VERSION ""

NS_ :

BS_:
BU_: ME SC01 BMS01 BMS PT
VAL_TABLE_ CMBPressureState 1 "ENABLE" 0 "DISABLE" ;
VAL_TABLE_ cmbSM29TempIndex 255 "SNA" ;
VAL_TABLE_ contactorStateRabbit 5 "FAILURE" 4 "CLOSE" 3 "EXT_ISO_TEST" 2 "AUX_CLOSE" 1 "INT_ISO_TEST" 0 "OPEN" ;
VAL_TABLE_ microsarOsStackUsage 255 "SNA" ;
VAL_TABLE_ CoolantFluidLevelEnum 3 "FLUIDLEVEL_ERROR" 2 "FLUIDLEVEL_OIL" 1 "FLUIDLEVEL_AIR" 0 "FLUIDLEVEL_SNA" ;
VAL_TABLE_ EEPROM_BlockStatus 8 "NVM_REQ_RESTORED_FROM_ROM" 7 "NVM_REQ_REDUNDANCY_FAILED" 6 "NVM_REQ_CANCELED" 5 "NVM_REQ_NV_INVALIDATED" 4 "NVM_REQ_BLOCK_SKIPPED" 3 "NVM_REQ_INTEGRITY_FAILED" 2 "NVM_REQ_PENDING" 1 "NVM_REQ_NOT_OK" 0 "NVM_REQ_OK" ;
VAL_TABLE_ PerformanceMode 1 "High Performance" 0 "Normal" ;
VAL_TABLE_ adcDriverFail 12 "ADCDRIVER_SBCSUPPLY_FF" 11 "ADCDRIVER_MUX960_FF" 10 "ADCDRIVER_MUX910_FF" 9 "ADCDRIVER_UNDEF" 8 "ADCDRIVER_ADCVAR" 7 "ADCDRIVER_SLEEP_FF" 6 "ADCDRIVER_PYRO_FF" 5 "ADCDRIVER_MUX710_FF" 4 "ADCDRIVER_MUX440_FF" 3 "ADCDRIVER_MUX302A_FF" 2 "ADCDRIVER_MUX301B_FF" 1 "ADCDRIVER_MUX301A_FF" 0 "ADCDRIVER_NO_ISSUE" ;
VAL_TABLE_ activeIsoTestState 4 "ISOACTV_COMPLETE" 3 "ISOACTV_TIMEOUT" 2 "ISOACTV_PENDING" 1 "ISOACTV_INIT" 0 "ISOACTV_OFF" ;
VAL_TABLE_ pyroStateTable 7 "PYRO_FIRE" 6 "PYRO_DIAG_PASS" 5 "PYRO_DIAG_FAIL" 4 "PYRO_DIAG_LS_ON" 3 "PYRO_DIAG_OPEN" 2 "PYRO_DIAG_HS_ON" 1 "PYRO_DIAG_INIT" 0 "PYRO_INACTIVE" ;
VAL_TABLE_ storeCalibrationOptions 1 "CALIBRATIONS_STORE_PRESENT" 0 "CALIBRATIONS_REVERT_TO_INITIAL" ;
VAL_TABLE_ uint1_t 1 "TRUE" 0 "FALSE" ;
VAL_TABLE_ uint2_t 3 "SNA" ;
VAL_TABLE_ MIL 3 "MIL_SNA" 1 "MIL_ON" 0 "MIL_OFF" ;
VAL_TABLE_ DebugSpeed 3 "DEBUGSPEED_SLOW" 2 "DEBUGSPEED_MEDIUM" 1 "DEBUGSPEED_FAST" 0 "DEBUGSPEED_AUTO" ;
VAL_TABLE_ NMStartupReason 7 "NM_STARTUP_INVALID" 6 "NM_STARTUP_RQ" 5 "NM_STARTUP_CAN" 4 "NM_STARTUP_THERMALEVENT" 3 "NM_STARTUP_AUXCONTACTORS" 2 "NM_STARTUP_CONTACTORS" 1 "NM_STARTUP_KEY" 0 "NM_STARTUP_NOSTARTUP" ;
VAL_TABLE_ OCVRecalibration 255 "OCVRECALIBRATION_INVALID" 1 "OCVRECALIBRATION_ACTIVE" 0 "OCVRECALIBRATION_INACTIVE" ;
VAL_TABLE_ ASCII 90 "'Z'" 89 "'Y'" 88 "'X'" 87 "'W'" 86 "'V'" 85 "'U'" 84 "'T'" 83 "'S'" 82 "'R'" 81 "'Q'" 80 "'P'" 79 "'O'" 78 "'N'" 77 "'M'" 76 "'L'" 75 "'K'" 74 "'J'" 73 "'I'" 72 "'H'" 71 "'G'" 70 "'F'" 69 "'E'" 68 "'D'" 67 "'C'" 66 "'B'" 65 "'A'" 57 "'9'" 56 "'8'" 55 "'7'" 54 "'6'" 53 "'5'" 52 "'4'" 51 "'3'" 50 "'2'" 49 "'1'" 48 "'0'" ;
VAL_TABLE_ contactorType 15 "SNA" 1 "GV240_12V" 0 "GV240_24V" ;
VAL_TABLE_ SOHBrickIndex 4095 "SNA" 4094 "ALL_BRICKS" ;
VAL_TABLE_ SOHType 15 "SNA" 3 "SOH_ALL" 2 "SOHR_REGEN" 1 "SOHR_DCHG" 0 "SOHC" ;
VAL_TABLE_ balancingState 6 "BALANCING_OFF_TEMP_SHUTDOWN" 5 "BALANCING_OFF_VOLTAGE_SHUTDOWN" 4 "BALANCING_ON_DCM_EEPROM" 3 "BALANCING_ON_DCM_BRICK" 2 "BALANCING_ON_DCM_PATTERN" 1 "BALANCING_ON_ME_APP" 0 "BALANCING_OFF" ;
VAL_TABLE_ balancingVoltageTarget 255 "VOLTAGEBASED_BALANCING_INACTIVE" ;
VAL_TABLE_ uint3_t 7 "SNA" ;
VAL_TABLE_ wakeReasonEnum 14 "ECU_WAKEREASON_INIT" 15 "ECU_WAKEREASON_UNKNOWN" 5 "ECU_WAKEREASON_AUTO" 4 "ECU_WAKEREASON_POR" 3 "ECU_WAKEREASON_CLOCK" 2 "ECU_WAKEREASON_PRESSURE" 1 "ECU_WAKEREASON_CAN" 0 "ECU_WAKEREASON_KEY" ;
VAL_TABLE_ contactorControl 4 "CTRCTRL_CTRFAIL" 3 "CTRCTRL_CTRON" 2 "CTRCTRL_CTRCHECK" 1 "CTRCTRL_ADDITIONAL_CTRCHECK" 0 "CTRCTRL_CTROFF" ;
VAL_TABLE_ itemState2Bits 3 "ITEM_INVALID" 2 "ITEM_EMERGENCY" 1 "ITEM_OFF" 0 "ITEM_ON" ;
VAL_TABLE_ batSwitchOpenRequest 3 "INVALID" 2 "IMMEDIATE_OPEN" 1 "FAST_OPEN" 0 "DO_NOT_OPEN" ;
VAL_TABLE_ ContactorControlTestSequenceEnum 8 "CTRCTRL_CHKLOSIDE_OPEN_CIRC" 7 "CTRCTRL_FAILED" 6 "CTRCTRL_PASSED" 5 "CTRCTRL_CHKHISIDE_STUCK_OPEN" 4 "CTRCTRL_CHK_CLOSE_OK_CIRCUIT" 3 "CTRCTRL_CHKLOSIDE_STUCK_CLOSED" 2 "CTRCTRL_CHKHISIDE_STUCK_CLOSED" 1 "CTRCTRL_PENDING" 0 "CTRCTRL_INIT" ;
VAL_TABLE_ uin12_t 4095 "SNA" ;
VAL_TABLE_ CMBStepsEnum 17 "CMB_HDC_2" 16 "CMB_HDC_1" 15 "CMB_SM12_2" 14 "CMB_SM12_1" 13 "CMB_SM11" 12 "CMB_SM9" 11 "CMB_SM7" 10 "CMB_SM6_2" 9 "CMB_SM6_1" 8 "CMB_SM5" 7 "CMB_SM4_2" 6 "CMB_SM4_1" 5 "CMB_SM3" 4 "CMB_SM3_2" 3 "CMB_SM2_2" 2 "CMB_SM2_1" 1 "CMB_SM1" 0 "CMB_WAKE" ;
VAL_TABLE_ CurrentShortCircuitEnum 1 "CURRENT_SHORTCIRCUIT_ACTIVE" 0 "CURRENT_SHORTCIRCUIT_INACTIVE" ;
VAL_TABLE_ NMNetworkModesEnum 2 "NM_MODE_READY_SLEEP" 1 "NM_MODE_NORMAL_OPERATION" 0 "NM_MODE_REPEAT_MESSAGE" ;
VAL_TABLE_ NMOperationalModeEnum 2 "NM_BUSSLEEP_MODE" 1 "NM_PREPAREBUSSLEEP_MODE" 0 "NM_NETWORK_MODE" ;
VAL_TABLE_ NMNetworkStatesEnum 1 "NM_STATE_REQUESTED" 0 "NM_STATE_RELEASED" ;
VAL_TABLE_ ecuState 4 "ECU_SLEEPING" 3 "ECU_GOING_TO_SLEEP" 2 "ECU_AWAKE_CAN_ACTIVE" 1 "ECU_AWAKE_CAN_INACTIVE" 0 "ECU_INIT" ;
VAL_TABLE_ SPIRxTxDiagnosticStatusEnum 3 "SPIRXTX_SLAVEREQUESTPACKAGE" 2 "SPIRXTX_CRC" 1 "SPIRXTX_WRONG_PACKETINDEX" 0 "SPIRXTX_ALL_OK" ;
VAL_TABLE_ canBusOffState_BMS01 3 "SNA" 2 "CAN_BUSOFF_PHASE2" 1 "CAN_BUSOFF_PHASE1" 0 "CAN_BUSOFF_NORMAL" ;
VAL_TABLE_ strMstrStrPrechgState 7 "NOT_A_STRING_MASTER" 6 "STRING_PRCHG_NDEF2" 5 "STRING_PRCHG_NDEF1" 4 "STRING_PRCHG_FAULT" 3 "STRING_ON" 2 "STRING_PRCHG_ACTV" 1 "STRING_PRCHG_INIT" 0 "STRING_PRCHG_OFF" ;
VAL_TABLE_ cmbFilterMode_ME 3 "CMB_FILTERMD_440HZ" 2 "CMB_FILTERMD_1KHZ" 1 "CMB_FILTERMD_3KHZ" 0 "CMB_FILTERMD_7KHZ" ;
VAL_TABLE_ weldCheckState_SC01 4 "WELDCHECK_IDLE" 3 "WELDCHECK" 2 "WELDCHECK_ISO_2" 1 "WELDCHECK_ISO_1" 0 "WELDCHECK_INIT" ;
VAL_TABLE_ SPIRxTxTransmitResetReasonEnum 3 "SPIRXTX_TIMER" 2 "SPIRXTX_ITEMSTATE" 1 "SPIRXTX_CMBDATA" 0 "SPIRXTX_NORESET" ;
VAL_TABLE_ MonacoQual 1 "QUAL_ERROR" 0 "QUAL_VALID" ;
VAL_TABLE_ SBCWakeUpEnum 6 "SBC_CAN" 5 "SBC_PHY" 4 "SBC_LDT" 3 "SBC_PRESSURE" 2 "SBC_KEY" 1 "SBC_POR" 0 "SBC_UNKNOWN" ;
VAL_TABLE_ weldedState 3 "CTR_NEG1_WELDED" 2 "CTR_POS1_WELDED" 0 "CTR_NOTWELDED" 1 "CTR_BOTH_WELDED" ;
VAL_TABLE_ debugFastMpexSC 1 "DBGSC_ANALOG" 0 "DBGSC_DIGITALIO" ;
VAL_TABLE_ eepromResetStruct 171 "EEPROM_INVALIDATE_ALLBLOCKS" 170 "EEPROM_RESET_ALLBLOCKS" 8 "EEPROM_RESET_CHRONOSTACK" 7 "EEPROM_RESET_UDSDATA" 6 "EEPROM_RESET_CUSTDATA" 4 "EEPROM_RESET_SOH" 3 "EEPROM_RESET_SOC" 2 "EEPROM_RESET_DIAGDATA" 1 "EEPROM_RESET_BASICDATA" ;
VAL_TABLE_ uint4_t 15 "SNA" ;
VAL_TABLE_ isoSwRequestCommand 255 "SW_NOCONTROL" 1 "SW_ON" 0 "SW_OFF" ;
VAL_TABLE_ eepromFailTypes 13 "EEPROMFAIL_DIAGDATA_WCYCLES" 12 "EEPROMFAIL_BAD_WRITE_ADDRESS" 11 "EEPROMFAIL_SLEEP_TIMEOUT" 10 "EEPROMFAIL_RAM_ADDRESS_BUG" 9 "EEPROM_DRIVER_READQUEUE_FULL" 8 "EEPROM_DRIVER_WRITEQUEUE_FULL" 7 "EEPROM_MIBSPI_TIMEOUT" 6 "EEPROM_NOTREADY_TIMEOUT" 5 "EEPROM_FAIL_CRC_COPY2" 4 "EEPROM_FAIL_VERSION_COPY2" 3 "EEPROM_FAIL_CRC_COPY1" 2 "EEPROM_FAIL_VERSION_COPY1" 1 "EEPROM_FAIL_UNDEFINED" 0 "EEPROM_FAIL_UNDEFINED" ;
VAL_TABLE_ eepromAddressTable 12 "EEPROM_SERIALNUMBER_5" 8 "EEPROM_SERIALNUMBER_0" 4272 "EEPROMADR_SOCMIRROR" 1760 "EEPROMADR_DEMEVENTS" 4976 "EEPROMADR_DEMEVENTSMIRROR" 4096 "EEPROMADR_BASICDATAMIRROR" 1056 "EEPROMADR_SOC" 0 "EEPROMADR_BASICDATA" ;
VAL_TABLE_ eepromStructs 4 "eepromResetSoH" 65535 "eepromNone" 3 "eepromResetSoC" 2 "eepromResetHistograms" 1 "eepromResetBasicData" 0 "eepromReserved" ;
VAL_TABLE_ commandMultiplexerTable 8 "DbgEEPROMWriteBMSSerial2" 7 "DbgEEPROMWriteBMSSerial1" 6 "DbgEEPROMReadWords" 5 "DbgEEPROMWriteWords" 4 "DbgEEPROMWriteByte" 3 "DbgUndefined" 2 "DbgBalancingPatternHeater" 1 "DbgCtrBalancing" 0 "DbgUndefined" ;
VAL_TABLE_ rangeRequest 7 "RANGE_MAXIMUM" 6 "RANGE_LIMITED6" 5 "RANGE_LIMITED5" 4 "RANGE_LIMITED4" 3 "RANGE_LIMITED3" 2 "RANGE_LIMITED2" 1 "RANGE_LIMITED1" 0 "RANGE_SHIPPING" ;
VAL_TABLE_ uint32_t -1 "SNA" ;
VAL_TABLE_ eltekChargerStatus 4 "ELTEK_NONRECOVERABLE_ERROR" 3 "ELTEK_RECOVERABLE_ERROR" 2 "ELTEK_CHARGE" 1 "ELTEK_IDLE" 0 "ELTEK_OFF" ;
VAL_TABLE_ ChargeManagerChargeStateEnum 15 "CHARGESTATE_INVALID" 1 "CHARGESTATE_COMPLETE" 0 "CHARGESTATE_NOTCOMPLETE" ;
VAL_TABLE_ ChargeManagerConnectionStateEnum 3 "CHARGEMANAGER_FULL_CONNECTION_DC" 2 "CHARGEMANAGER_FULL_CONNECTION_AC" 1 "CHARGEMANAGER_PARTIAL_CONNECTION" 0 "CHARGEMANAGER_NO_CONNECTION" ;
VAL_TABLE_ StringStateManagerPrechargeState 15 "STRING_NOT_EXISTING" 5 "STRING_WILL_OPEN_SOON" 4 "STRING_ON" 3 "STRING_PAUSED" 2 "STRING_CLOSING" 1 "STRING_INDEFINED" 0 "STRING_OFF" ;
VAL_TABLE_ Contactors_weldState 0 "NOTWELDED" 1 "WELDED" ;
VAL_TABLE_ enumeration 32 "32" 31 "31" 30 "30" 29 "29" 28 "28" 27 "27" 26 "26" 25 "25" 24 "24" 23 "23" 22 "22" 21 "21" 20 "20" 19 "19" 18 "18" 17 "17" 16 "16" 15 "15" 14 "14" 13 "13" 12 "12" 11 "11" 10 "10" 9 "09" 8 "08" 7 "07" 6 "06" 5 "05" 4 "04" 3 "03" 2 "02" 1 "01" 0 "00" ;
VAL_TABLE_ itemState 15 "ITEM_INVALID" 2 "ITEM_EMERGENCY" 1 "ITEM_OFF" 0 "ITEM_ON" ;
VAL_TABLE_ safeState 1 "SAFESTATE_UNSAFE" 0 "SAFESTATE_SAFE" ;
VAL_TABLE_ isolationTestState 3 "ISOLATION_DISABLED" 2 "ISOLATION_TEST_NEG" 1 "ISOLATION_TEST_POS" 0 "ISOLATION_OFF" ;
VAL_TABLE_ prechargeState 10 "CTR_PRCHG_CLOSEMID" 9 "CTR_PRCHG_CLOSEAUX" 8 "CTR_PRCHG_FAILED" 7 "CTR_PRCHG_COMPLETE" 6 "CTR_PRCHG_CLOSE_POS" 5 "CTR_PRCHG_MONITOR_VOLTAGE" 4 "CTR_PRCHG_CLOSE_NEG" 3 "CTR_PRCHG_NEG_WELD_CHECK" 2 "CTR_PRCHG_CLOSE_RELAY" 1 "CTR_PRCHG_WELD_CHECK" 0 "CTR_PRCHG_OFF" ;
VAL_TABLE_ contactorState 4 "CTR_INVALID" 3 "CTR_STRING_OPENING" 2 "CTR_STRING_ON" 1 "CTR_STRING_PRECHARGE" 0 "CTR_STRING_OFF" ;
VAL_TABLE_ multiplexer301_VT 3 "CH3_GND" 2 "CH2_HALL_SENSE" 1 "CH1_HALL_5VSUPPLY" 0 "CH0_2V877_REF" ;
VAL_TABLE_ clockRequestCommand 255 "CLOCK_NOCOMMAND" 1 "CLOCK_LOW" 0 "CLOCK_HIGH" ;
VAL_TABLE_ sleepRequestCommand 255 "SLEEP_NOCOMMAND" 1 "SLEEP_ON" 0 "SLEEP_OFF" ;
VAL_TABLE_ uint8_tCommand 255 "NOCOMMAND" ;
VAL_TABLE_ uint24_tCommand 16777215 "NOCOMMAND" ;
VAL_TABLE_ contactorRequestCommand 255 "CONTACTOR_NOCONTROL" 1 "CONTACTOR_ON" 0 "CONTACTOR_OFF" ;
VAL_TABLE_ chargeState 2 "CHARGESTATE_INVALID" 1 "CHARGESTATE_COMPLETE" 0 "CHARGESTATE_NOTCOMPLETE" ;
VAL_TABLE_ VEH_stateRequest 2 "STATE_DRIVE" 15 "STATE_INVALID" 1 "STATE_DRIVE" 0 "STATE_STANDBY" ;
VAL_TABLE_ DEMStatus 3 "DEM_INVALID" 2 "DEM_FAILED" 1 "DEM_PASSED" 0 "DEM_NOTTESTED" ;
VAL_TABLE_ sleepRequest 15 "SLEEP_INVALID" 1 "SLEEP_ACTIVE" 0 "SLEEP_INACTIVE" ;
VAL_TABLE_ isolationRequest 15 "ISOLATION_INVALID" 1 "ISOLATION_ACTIVE" 0 "ISOLATION_INACTIVE" ;
VAL_TABLE_ state 15 "STATE_INVALID" 6 "STATE_SYSTEM_FAULT" 5 "STATE_STRING_FAULT" 4 "STATE_LIMPHOME" 3 "STATE_ACCESSORY" 2 "STATE_CHARGE" 1 "STATE_DRIVE" 0 "STATE_STANDBY" ;
VAL_TABLE_ state3Bits 7 "STATE_INVALID" 6 "STATE_SYSTEM_FAULT" 5 "STATE_STRING_FAULT" 4 "STATE_LIMPHOME" 3 "STATE_ACCESSORY" 2 "STATE_CHARGE" 1 "STATE_DRIVE" 0 "STATE_STANDBY" ;
VAL_TABLE_ packShutdownTargetState 3 "BMS_INVALID" 1 "BMS_STRING_FAULT" 0 "BMS_STANDBY" ;
VAL_TABLE_ uint8_t 255 "SNA" ;
VAL_TABLE_ uint16_t 65535 "SNA" ;
VAL_TABLE_ emergencyState 1 "EMERGENCY_STATE_ACTIVE" 15 "EMERGENCY_STATE_INVALID" 0 "EMERGENCY_STATE_INACTIVE" ;
VAL_TABLE_ packShutdwnTmrQual 0 "SHUTDOWN_ACTIVE" 1 "SHUTDOWN_INACTIVE" ;

VAL_TABLE_ individualCntrStateValueTable 3 "CTR_INVALID" 1 "CTR_ON" 0 "CTR_OFF" ;
VAL_TABLE_ wakeUpMultTable 5 "WAKEUP_EEPROM_READ_COMPLETE" 3 "WAKEUP_ECU_STATE_CHANGE" 2 "WAKEUP_EEPROM_WRITE_COMPLETE" 1 "WAKEUP_EEPROM_WRITE_START" 0 "WAKEUP_NONE" ;
VAL_TABLE_ uint4_t 15 "SNA" ;
VAL_TABLE_ uint8_t 255 "SNA" ;
VAL_TABLE_ uint16_t 65535 "SNA" ;
VAL_TABLE_ uint24_t 16777215 "SNA" ;
VAL_TABLE_ eepromAddressTable 176 "EEPROMADR_DIAG" 4272 "EEPROMADR_DIAGMIRROR" 5152 "EEPROMADR_SOCMIRROR" 1760 "EEPROMADR_DEMEVENTS" 5856 "EEPROMADR_DEMEVENTSMIRROR" 4096 "EEPROMADR_BASICDATAMIRROR" 1056 "EEPROMADR_SOC" 0 "EEPROMADR_BASICDATA" ;
VAL_TABLE_ ecuStateValueTable 0 "ECU_INIT" 1 "ECU_AWAKE_CAN_INACTIVE" 2 "ECU_AWAKE_CAN_ACTIVE" 3 "ECU_GOING_TO_SLEEP" 4 "ECU_SLEEPING" ;
BO_ 896 BMS01_DebugEventMap10: 8 BMS01
 SG_ DEM319_HV_DISABLE_DURING_S_BMS01 : 55|2@0+ (1,0) [0|3] ""  PT
 SG_ DEM318_HV_ENABLE_IMPLAUSIB_BMS01 : 53|2@0+ (1,0) [0|3] ""  PT
 SG_ DEM317_STRING_SUSPECT_OPEN_BMS01 : 51|2@0+ (1,0) [0|3] ""  PT
 SG_ DEM316_UNEXPCTD_BMS_ON_CAN_BMS01 : 49|2@0+ (1,0) [0|3] ""  PT
 SG_ DEM315_HV_WITHSTAND_TESTS__BMS01 : 63|2@0+ (1,0) [0|3] ""  PT
 SG_ DEM314_OBC_PILOT_ERROR_BMS01 : 61|2@0+ (1,0) [0|3] ""  PT
 SG_ DEM313_OBC_PILOT_HIGH_BMS01 : 59|2@0+ (1,0) [0|3] ""  PT
 SG_ DEM312_OBC_PROXIMITY_ERROR_BMS01 : 57|2@0+ (1,0) [0|3] ""  PT
 SG_ DEM311_CTRS_END_OF_LIFE_WA_BMS01 : 39|2@0+ (1,0) [0|3] ""  PT
 SG_ DEM310_BMSMIA_STRNGMSTR_AL_BMS01 : 37|2@0+ (1,0) [0|3] ""  PT
 SG_ DEM309_VOLTAGE_BRICKOV_WAR_BMS01 : 35|2@0+ (1,0) [0|3] ""  PT
 SG_ DEM308_PRESSURE_FLT_BMS01 : 33|2@0+ (1,0) [0|3] ""  PT
 SG_ DEM307_PRESSURE_MIA_BMS01 : 47|2@0+ (1,0) [0|3] ""  PT
 SG_ DEM306_SW_VERSION_MISMATCH_BMS01 : 45|2@0+ (1,0) [0|3] ""  PT
 SG_ DEM305_MODULET_OVERTEMP_WA_BMS01 : 43|2@0+ (1,0) [0|3] ""  PT
 SG_ DEM304_PCHG_OPENCIRCUIT_IN_BMS01 : 41|2@0+ (1,0) [0|3] ""  PT
 SG_ DEM303_MODULET_UNDERTEMP_W_BMS01 : 23|2@0+ (1,0) [0|3] ""  PT
 SG_ DEM302_MODULET_UT_BMS01 : 21|2@0+ (1,0) [0|3] ""  PT
 SG_ DEM301_FUSI_LOCK_BMS01 : 19|2@0+ (1,0) [0|3] ""  PT
 SG_ DEM300_DEBUG_SM_DISABLED_BMS01 : 17|2@0+ (1,0) [0|3] ""  PT
 SG_ DEM299_5V_SENSOR_SUPPLY_OU_BMS01 : 31|2@0+ (1,0) [0|3] ""  PT
 SG_ DEM298_IMPL_DRIVE_REQUEST_BMS01 : 29|2@0+ (1,0) [0|0] ""  PT
 SG_ DEM297_PCHG2_OPENCIRCUIT_BMS01 : 27|2@0+ (1,0) [0|0] ""  PT
 SG_ DEM296_CTRSAUX_IMPLAUSIBLE_BMS01 : 25|2@0+ (1,0) [0|0] ""  PT
 SG_ DEM295_CTRSAUX_LINKV_UNSAF_BMS01 : 7|2@0+ (1,0) [0|0] ""  PT
 SG_ DEM294_CANRX_PT_EMERGENCY_BMS01 : 5|2@0+ (1,0) [0|0] ""  PT
 SG_ DEM293_SBC_LDT_IMPLAUSIBLE_BMS01 : 3|2@0+ (1,0) [0|0] ""  PT
 SG_ DEM292_NUM_EXPECTED_STRING_BMS01 : 1|2@0+ (1,0) [0|0] ""  PT
 SG_ DEM291_NUM_EXPECTED_STRING_BMS01 : 15|2@0+ (1,0) [0|0] ""  PT
 SG_ DEM290_CMB_ONBOARD_DEFECT_BMS01 : 13|2@0+ (1,0) [0|0] ""  PT
 SG_ DEM289_TEMP_STATE_LATCHED_BMS01 : 11|2@0+ (1,0) [0|0] ""  PT
 SG_ DEM288_CURR_STATE_LATCHED_BMS01 : 9|2@0+ (1,0) [0|0] ""  PT

BO_ 960 BMS01_DebugSlowMpex2: 8 BMS01
 SG_ balancingInDriveTimer_BMS01 m18 : 15|16@0+ (1,0) [0|65535] "s"  PT
 SG_ SOCRestPolarization_BMS01 m11 : 63|8@0+ (0.002,0) [0|0.51] "V"  PT
 SG_ CoolantSensorState_BMS01 m1 : 51|2@0+ (1,0) [0|1] ""  PT
 SG_ temperatureModelOffset_BMS01 m7 : 15|8@0+ (0.1,0) [0|25.5] "C"  PT
 SG_ SOHCMinBrickHighEst_BMS01 m4 : 15|8@0+ (0.3,50) [50|126.5] "PCT"  PT
 SG_ SOHCMaxBrickHighEst_BMS01 m6 : 15|8@0+ (0.3,50) [50|126.5] "PCT"  PT
 SG_ regenCurrOpLkyBktThrs1_BMS01 m17 : 63|8@0+ (0.5,0) [0|127.5] "PCT"  PT
 SG_ dischargeCurrOpLkyBktThrs1_BMS01 m10 : 15|8@0+ (0.5,0) [0|127.5] "PCT"  PT
 SG_ regenCurrentOpLoadValue_BMS01 m16 : 15|8@0+ (0.5,0) [0|127.5] "PCT"  PT
 SG_ dischargeCurrOpLoadValue_BMS01 m15 : 15|8@0+ (0.5,0) [0|127.5] "PCT"  PT
 SG_ minBrickVoltageLimit_BMS01 m16 : 55|16@0+ (0.0001,0) [0|6.5535] "V"  PT
 SG_ SOHSuitableOCVRecal_BMS01 m1 : 49|1@0+ (1,0) [0|1] ""  PT
 SG_ currentModule3Integral_BMS01 m17 : 47|16@0+ (100,-3200000) [-3200000|3353500] "As"  PT
 SG_ currentModule2Integral_BMS01 m17 : 31|16@0+ (100,-3200000) [-3200000|3353500] "As"  PT
 SG_ currentModule1Integral_BMS01 m17 : 15|16@0+ (100,-3200000) [-3200000|3353500] "As"  PT
 SG_ currentModuleMin_BMS01 m16 : 23|16@0+ (0.1,-3200) [-3200|3200] "A"  PT
 SG_ currentModuleMax_BMS01 m16 : 39|16@0+ (0.1,-3200) [-3200|3200] "A"  PT
 SG_ maxBrickVoltageSync_BMS01 m9 : 39|16@0+ (0.0001,0) [0|6.5] "V"  PT
 SG_ minBrickVoltageSync_BMS01 m9 : 55|16@0+ (0.0001,0) [0|6.5] "V"  PT
 SG_ SOHCMinBrickLowEst_BMS01 m8 : 15|8@0+ (0.3,50) [50|126.5] "PCT"  PT
 SG_ SOHCMaxBrickLowEst_BMS01 m9 : 15|8@0+ (0.3,50) [50|126.5] "PCT"  PT
 SG_ gradLimSOC_BMS01 m10 : 39|16@0+ (0.002,0) [0|131.07] "PCT"  PT
 SG_ SOCRecalSlowOp_BMS01 m14 : 55|16@0+ (0.0001,-2) [-2|4.5535] "V"  PT
 SG_ SOHCMinIndex_BMS01 m12 : 39|16@0+ (1,0) [0|65535] ""  PT
 SG_ SOHCMaxIndex_BMS01 m12 : 55|16@0+ (1,0) [0|65535] ""  PT
 SG_ SOHRMinRegen_BMS01 m11 : 39|8@0+ (1,50) [50|305] "PCT"  PT
 SG_ SOHRMinDchg_BMS01 m11 : 15|8@0+ (1,50) [50|305] "PCT"  PT
 SG_ SOHRMeanRegen_BMS01 m11 : 47|8@0+ (1,50) [50|305] "PCT"  PT
 SG_ SOHRMeanDchg_BMS01 m11 : 23|8@0+ (1,50) [50|305] "PCT"  PT
 SG_ SOHRMaxRegen_BMS01 m11 : 55|8@0+ (1,50) [50|305] "PCT"  PT
 SG_ SOHRMaxDchg_BMS01 m11 : 31|8@0+ (1,50) [50|305] "PCT"  PT
 SG_ SOHCMin_BMS01 m12 : 15|8@0+ (0.3,50) [50|126.5] "PCT"  PT
 SG_ SOHCMean_BMS01 m12 : 23|8@0+ (0.3,50) [50|126.5] "PCT"  PT
 SG_ SOHCMax_BMS01 m12 : 31|8@0+ (0.3,50) [50|126.5] "PCT"  PT
 SG_ ppRegenCurrLimitPredShort_BMS01 m6 : 23|8@0+ (2,0) [0|510] "A"  PT
 SG_ ppRegenCurrLimitPredLong_BMS01 m6 : 31|8@0+ (2,0) [0|510] "A"  PT
 SG_ ppDchgCurrLimitPredShort_BMS01 m13 : 55|8@0+ (2,-510) [-510|0] "A"  PT
 SG_ ppDchgCurrLimitPredLong_BMS01 m13 : 63|8@0+ (2,-510) [-510|0] "A"  PT
 SG_ ppInconsistentPol_BMS01 m1 : 48|1@0+ (1,0) [0|0] ""  PT
 SG_ ppPolarizationV_BMS01 m3 : 55|16@0+ (0.0001,-3) [-3|3.5535] "V"  PT
 SG_ SOCRecalMinOCVEst_BMS01 m13 : 39|16@0+ (0.0001,0) [0|6.5535] "V"  PT
 SG_ SOCRecalMaxOCVEst_BMS01 m14 : 39|16@0+ (0.0001,0) [0|6.5535] "V"  PT
 SG_ SOCRecalMinSOCUpp_BMS01 m13 : 31|8@0+ (0.5,0) [0|127.5] "PCT"  PT
 SG_ SOCRecalMinSOCLow_BMS01 m13 : 15|8@0+ (0.5,0) [0|127.5] "PCT"  PT
 SG_ SOCRecalMinSOC_BMS01 m13 : 23|8@0+ (0.5,0) [0|127.5] "PCT"  PT
 SG_ SOCRecalMaxSOCUpp_BMS01 m14 : 31|8@0+ (0.5,0) [0|127.5] "PCT"  PT
 SG_ SOCRecalMaxSOCLow_BMS01 m14 : 15|8@0+ (0.5,0) [0|127.5] "PCT"  PT
 SG_ SOCRecalMaxSOC_BMS01 m14 : 23|8@0+ (0.5,0) [0|127.5] "PCT"  PT
 SG_ ppNewtonRootInRangeRegen_BMS01 m5 : 12|1@0+ (1,0) [0|0] ""  PT
 SG_ ppNewtonRootInRangeDchg_BMS01 m5 : 8|1@0+ (1,0) [0|0] ""  PT
 SG_ ppNewtonStepsRegen_BMS01 m5 : 15|3@0+ (1,0) [0|1] ""  PT
 SG_ ppNewtonStepsDchg_BMS01 m5 : 11|3@0+ (1,0) [0|1] ""  PT
 SG_ ppNewtonRegenVRes_BMS01 m5 : 31|8@0+ (0.001,-0.1) [-0.1|0.155] "V"  PT
 SG_ ppNewtonDchgVRes_BMS01 m5 : 23|8@0+ (0.001,-0.1) [-0.1|0.155] "V"  PT
 SG_ ppMinModelAlphaTarget_BMS01 m3 : 15|8@0+ (0.02,0) [0|5.1] ""  PT
 SG_ ppMaxModelAlphaTarget_BMS01 m1 : 63|8@0+ (0.02,0) [0|5.1] ""  PT
 SG_ ppLearningTauRegen_BMS01 m2 : 55|16@0+ (0.2,0) [0|0] "s"  PT
 SG_ ppLearningCriterionDyn_BMS01 m2 : 15|8@0+ (0.005,0) [0|0] ""  PT
 SG_ ppLearningCriterionAbs_BMS01 m1 : 15|8@0+ (0.005,0) [0|0] ""  PT
 SG_ ppLearningCriterionJoin_BMS01 m0 : 15|8@0+ (0.005,0) [0|0] ""  PT
 SG_ ppMaxModelMeasV_BMS01 m7 : 23|16@0+ (0.0001,0) [0|6.5535] "V"  PT
 SG_ currentRedundant_BMS01 m15 : 23|16@0+ (0.1,-3200) [-3200|3200] "A"  PT
 SG_ currentModule3_BMS01 m10 : 55|16@0+ (0.1,-3200) [-3200|3200] "A"  PT
 SG_ currentModule2_BMS01 m10 : 23|16@0+ (0.1,-3200) [-3200|3200] "A"  PT
 SG_ currentModule1_BMS01 m9 : 23|16@0+ (0.1,-3200) [-3200|3200] "A"  PT
 SG_ ppMeanRegenIntRes_BMS01 m6 : 55|16@0+ (0.01,0) [0|655.35] "mOhm"  PT
 SG_ ppMeanDchgIntRes_BMS01 m6 : 39|16@0+ (0.01,0) [0|655.35] "mOhm"  PT
 SG_ ppMinModelVoltageIndex_BMS01 m5 : 39|16@0+ (1,0) [0|65535] ""  PT
 SG_ ppMinModelLowpassV_BMS01 m4 : 55|16@0+ (0.0001,0) [0|0] "V"  PT
 SG_ ppMaxModelVoltageIndex_BMS01 m5 : 55|16@0+ (1,0) [0|65535] ""  PT
 SG_ ppMaxModelLowpassV_BMS01 m7 : 55|16@0+ (0.0001,0) [0|0] "V"  PT
 SG_ ppLearningTauDischarge_BMS01 m0 : 55|16@0+ (0.2,0) [0|0] "s"  PT
 SG_ ppMaxRegenAlpha_BMS01 m15 : 39|16@0+ (0.0001,0) [0|6.5535] ""  PT
 SG_ ppMaxModelledV_BMS01 m7 : 39|16@0+ (0.0001,0) [0|6.5535] "V"  PT
 SG_ ppMinDchgAlpha_BMS01 m15 : 55|16@0+ (0.0001,0) [0|6.5535] ""  PT
 SG_ ppMinModelledV_BMS01 m4 : 39|16@0+ (0.0001,0) [0|6.5535] "V"  PT
 SG_ ppMinModelMeasV_BMS01 m4 : 23|16@0+ (0.0001,0) [0|6.5535] "V"  PT
 SG_ debugSlowMpex2_BMS01 M : 7|8@0+ (1,0) [0|0] ""  PT
 SG_ ppRegenCurrPredShort_BMS01 m2 : 23|16@0+ (0.02,0) [0|1310.7] "A"  PT
 SG_ ppDischgCurrPredLong_BMS01 m0 : 39|16@0+ (0.05,-3200) [-3200|0] "A"  PT
 SG_ ppDischgCurrPredShort_BMS01 m0 : 23|16@0+ (0.05,-3200) [-3200|0] "A"  PT
 SG_ ppRegenCurrPredLong_BMS01 m2 : 39|16@0+ (0.02,0) [0|1310.7] "A"  PT
 SG_ ppRegenVPredShort_BMS01 m3 : 23|16@0+ (0.02,0) [0|1310.7] "V"  PT
 SG_ ppDischgVPredShort_BMS01 m1 : 23|16@0+ (0.02,0) [0|1310.7] "V"  PT
 SG_ ppRegenVPredLong_BMS01 m3 : 39|16@0+ (0.02,0) [0|1310.7] "V"  PT
 SG_ ppDischgVPredLong_BMS01 m1 : 39|16@0+ (0.02,0) [0|1310.7] "V"  PT
 SG_ SOHDeltaSOCCoulomb_BMS01 m8 : 23|16@0+ (0.005,-150) [-150|177.675] "PCT"  PT
 SG_ SOHAbsDeltaSOCCoulomb_BMS01 m8 : 39|16@0+ (0.05,0) [0|3276.75] "PCT"  PT
 SG_ SOHLastOCVRecalMinSOC_BMS01 m8 : 55|8@0+ (0.393,0) [0|100.215] "PCT"  PT
 SG_ SOHbalancingTimeMinSOH_BMS01 m8 : 63|8@0+ (1,0) [0|255] "Min"  PT

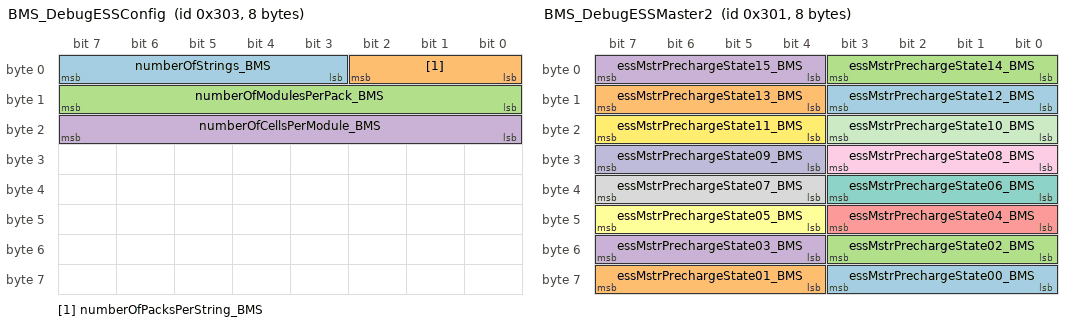
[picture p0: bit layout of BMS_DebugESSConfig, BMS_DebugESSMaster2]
BO_ 771 BMS_DebugESSConfig: 8 BMS
 SG_ numberOfStrings_BMS : 7|5@0+ (1,0) [0|0] ""  PT
 SG_ numberOfPacksPerString_BMS : 2|3@0+ (1,0) [0|0] ""  PT
 SG_ numberOfModulesPerPack_BMS : 15|8@0+ (1,0) [0|0] ""  PT
 SG_ numberOfCellsPerModule_BMS : 23|8@0+ (1,0) [0|0] ""  PT

BO_ 1792 BMS01_DebugFastMpex2: 8 BMS01
 SG_ chargerDCOutV_BMS01 m1 : 55|16@0+ (0.04,-1250) [-1250|1250] "V"  PT
 SG_ DIGIO_CHARGERCC_BMS01 m1 : 10|1@0+ (1,0) [0|0] ""  PT
 SG_ chargerProximity_BMS01 m1 : 23|8@0+ (0.02,0) [0|12] "V"  PT
 SG_ chargerPilot_BMS01 m1 : 31|8@0+ (0.05,0) [0|12.75] "V"  PT
 SG_ chargerCurrAvail_BMS01 m1 : 39|8@0+ (0.5,0) [0|127.5] "A"  PT
 SG_ chargerCtrOn_BMS01 m1 : 8|1@0+ (1,0) [0|0] ""  PT
 SG_ chargerOn_BMS01 m1 : 9|1@0+ (1,0) [0|0] ""  PT
 SG_ debugFastMpex2_BMS01 M : 7|8@0+ (1,0) [0|0] ""  PT
 SG_ posPackDbg_BMS01 m0 : 39|16@0+ (0.04,-1250) [-1250|1250] "V"  PT
 SG_ negPackDbg_BMS01 m0 : 55|16@0+ (0.04,-1250) [-1250|1250] "V"  PT
 SG_ packVoltageHVMeas_BMS01 m0 : 23|16@0+ (0.04,-1250) [-1250|1250] "V"  PT

BO_ 769 BMS_DebugESSMaster2: 8 BMS
 SG_ essMstrPrechargeState00_BMS : 59|4@0+ (1,0) [0|15] ""  PT
 SG_ essMstrPrechargeState01_BMS : 63|4@0+ (1,0) [0|15] ""  PT
 SG_ essMstrPrechargeState02_BMS : 51|4@0+ (1,0) [0|15] ""  PT
 SG_ essMstrPrechargeState03_BMS : 55|4@0+ (1,0) [0|15] ""  PT
 SG_ essMstrPrechargeState04_BMS : 43|4@0+ (1,0) [0|15] ""  PT
 SG_ essMstrPrechargeState05_BMS : 47|4@0+ (1,0) [0|15] ""  PT
 SG_ essMstrPrechargeState06_BMS : 35|4@0+ (1,0) [0|15] ""  PT
 SG_ essMstrPrechargeState07_BMS : 39|4@0+ (1,0) [0|15] ""  PT
 SG_ essMstrPrechargeState08_BMS : 27|4@0+ (1,0) [0|15] ""  PT
 SG_ essMstrPrechargeState09_BMS : 31|4@0+ (1,0) [0|15] ""  PT
 SG_ essMstrPrechargeState10_BMS : 19|4@0+ (1,0) [0|15] ""  PT
 SG_ essMstrPrechargeState11_BMS : 23|4@0+ (1,0) [0|15] ""  PT
 SG_ essMstrPrechargeState12_BMS : 11|4@0+ (1,0) [0|15] ""  PT
 SG_ essMstrPrechargeState13_BMS : 15|4@0+ (1,0) [0|15] ""  PT
 SG_ essMstrPrechargeState14_BMS : 3|4@0+ (1,0) [0|15] ""  PT
 SG_ essMstrPrechargeState15_BMS : 7|4@0+ (1,0) [0|15] ""  PT

BO_ 1856 BMS01_DebugSlowMpex1: 8 BMS01
 SG_ SOHRecentChange_BMS01 m43 : 15|8@0+ (0.1,-15) [-15|10.5] ""  PT
 SG_ SOHConvergenceIndicator_BMS01 m43 : 31|8@0+ (1,0) [0|255] ""  PT
 SG_ SOHConvergenceCounter_BMS01 m43 : 39|8@0+ (0.024,3) [0|6] ""  PT
 SG_ SOHMinFiltered_BMS01 m43 : 23|8@0+ (0.3,50) [50|126.5] "PCT"  PT
 SG_ prechargeCyMatchWaitTime_BMS01 m43 : 47|16@0+ (1,0) [0|65535] "ms"  PT
 SG_ medianModuleTempGrp2_BMS01 m13 : 63|8@0+ (1,-40) [-40|200] "C"  PT
 SG_ medianModuleTempGrp1_BMS01 m13 : 55|8@0+ (1,-40) [-40|200] "C"  PT
 SG_ coolantWarningtAlert_BMS01 m12 : 49|2@0+ (1,0) [0|3] ""  PT
 SG_ coolantFaultAlert_BMS01 m12 : 51|2@0+ (1,0) [0|3] ""  PT
 SG_ hvilShutdownStrategy_BMS01 m42 : 63|8@0+ (1,0) [0|255] ""  PT
 SG_ J1939_nmState m12 : 55|4@0+ (1,0) [0|0] ""  PT
 SG_ PrechargeXCapMin_BMS01 m42 : 47|16@0+ (0.01,0) [0|1] "mF"  PT
 SG_ LimpHomeTimeOut_BMS01 m42 : 15|32@0+ (1,0) [0|4294967295] "ms"  PT
 SG_ hvWithstandTests_BMS01 m40 : 15|8@0+ (1,0) [0|255] ""  PT
 SG_ aux3prechargeState_BMS01 m41 : 19|4@0+ (1,0) [0|0] ""  PT
 SG_ aux2prechargeState_BMS01 m41 : 31|4@0+ (1,0) [0|0] ""  PT
 SG_ aux1prechargeState_BMS01 m41 : 27|4@0+ (1,0) [0|0] ""  PT
 SG_ auxLinkVoltage_BMS01 m40 : 23|16@0+ (0.02,0) [0|1310.7] "V"  PT
 SG_ invalidModuleVoltageFlags_BMS01 m41 : 39|32@0+ (1,0) [0|0] ""  PT
 SG_ invalidModuleTempFlags_BMS01 m40 : 39|32@0+ (1,0) [0|0] ""  PT
 SG_ pumpSpeedExpected_BMS01 m30 : 15|8@0+ (0.4,0) [0|102] "%"  PT
 SG_ rangeRequestIgnoreVehicle m28 : 55|4@0+ (1,0) [0|65535] ""  PT
 SG_ rangeRequestEepromValue m28 : 63|4@0+ (1,0) [0|65535] ""  PT
 SG_ pressure2_BMS01 m35 : 31|8@0+ (0.4,0) [0|19] "psi"  PT
 SG_ calibration_version_BMS01 m37 : 63|8@0+ (1,0) [0|0] ""  PT
 SG_ currentLowTimer_BMS01 m39 : 55|16@0+ (1,0) [0|65535] "s"  PT
 SG_ auxCntrrOpenUnderLoadCntr_BMS01 m39 : 39|16@0+ (1,0) [0|0] ""  PT
 SG_ rabbitContactorState_BMS01 m34 : 31|8@0+ (1,0) [0|255] ""  PT
 SG_ analogIsenseSupplyCurr_BMS01 m37 : 55|8@0+ (0.04,0) [0|10] "A"  PT
 SG_ pumpSpeedReqCoolPrfmc_BMS01 m29 : 15|8@0+ (1,0) [0|0] "PCT"  PT
 SG_ microsarOs_IdleTask_OsCr0_BMS01 m39 : 23|8@0+ (1,0) [0|100] "PCT"  PT
 SG_ microsarOs_BswTask_BMS01 m39 : 15|8@0+ (1,0) [0|100] "PCT"  PT
 SG_ microsarOs_InitTask_BMS01 m39 : 31|8@0+ (1,0) [0|100] "PCT"  PT
 SG_ microsarOs_ApplTask_1Hz_BMS01 m38 : 63|8@0+ (1,0) [0|100] "PCT"  PT
 SG_ microsarOs_ApplTask_10Hz_BMS01 m38 : 55|8@0+ (1,0) [0|100] "PCT"  PT
 SG_ microsarOs_ApplTask_100Hz_BMS01 m38 : 47|8@0+ (1,0) [0|100] "PCT"  PT
 SG_ microsarOs_ApplLowTask_BMS01 m38 : 39|8@0+ (1,0) [0|100] "PCT"  PT
 SG_ microsarOs_ApplLateInit_BMS01 m38 : 31|8@0+ (1,0) [0|100] "PCT"  PT
 SG_ microsarOs_ApplHighTask_BMS01 m38 : 23|8@0+ (1,0) [0|100] "PCT"  PT
 SG_ microsarOs_ApplEarlyInit_BMS01 m38 : 15|8@0+ (1,0) [0|100] "PCT"  PT
 SG_ pumpRecoveryAttempts_BMS01 m31 : 15|8@0+ (1,0) [0|0] ""  PT
 SG_ appTaskBSWMaxDuration_BMS01 m37 : 47|8@0+ (0.5,0) [0|100] "PCT"  PT
 SG_ appTaskApplHighMaxDuration_BMS01 m37 : 15|16@0+ (0.5,0) [0|100] "PCT"  PT
 SG_ appTask1HzMaxDuration_BMS01 m36 : 63|8@0+ (0.5,0) [0|100] "PCT"  PT
 SG_ appTask100HzMaxDuration_BMS01 m36 : 47|8@0+ (0.5,0) [0|100] "PCT"  PT
 SG_ appTask10HzMaxDuration_BMS01 m36 : 55|8@0+ (0.5,0) [0|100] "PCT"  PT
 SG_ appTask100HzDuration_BMS01 m36 : 15|8@0+ (0.5,0) [0|100] "PCT"  PT
 SG_ appTask10HzDuration_BMS01 m36 : 23|8@0+ (0.5,0) [0|100] "PCT"  PT
 SG_ appTask1HzDuration_BMS01 m36 : 31|8@0+ (0.5,0) [0|100] "PCT"  PT
 SG_ appTaskBSWDuration_BMS01 m36 : 39|8@0+ (0.5,0) [0|100] "PCT"  PT
 SG_ appTaskApplHighDuration_BMS01 m37 : 31|16@0+ (0.5,0) [0|100] "PCT"  PT
 SG_ iumprMaxRatioDTCId_BMS01 m35 : 15|8@0+ (1,0) [0|0] ""  PT
 SG_ iumprMaxRatio_BMS01 m35 : 23|8@0+ (1,0) [0|0] ""  PT
 SG_ iumprMinRatioDTCId_BMS01 m33 : 63|8@0+ (1,0) [0|0] ""  PT
 SG_ iumprMinRatio_BMS01 m33 : 55|8@0+ (1,0) [0|0] ""  PT
 SG_ eepromWriteCyclesMax_BMS01 m11 : 55|16@0+ (64,0) [0|0] ""  PT
 SG_ eepromWriteCyclesUds_BMS01 m10 : 55|8@0+ (1,0) [0|0] ""  PT
 SG_ eepromWriteCyclesStat_BMS01 m10 : 63|8@0+ (1,0) [0|0] ""  PT
 SG_ eepromWriteCyclesSoh_BMS01 m11 : 47|8@0+ (1,0) [0|0] ""  PT
 SG_ fluidLvlCount_BMS01 m34 : 15|8@0+ (1,0) [0|255] ""  PT
 SG_ fluidLvlSensr2_BMS01 m34 : 19|2@0+ (1,0) [0|0] ""  PT
 SG_ fluidLvlSensr1_BMS01 m34 : 17|2@0+ (1,0) [0|0] ""  PT
 SG_ pumpSpeedReqVhcleSpeed_BMS01 m2 : 15|8@0+ (1,0) [0|0] "PCT"  PT
 SG_ appTaskBSWCpuUsage_BMS01 m18 : 15|8@0+ (0.5,0) [0|100] "PCT"  PT
 SG_ appTask200HzCpuUsage_BMS01 m17 : 15|8@0+ (0.5,0) [0|100] "PCT"  PT
 SG_ SWVersionBL_BMS01 m34 : 39|32@0+ (1,0) [0|4294967295] ""  PT
 SG_ SWVersionApp_BMS01 m35 : 39|32@0+ (1,0) [0|4294967295] ""  PT
 SG_ hvSNACounter_BMS01 m31 : 23|16@0+ (1,0) [0|0] ""  PT
 SG_ pyroState_BMS01 m28 : 59|4@0+ (1,0) [0|0] ""  PT
 SG_ ecuSerialNrChar15_BMS01 m33 : 47|8@0+ (1,0) [0|0] ""  PT
 SG_ ecuSerialNrChar14_BMS01 m33 : 39|8@0+ (1,0) [0|0] ""  PT
 SG_ ecuSerialNrChar13_BMS01 m33 : 31|8@0+ (1,0) [0|0] ""  PT
 SG_ ecuSerialNrChar12_BMS01 m33 : 23|8@0+ (1,0) [0|0] ""  PT
 SG_ ecuSerialNrChar11_BMS01 m32 : 63|8@0+ (1,0) [0|0] ""  PT
 SG_ ecuSerialNrChar10_BMS01 m32 : 55|8@0+ (1,0) [0|0] ""  PT
 SG_ ecuSerialNrChar09_BMS01 m32 : 47|8@0+ (1,0) [0|0] ""  PT
 SG_ ecuSerialNrChar08_BMS01 m32 : 39|8@0+ (1,0) [0|0] ""  PT
 SG_ ecuSerialNrChar07_BMS01 m32 : 31|8@0+ (1,0) [0|0] ""  PT
 SG_ ecuSerialNrChar06_BMS01 m32 : 23|8@0+ (1,0) [0|0] ""  PT
 SG_ ecuSerialNrChar05_BMS01 m32 : 15|8@0+ (1,0) [0|0] ""  PT
 SG_ analogGPIO1Current_BMS01 m22 : 39|8@0+ (0.015,0) [0|3.825] "A"  PT
 SG_ analogGPIO1Volt_BMS01 m22 : 55|8@0+ (0.1,0) [0|25] "V"  PT
 SG_ analogGPIO2Current_BMS01 m22 : 47|8@0+ (0.015,0) [0|3.825] "A"  PT
 SG_ analogGPIO2Volt_BMS01 m22 : 63|8@0+ (0.1,0) [0|25] "V"  PT
 SG_ pumpSpeedReqLoadValue_BMS01 m22 : 15|8@0+ (1,0) [0|0] "PCT"  PT
 SG_ ssaRTYear_BMS01 m31 : 55|16@0+ (1,0) [0|0] "yyyy"  PT
 SG_ ssaRTMonth_BMS01 m31 : 47|8@0+ (1,0) [0|0] "mm"  PT
 SG_ ssaRTDay_BMS01 m31 : 39|8@0+ (1,0) [0|0] "dd"  PT
 SG_ ssaTimeMRealTimeOffset_BMS01 m30 : 23|48@0+ (1,0) [0|0] ""  PT
 SG_ ssaTimeMTickCount_BMS01 m29 : 23|48@0+ (1,0) [0|0] ""  PT
 SG_ appTask50HzStackUsage_BMS01 m24 : 15|8@0+ (0.5,0) [0|100] "PCT"  PT
 SG_ OBDMILRequested_BMS01 m28 : 49|2@0+ (1,0) [0|3] ""  PT
 SG_ OBDConfirmedDTCsCount_BMS01 m28 : 15|8@0+ (1,0) [0|255] ""  PT
 SG_ OBDFirstConfirmedDTC_BMS01 m28 : 31|8@0+ (1,0) [0|255] ""  PT
 SG_ OBDFirstConfDTCWarmCyc_BMS01 m28 : 47|6@0+ (1,0) [0|63] ""  PT
 SG_ OBDPermanentDTCCount_BMS01 m28 : 23|8@0+ (1,0) [0|255] ""  PT
 SG_ OBDFirstPermanentDTC_BMS01 m28 : 39|8@0+ (1,0) [0|255] ""  PT
 SG_ OBDFirstPermDTCDriveCyc_BMS01 m28 : 41|2@0+ (1,0) [0|3] ""  PT
 SG_ nmStartupReason_BMS01 m16 : 15|4@0+ (1,0) [0|0] ""  PT
 SG_ SOCdynamicRecal_BMS01 m10 : 19|1@0+ (1,0) [0|1] ""  PT
 SG_ SOCuserSOCInit_BMS01 m10 : 18|1@0+ (1,0) [0|1] ""  PT
 SG_ contactorType_BMS01 m25 : 11|4@0+ (1,0) [0|0] ""  PT
 SG_ activeIsoTestDuration_BMS01 m13 : 15|8@0+ (200,0) [0|51000] "ms"  PT
 SG_ balancingState_BMS01 m16 : 11|4@0+ (1,0) [0|0] ""  PT
 SG_ storCondSysNwOk_BMS01 m27 : 25|1@0+ (1,0) [0|0] ""  PT
 SG_ storCondSysPwrOk_BMS01 m27 : 26|1@0+ (1,0) [0|0] ""  PT
 SG_ storCondECUOk_BMS01 m27 : 24|1@0+ (1,0) [0|0] ""  PT
 SG_ chronoStackWrCnt_BMS01 m27 : 39|32@0+ (1,0) [0|0] ""  PT
 SG_ wakeReason_BMS01 m10 : 15|4@0+ (1,0) [0|0] ""  PT
 SG_ cntrUnderLoadOpenCntr7_BMS01 m26 : 63|8@0+ (1,0) [0|0] ""  PT
 SG_ cntrUnderLoadOpenCntr6_BMS01 m26 : 55|8@0+ (1,0) [0|0] ""  PT
 SG_ cntrUnderLoadOpenCntr5_BMS01 m26 : 47|8@0+ (1,0) [0|0] ""  PT
 SG_ cntrUnderLoadOpenCntr4_BMS01 m26 : 39|8@0+ (1,0) [0|0] ""  PT
 SG_ cntrUnderLoadOpenCntr3_BMS01 m26 : 31|8@0+ (1,0) [0|0] ""  PT
 SG_ cntrUnderLoadOpenCntr2_BMS01 m26 : 23|8@0+ (1,0) [0|0] ""  PT
 SG_ cntrUnderLoadOpenCntr1_BMS01 m26 : 15|8@0+ (1,0) [0|0] ""  PT
 SG_ coolantOutletTemperature_BMS01 m27 : 23|8@0+ (1,-40) [-40|215] "C"  PT
 SG_ coolantInletTemperature_BMS01 m27 : 15|8@0+ (1,-40) [-40|215] "C"  PT
 SG_ prchgResHeatModel_BMS01 m3 : 55|16@0+ (0.1,0) [0|0] "Ws"  PT
 SG_ variantCodingCount_BMS01 m7 : 15|8@0+ (1,0) [0|0] ""  PT
 SG_ SWVersionCusApp_BMS01 m7 : 39|32@0+ (1,0) [0|0] ""  PT
 SG_ contactorOpenRequest_BMS01 m25 : 15|4@0+ (1,0) [0|0] ""  PT
 SG_ maxBrickVoltageChargeLimit_BMS01 m25 : 23|16@0+ (0.0001,0) [0|6.5] "V"  PT
 SG_ desiccantTimer_BMS01 m25 : 39|32@0+ (1,0) [0|0] "s"  PT
 SG_ batSwitchOpenReason_BMS01 m4 : 55|16@0+ (1,0) [0|0] ""  PT
 SG_ balancingTime_BMS01 m24 : 55|16@0+ (1,0) [0|65535] ""  PT
 SG_ bmsIsESSMaster_BMS01 m6 : 14|1@0+ (1,0) [0|0] ""  PT
 SG_ ecuSerialNrChar01_BMS01 m12 : 23|8@0+ (1,0) [0|0] ""  PT
 SG_ ecuSerialNrChar02_BMS01 m12 : 31|8@0+ (1,0) [0|0] ""  PT
 SG_ ecuSerialNrChar03_BMS01 m12 : 39|8@0+ (1,0) [0|0] ""  PT
 SG_ ecuSerialNrChar04_BMS01 m12 : 47|8@0+ (1,0) [0|0] ""  PT
 SG_ ecuSerialNrChar16_BMS01 m13 : 23|8@0+ (1,0) [0|0] ""  PT
 SG_ ecuSerialNrChar17_BMS01 m13 : 31|8@0+ (1,0) [0|0] ""  PT
 SG_ ecuSerialNrChar18_BMS01 m13 : 39|8@0+ (1,0) [0|0] ""  PT
 SG_ ecuSerialNrChar19_BMS01 m13 : 47|8@0+ (1,0) [0|0] ""  PT
 SG_ maxModuleTemperature_BMS01 m5 : 63|8@0+ (1,-40) [-40|200] "C"  PT
 SG_ meanModuleTemperature_BMS01 m8 : 15|8@0+ (1,-40) [-40|200] "C"  PT
 SG_ minModuleTemperature_BMS01 m5 : 55|8@0+ (1,-40) [-40|200] "C"  PT
 SG_ currentEventsShrt_BMS01 m6 : 15|1@0+ (1,0) [0|0] ""  PT
 SG_ nmOperationalMode_BMS01 m1 : 13|2@0+ (1,0) [0|0] ""  PT
 SG_ nmNetworkMode_BMS01 m1 : 15|2@0+ (1,0) [0|0] ""  PT
 SG_ nmNetworkState_BMS01 m1 : 11|1@0+ (1,0) [0|0] ""  PT
 SG_ ecuState_BMS01 m1 : 10|3@0+ (1,0) [0|7] ""  PT
 SG_ SPIRxTxDiag_BMS01 m10 : 11|4@0+ (2,0) [0|30] ""  PT
 SG_ minSOC_BMS01 m24 : 23|16@0+ (0.01,0) [0|100] "PCT"  PT
 SG_ maxSOC_BMS01 m24 : 39|16@0+ (0.01,0) [0|100] "PCT"  PT
 SG_ appTaskMaxCpuUsage_BMS01 m23 : 63|8@0+ (0.5,0) [0|100] "PCT"  PT
 SG_ appTaskCpuUsage_BMS01 m23 : 55|8@0+ (0.5,0) [0|100] "PCT"  PT
 SG_ appTask50HzCpuUsage_BMS01 m23 : 47|8@0+ (0.5,0) [0|100] "PCT"  PT
 SG_ appTask10HzStackUsage_BMS01 m23 : 39|8@0+ (0.5,0) [0|100] "PCT"  PT
 SG_ appTask100HzCpuUsage_BMS01 m23 : 31|8@0+ (0.5,0) [0|100] "PCT"  PT
 SG_ appTask10HzCpuUsage_BMS01 m23 : 23|8@0+ (0.5,0) [0|100] "PCT"  PT
 SG_ appTask1HzCpuUsage_BMS01 m23 : 15|8@0+ (0.5,0) [0|100] "PCT"  PT
 SG_ pumpSpeedReq_BMS01 m12 : 15|8@0+ (1,0) [0|0] "PCT"  PT
 SG_ numberOfStrings_BMS01 m4 : 15|5@0+ (1,0) [0|0] ""  PT
 SG_ hvComponentOpLimit_BMS01 m22 : 23|16@0+ (0.05,0) [0|3276.75] "A"  PT
 SG_ regenCurrPredBrickVOffset_BMS01 m5 : 15|8@0+ (0.5,0) [0|127.5] "A"  PT
 SG_ dischgCurrPredBrickVOffset_BMS01 m3 : 15|8@0+ (0.5,0) [0|127.5] "A"  PT
 SG_ PCANBusOffState_BMS01 m6 : 11|2@0+ (1,0) [0|0] ""  PT
 SG_ SCANBusOffState_BMS01 m6 : 13|2@0+ (1,0) [0|0] ""  PT
 SG_ PTCANBusOffState_BMS01 m6 : 9|2@0+ (1,0) [0|0] ""  PT
 SG_ eepromWriteCyclesSoc_BMS01 m11 : 39|8@0+ (1,0) [0|0] ""  PT
 SG_ eepromWriteCyclesDiag_BMS01 m11 : 31|8@0+ (1,0) [0|0] ""  PT
 SG_ eepromWriteCyclesChrono_BMS01 m10 : 39|8@0+ (1,0) [0|0] ""  PT
 SG_ eepromWriteCyclesCust_BMS01 m10 : 47|8@0+ (1,0) [0|0] ""  PT
 SG_ customerModelVsYear_BMS01 m14 : 23|8@0+ (1,0) [0|0] ""  PT
 SG_ customerModelVsWeek_BMS01 m14 : 31|8@0+ (1,0) [0|0] ""  PT
 SG_ customerModelVsCellType_BMS01 m14 : 15|1@0+ (1,0) [0|0] ""  PT
 SG_ customerModelVsCellGen_BMS01 m14 : 14|7@0+ (1,0) [0|0] ""  PT
 SG_ SWVersion_BMS01 m14 : 39|32@0+ (1,0) [0|4294967295] ""  PT
 SG_ balancingRequest288_to_295_BMS01 m21 : 63|8@0+ (1,0) [0|0] ""  PT
 SG_ balancingRequest296_to_303_BMS01 m21 : 55|8@0+ (1,0) [0|0] ""  PT
 SG_ balancingRequest304_to_311_BMS01 m21 : 47|8@0+ (1,0) [0|0] ""  PT
 SG_ balancingRequest312_to_319_BMS01 m21 : 39|8@0+ (1,0) [0|0] ""  PT
 SG_ balancingRequest320_to_327_BMS01 m21 : 31|8@0+ (1,0) [0|0] ""  PT
 SG_ balancingRequest328_to_335_BMS01 m21 : 23|8@0+ (1,0) [0|0] ""  PT
 SG_ balancingRequest240_to_247_BMS01 m20 : 63|8@0+ (1,0) [0|0] ""  PT
 SG_ balancingRequest248_to_255_BMS01 m20 : 55|8@0+ (1,0) [0|0] ""  PT
 SG_ balancingRequest256_to_263_BMS01 m20 : 47|8@0+ (1,0) [0|0] ""  PT
 SG_ balancingRequest264_to_271_BMS01 m20 : 39|8@0+ (1,0) [0|0] ""  PT
 SG_ balancingRequest272_to_279_BMS01 m20 : 31|8@0+ (1,0) [0|0] ""  PT
 SG_ balancingRequest280_to_287_BMS01 m20 : 23|8@0+ (1,0) [0|0] ""  PT
 SG_ balancingRequest192_to_199_BMS01 m19 : 63|8@0+ (1,0) [0|0] ""  PT
 SG_ balancingRequest200_to_207_BMS01 m19 : 55|8@0+ (1,0) [0|0] ""  PT
 SG_ balancingRequest208_to_215_BMS01 m19 : 47|8@0+ (1,0) [0|0] ""  PT
 SG_ balancingRequest216_to_223_BMS01 m19 : 39|8@0+ (1,0) [0|0] ""  PT
 SG_ balancingRequest224_to_231_BMS01 m19 : 31|8@0+ (1,0) [0|0] ""  PT
 SG_ balancingRequest232_to_239_BMS01 m19 : 23|8@0+ (1,0) [0|0] ""  PT
 SG_ balancingRequest144_to_151_BMS01 m18 : 63|8@0+ (1,0) [0|0] ""  PT
 SG_ balancingRequest152_to_159_BMS01 m18 : 55|8@0+ (1,0) [0|0] ""  PT
 SG_ balancingRequest160_to_167_BMS01 m18 : 47|8@0+ (1,0) [0|0] ""  PT
 SG_ balancingRequest168_to_175_BMS01 m18 : 39|8@0+ (1,0) [0|0] ""  PT
 SG_ balancingRequest176_to_183_BMS01 m18 : 31|8@0+ (1,0) [0|0] ""  PT
 SG_ balancingRequest184_to_191_BMS01 m18 : 23|8@0+ (1,0) [0|0] ""  PT
 SG_ balancingRequest096_to_103_BMS01 m17 : 63|8@0+ (1,0) [0|0] ""  PT
 SG_ balancingRequest104_to_111_BMS01 m17 : 55|8@0+ (1,0) [0|0] ""  PT
 SG_ balancingRequest112_to_119_BMS01 m17 : 47|8@0+ (1,0) [0|0] ""  PT
 SG_ balancingRequest120_to_127_BMS01 m17 : 39|8@0+ (1,0) [0|0] ""  PT
 SG_ balancingRequest128_to_135_BMS01 m17 : 31|8@0+ (1,0) [0|0] ""  PT
 SG_ balancingRequest136_to_143_BMS01 m17 : 23|8@0+ (1,0) [0|0] ""  PT
 SG_ balancingRequest048_to_055_BMS01 m16 : 63|8@0+ (1,0) [0|0] ""  PT
 SG_ balancingRequest056_to_063_BMS01 m16 : 55|8@0+ (1,0) [0|0] ""  PT
 SG_ balancingRequest064_to_071_BMS01 m16 : 47|8@0+ (1,0) [0|0] ""  PT
 SG_ balancingRequest072_to_079_BMS01 m16 : 39|8@0+ (1,0) [0|0] ""  PT
 SG_ balancingRequest080_to_087_BMS01 m16 : 31|8@0+ (1,0) [0|0] ""  PT
 SG_ balancingRequest088_to_095_BMS01 m16 : 23|8@0+ (1,0) [0|0] ""  PT
 SG_ balancingRequest000_to_007_BMS01 m15 : 63|8@0+ (1,0) [0|0] ""  PT
 SG_ balancingRequest008_to_015_BMS01 m15 : 55|8@0+ (1,0) [0|0] ""  PT
 SG_ balancingRequest016_to_023_BMS01 m15 : 47|8@0+ (1,0) [0|0] ""  PT
 SG_ balancingRequest024_to_031_BMS01 m15 : 39|8@0+ (1,0) [0|0] ""  PT
 SG_ balancingRequest032_to_039_BMS01 m15 : 31|8@0+ (1,0) [0|0] ""  PT
 SG_ balancingRequest040_to_047_BMS01 m15 : 23|8@0+ (1,0) [0|0] ""  PT
 SG_ balancingVoltageTarget_BMS01 m15 : 15|8@0+ (0.02,0) [0|5.1] ""  PT
 SG_ numberOfPacksPerString_BMS01 m4 : 10|3@0+ (1,0) [0|0] ""  PT
 SG_ analogAddr5_BMS01 m1 : 23|8@0+ (0.05,0) [0|12] "V"  PT
 SG_ analogAddr0_BMS01 m1 : 63|8@0+ (0.05,0) [0|12] "V"  PT
 SG_ analogAddr4_BMS01 m1 : 31|8@0+ (0.05,0) [0|12] "V"  PT
 SG_ analogAddr3_BMS01 m1 : 39|8@0+ (0.05,0) [0|12] "V"  PT
 SG_ analogAddr2_BMS01 m1 : 47|8@0+ (0.05,0) [0|12] "V"  PT
 SG_ analogAddr1_BMS01 m1 : 55|8@0+ (0.05,0) [0|12] "V"  PT
 SG_ debugSlowMpex1_BMS01 M : 7|8@0+ (1,0) [0|0] ""  PT
 SG_ analog3V3DSupply_BMS01 m9 : 15|8@0+ (0.015,0) [0|0] "V"  PT
 SG_ pressure_BMS01 m9 : 63|8@0+ (0.4,0) [0|19] "psi"  PT
 SG_ analog3P3VA_BMS01 m9 : 55|8@0+ (0.015,0) [0|3.825] "V"  PT
 SG_ analog5VA_BMS01 m9 : 31|8@0+ (0.025,0) [0|6] "V"  PT
 SG_ analog5VD_BMS01 m9 : 23|8@0+ (0.025,0) [0|6] "V"  PT
 SG_ analog5VSensorSupply_BMS01 m9 : 47|8@0+ (0.025,0) [0|6.375] "V"  PT
 SG_ analog6V5_BMS01 m9 : 39|8@0+ (0.0075,5) [5|6.9125] "V"  PT
 SG_ isolationResistanceIntern_BMS01 m8 : 55|16@0+ (2,0) [0|130000] "kOhm"  PT
 SG_ isolationResistanceExtern_BMS01 m8 : 39|16@0+ (2,0) [0|130000] "kOhm"  PT
 SG_ linkVoltage_BMS01 m8 : 23|16@0+ (0.02,0) [0|1310.7] "V"  PT
 SG_ eepromWriteCyclesBasics_BMS01 m11 : 23|8@0+ (1,0) [0|0] ""  PT
 SG_ eepromBlockIndex_BMS01 m11 : 15|8@0+ (1,0) [0|0] ""  PT
 SG_ CAN1MIATimerISR_BMS01 m7 : 23|8@0+ (1,0) [0|255] ""  PT
 SG_ CAN2MIATimerISR_BMS01 m7 : 31|8@0+ (1,0) [0|255] ""  PT
 SG_ regenCurrentOpLimit_BMS01 m5 : 39|16@0+ (0.05,0) [0|3200] "A"  PT
 SG_ regenCurrentErrorLimit_BMS01 m5 : 23|16@0+ (0.05,0) [0|3200] "A"  PT
 SG_ lifetime_BMS01 m6 : 39|32@0+ (1,0) [0|0] "s"  PT
 SG_ eepromReadTime_BMS01 m0 : 15|8@0+ (10,0) [0|2550] "ms"  PT
 SG_ chargerCurrentOpLimit_BMS01 m4 : 39|16@0+ (0.05,0) [0|3200] "A"  PT
 SG_ dischargeCurrentOpLimit_BMS01 m3 : 39|16@0+ (0.05,-3200) [-3200|0] "A"  PT
 SG_ chargerCurrentErrorLimit_BMS01 m4 : 23|16@0+ (0.05,0) [0|3200] "A"  PT
 SG_ dischargeCurrentErrorLimit_BMS01 m3 : 23|16@0+ (0.05,-3200) [-3200|0] "A"  PT
 SG_ pumpSpeedReqMaxT_BMS01 m2 : 23|8@0+ (1,0) [0|0] "PCT"  PT
 SG_ pumpSpeedReqDeltaT_BMS01 m2 : 31|8@0+ (1,0) [0|0] "PCT"  PT
 SG_ energyThroughput_BMS01 m2 : 39|32@0+ (0.001,0) [0|4294967.295] "kWh"  PT
 SG_ packVoltageCMB_BMS01 m6 : 23|16@0+ (0.02,0) [0|1200] "V"  PT
 SG_ ctrOffTimeLast_BMS01 m0 : 23|16@0+ (1,0) [0|0] "s"  PT
 SG_ ctrOffTime_BMS01 m0 : 39|16@0+ (1,0) [0|0] "s"  PT
 SG_ sleepTime_BMS01 m0 : 55|16@0+ (1,0) [0|0] "s"  PT
 SG_ SPIRxTxTimeAllPckts_BMS01 m10 : 31|8@0+ (2,0) [0|500] "ms"  PT
 SG_ isolationTestState_BMS01 m10 : 17|2@0+ (1,0) [0|0] ""  PT
 SG_ SOCvoltageInit_BMS01 m10 : 21|1@0+ (1,0) [0|1] ""  PT
 SG_ SOCocvInit_BMS01 m10 : 23|1@0+ (1,0) [0|1] ""  PT
 SG_ SOCeepromInit_BMS01 m10 : 22|1@0+ (1,0) [0|1] ""  PT
 SG_ SOCdefaultInit_BMS01 m10 : 20|1@0+ (1,0) [0|1] ""  PT

BO_ 1728 BMS01_DebugFastMpex1: 8 BMS01
 SG_ SPIRxTxHeaderMux3Status_BMS01 m1 : 23|1@0+ (1,0) [0|1] ""  PT
 SG_ SPIRxTxHeaderMux2Status_BMS01 m1 : 22|1@0+ (1,0) [0|1] ""  PT
 SG_ SPIRxTxHeaderMux1Status_BMS01 m1 : 21|1@0+ (1,0) [0|1] ""  PT
 SG_ SPIRxTxHeaderMux0Status_BMS01 m1 : 20|1@0+ (1,0) [0|1] ""  PT
 SG_ activeIsoTestPsbl_BMS01 m0 : 27|1@0+ (1,0) [0|0] ""  PT
 SG_ activeIsoState_BMS01 m3 : 15|8@0+ (1,0) [0|0] ""  PT
 SG_ activeIsoNegLink_BMS01 m3 : 39|16@0+ (0.04,-1250) [-1250|1371.4] "V"  PT
 SG_ activeIsoPosLink_BMS01 m3 : 23|16@0+ (0.04,-1250) [-1250|1371.4] "V"  PT
 SG_ activeIsoTestStateTimer_BMS01 m2 : 15|8@0+ (200,0) [0|51000] "ms"  PT
 SG_ activeIsoPosBuffer_BMS01 m2 : 23|16@0+ (0.04,-1250) [-1250|1371.4] "V"  PT
 SG_ activeIsoNegBuffer_BMS01 m2 : 39|16@0+ (0.04,-1250) [-1250|1371.4] "V"  PT
 SG_ activeIsoResRaw_BMS01 m2 : 55|16@0+ (2,0) [0|130000] "kOhm"  PT
 SG_ activeIsoResFilter_BMS01 m3 : 55|16@0+ (2,0) [0|130000] "kOhm"  PT
 SG_ contactorStateAux_BMS01 m1 : 34|3@0+ (1,0) [0|0] ""  PT
 SG_ batSwitchOpenReqEssMstr_BMS01 m0 : 35|2@0+ (1,0) [0|0] ""  PT
 SG_ packShutdownTarget_BMS01 m1 : 12|2@0+ (1,0) [0|0] ""  PT
 SG_ weldedState_BMS01 m1 : 39|2@0+ (1,0) [0|0] ""  PT
 SG_ DIGIO_GPIO2_ON_BMS01 m1 : 19|1@0+ (1,0) [0|0] ""  PT
 SG_ DIGIO_GPIO1_ON_BMS01 m1 : 18|1@0+ (1,0) [0|0] ""  PT
 SG_ DIGIO_12VCURR_SENSE_ON_BMS01 m1 : 37|1@0+ (1,0) [0|0] ""  PT
 SG_ DIGIO_PSUP_SAFETY_OK_BMS01 m1 : 17|1@0+ (1,0) [0|0] ""  PT
 SG_ contactorStateRq_BMS01 m1 : 36|2@0+ (1,0) [0|0] ""  PT
 SG_ contactorPwrOkToPrechg_BMS01 m1 : 16|1@0+ (1,0) [0|0] ""  PT
 SG_ strMstrStrPrechgState_BMS01 m1 : 58|3@0+ (1,0) [0|0] ""  PT
 SG_ packShutdwnTmrQual_BMS01 m1 : 27|1@0+ (1,0) [0|0] ""  PT
 SG_ packStateRequest_BMS01 m1 : 15|3@0+ (1,0) [0|0] ""  PT
 SG_ packState_BMS01 m1 : 31|4@0+ (1,0) [0|0] ""  PT
 SG_ SPIRxTxTimer_BMS01 m1 : 47|8@0+ (2,0) [0|500] "ms"  PT
 SG_ moduleTMinMaxMeanQual_BMS01 m1 : 26|1@0+ (1,0) [0|0] ""  PT
 SG_ currentQual_BMS01 m1 : 25|1@0+ (1,0) [0|0] ""  PT
 SG_ brickVMinMaxMeanQual_BMS01 m1 : 24|1@0+ (1,0) [0|0] ""  PT
 SG_ negCtr1OnReqASW_BMS01 m1 : 8|1@0+ (1,0) [0|0] ""  PT
 SG_ prechgCtr1OnReqASW_BMS01 m1 : 9|1@0+ (1,0) [0|0] ""  PT
 SG_ posCtr1OnReqASW_BMS01 m1 : 10|1@0+ (1,0) [0|0] ""  PT
 SG_ DIGIO_CNTR_HISIDE_ON_MC_BMS01 m0 : 38|1@0+ (1,0) [0|0] ""  PT
 SG_ DIGIO_CNTR_HISIDE_ON_CHCKD_BMS01 m0 : 37|1@0+ (1,0) [0|0] ""  PT
 SG_ DIGIO_CNTR_CLOSE_OK_CHCKD_BMS01 m0 : 36|1@0+ (1,0) [0|0] ""  PT
 SG_ debugFastMpex1_BMS01 M : 7|8@0+ (1,0) [0|0] ""  PT
 SG_ stateContactorControl_BMS01 m0 : 41|1@0+ (1,0) [0|0] ""  PT
 SG_ stateVoltage_BMS01 m0 : 43|1@0+ (1,0) [0|0] ""  PT
 SG_ stateTemperature_BMS01 m0 : 44|1@0+ (1,0) [0|0] ""  PT
 SG_ stateSelfTest_BMS01 m0 : 45|1@0+ (1,0) [0|0] ""  PT
 SG_ stateHVIL_BMS01 m0 : 46|1@0+ (1,0) [0|0] ""  PT
 SG_ stateCurrent_BMS01 m0 : 47|1@0+ (1,0) [0|0] ""  PT
 SG_ stateCrash_BMS01 m0 : 42|1@0+ (1,0) [0|0] ""  PT
 SG_ stateContactors_BMS01 m0 : 40|1@0+ (1,0) [0|0] ""  PT
 SG_ stateCANRx_BMS01 m0 : 39|1@0+ (1,0) [0|0] ""  PT
 SG_ itemState_BMS01 m0 : 33|2@0+ (1,0) [0|0] ""  PT
 SG_ negLink_BMS01 m0 : 23|8@0+ (10,-1200) [-1200|1350] "V"  PT
 SG_ posLink_BMS01 m0 : 15|8@0+ (10,-1200) [-1200|1350] "V"  PT
 SG_ negPack_BMS01 m0 : 63|8@0+ (10,-1200) [-1200|1350] "V"  PT
 SG_ posPack_BMS01 m0 : 55|8@0+ (10,-1200) [-1200|1350] "V"  PT
 SG_ prechargeState_BMS01 m0 : 31|4@0+ (1,0) [0|0] ""  PT
 SG_ contactorState_BMS01 m0 : 26|3@0+ (1,0) [0|0] ""  PT
 SG_ diagStandbyImmShutdown_BMS01 m1 : 61|1@0+ (1,0) [0|1] ""  PT
 SG_ diagAllOffRequired_BMS01 m1 : 60|1@0+ (1,0) [0|1] ""  PT
 SG_ diagDriveTransitionNotOK_BMS01 m1 : 55|1@0+ (1,0) [0|1] ""  PT
 SG_ diagDriveImmShutdown_BMS01 m1 : 54|1@0+ (1,0) [0|1] ""  PT
 SG_ diagDriveDelShutdown2_BMS01 m1 : 52|1@0+ (1,0) [0|1] ""  PT
 SG_ diagDriveDelShutdown1_BMS01 m1 : 53|1@0+ (1,0) [0|1] ""  PT
 SG_ diagUnused_BMS01 m1 : 59|1@0+ (1,0) [0|1] ""  PT
 SG_ diagChargeTransitionNotOK_BMS01 m1 : 51|1@0+ (1,0) [0|1] ""  PT
 SG_ diagChargeImmShutdown_BMS01 m1 : 50|1@0+ (1,0) [0|1] ""  PT
 SG_ diagAccDelShutdown1_BMS01 m1 : 62|1@0+ (1,0) [0|1] ""  PT
 SG_ diagChargeDelShutdown1_BMS01 m1 : 49|1@0+ (1,0) [0|1] ""  PT
 SG_ diagAccTransitionNotOK_BMS01 m1 : 48|1@0+ (1,0) [0|1] ""  PT
 SG_ diagAccImmShutdown_BMS01 m1 : 63|1@0+ (1,0) [0|1] ""  PT

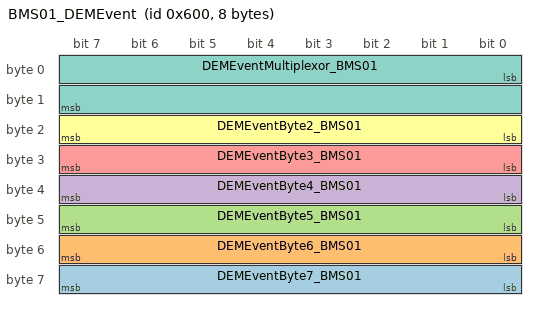
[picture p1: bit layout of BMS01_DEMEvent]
BO_ 1536 BMS01_DEMEvent: 8 BMS01
 SG_ DEMEventByte7_BMS01 : 63|8@0+ (1,0) [0|0] ""  PT
 SG_ DEMEventByte6_BMS01 : 55|8@0+ (1,0) [0|0] ""  PT
 SG_ DEMEventByte5_BMS01 : 47|8@0+ (1,0) [0|0] ""  PT
 SG_ DEMEventByte4_BMS01 : 39|8@0+ (1,0) [0|0] ""  PT
 SG_ DEMEventByte3_BMS01 : 31|8@0+ (1,0) [0|0] ""  PT
 SG_ DEMEventByte2_BMS01 : 23|8@0+ (1,0) [0|0] ""  PT
 SG_ DEMEventMultiplexor_BMS01 M : 0|16@1+ (1,0) [0|0] ""  PT

BO_ 1024 BMS01_DebugEventMap1: 8 BMS01
 SG_ DEM001_POWERUP_BMS01 : 11|2@0+ (1,0) [0|0] ""  PT
 SG_ DEM002_VOLTAGE_BRICK_OV_BMS01 : 13|2@0+ (1,0) [0|0] ""  PT
 SG_ DEM003_VOLTAGE_BRICK_UV_BMS01 : 15|2@0+ (1,0) [0|0] ""  PT
 SG_ DEM004_VOLTAGE_BRICK_SNA_BMS01 : 1|2@0+ (1,0) [0|0] ""  PT
 SG_ DEM005_VOLTAGE_BRICK_IMBAL_BMS01 : 3|2@0+ (1,0) [0|0] ""  PT
 SG_ DEM006_VOLTAGE_CAPCY_IMBAL_BMS01 : 5|2@0+ (1,0) [0|0] ""  PT
 SG_ DEM007_MODULET_HIGH_DELTA_BMS01 : 7|2@0+ (1,0) [0|0] ""  PT
 SG_ DEM008_VOLTAGE_PACK_UV_BMS01 : 25|2@0+ (1,0) [0|0] ""  PT
 SG_ DEM009_VOLTAGE_PACK_OV_BMS01 : 27|2@0+ (1,0) [0|0] ""  PT
 SG_ DEM010_VOLTAGE_PACK_PLAUSI_BMS01 : 29|2@0+ (1,0) [0|0] ""  PT
 SG_ DEM011_VOLTAGE_PCKLINK_MIS_BMS01 : 31|2@0+ (1,0) [0|0] ""  PT
 SG_ DEM012_VOLTAGE_BMS_SUPPLY_BMS01 : 17|2@0+ (1,0) [0|0] ""  PT
 SG_ DEM013_ADC_ERROR_BMS01 : 19|2@0+ (1,0) [0|0] ""  PT
 SG_ DEM014_MODULET_OT_BMS01 : 21|2@0+ (1,0) [0|0] ""  PT
 SG_ DEM015_MODULET_SNA_BMS01 : 23|2@0+ (1,0) [0|0] ""  PT
 SG_ DEM016_MODULET_LIMPHOME_BMS01 : 41|2@0+ (1,0) [0|0] ""  PT
 SG_ DEM017_COOLING_SYS_LHOME_BMS01 : 43|2@0+ (1,0) [0|0] ""  PT
 SG_ DEM018_HVIL_LIMPHOME_BMS01 : 45|2@0+ (1,0) [0|0] ""  PT
 SG_ DEM019_HVIL_ESS_INHIBIT_BMS01 : 47|2@0+ (1,0) [0|0] ""  PT
 SG_ DEM020_MODULET_CHANGE_BMS01 : 33|2@0+ (1,0) [0|0] ""  PT
 SG_ DEM021_LG_MAVD_FAULT_BMS01 : 35|2@0+ (1,0) [0|0] ""  PT
 SG_ DEM022_LG_RDV_FAULT_BMS01 : 37|2@0+ (1,0) [0|0] ""  PT
 SG_ DEM023_BMS_ONBOARDT_SNA_BMS01 : 39|2@0+ (1,0) [0|0] ""  PT
 SG_ DEM024_BMS_ONBOARDRH_OH_BMS01 : 57|2@0+ (1,0) [0|0] ""  PT
 SG_ DEM025_BMS_ONBOARDRH_SNA_BMS01 : 59|2@0+ (1,0) [0|0] ""  PT
 SG_ DEM026_CURRENT_OVERCHARGE_BMS01 : 61|2@0+ (1,0) [0|0] ""  PT
 SG_ DEM027_CURRENT_OVERDISCHGE_BMS01 : 63|2@0+ (1,0) [0|0] ""  PT
 SG_ DEM028_CURRENT_INVALID_BMS01 : 49|2@0+ (1,0) [0|0] ""  PT
 SG_ DEM029_CURRENT_SHORTCIRCT_BMS01 : 51|2@0+ (1,0) [0|0] ""  PT
 SG_ DEM030_CRASH_CAN_LATCH_BMS01 : 53|2@0+ (1,0) [0|0] ""  PT
 SG_ DEM031_EEPROM_FAIL_BMS01 : 55|2@0+ (1,0) [0|0] ""  PT

BO_ 1088 BMS01_DebugEventMap2: 8 BMS01
 SG_ DEM032_PCHG_PACKS_CONNECT_BMS01 : 9|2@0+ (1,0) [0|0] ""  PT
 SG_ DEM033_PCHG_ILLEGAL_PRCHG_BMS01 : 11|2@0+ (1,0) [0|0] ""  PT
 SG_ DEM034_PCHG_RELAY_FAIL_BMS01 : 13|2@0+ (1,0) [0|0] ""  PT
 SG_ DEM035_PCHG_NEG_WELD_BMS01 : 15|2@0+ (1,0) [0|0] ""  PT
 SG_ DEM036_PCHG_NEG_PULLIN_BMS01 : 1|2@0+ (1,0) [0|0] ""  PT
 SG_ DEM037_PCHG_SHORTCIRCUIT_BMS01 : 3|2@0+ (1,0) [0|0] ""  PT
 SG_ DEM038_PCHG_OPENCIRCUIT_BMS01 : 5|2@0+ (1,0) [0|0] ""  PT
 SG_ DEM039_PCHG_TIMEOUT_BMS01 : 7|2@0+ (1,0) [0|0] ""  PT
 SG_ DEM040_PCHG_FAILED_BMS01 : 25|2@0+ (1,0) [0|0] ""  PT
 SG_ DEM041_HVIL_SHUTDOWN_BMS01 : 27|2@0+ (1,0) [0|0] ""  PT
 SG_ DEM042_PCHG_POS_WELD_BMS01 : 29|2@0+ (1,0) [0|0] ""  PT
 SG_ DEM043_HV_LOCK_TRANSPORT_BMS01 : 31|2@0+ (1,0) [0|0] ""  PT
 SG_ DEM044_CTRS_END_OF_LIFE_BMS01 : 17|2@0+ (1,0) [0|0] ""  PT
 SG_ DEM045_CTRS_CTRPWRV_HI_BMS01 : 19|2@0+ (1,0) [0|0] ""  PT
 SG_ DEM046_CTRS_COILCURR_LOW_BMS01 : 21|2@0+ (1,0) [0|0] ""  PT
 SG_ DEM047_CTRS_COILCURR_HIGH_BMS01 : 23|2@0+ (1,0) [0|0] ""  PT
 SG_ DEM048_CTRS_CTRPWRV_LOW_BMS01 : 41|2@0+ (1,0) [0|0] ""  PT
 SG_ DEM049_CHGE_ILLEGAL_DISCHG_BMS01 : 43|2@0+ (1,0) [0|0] ""  PT
 SG_ DEM050_STARTUP_CONDITIONS_BMS01 : 45|2@0+ (1,0) [0|0] ""  PT
 SG_ DEM051_VOLTAGE_BMS_SUPPLYH_BMS01 : 47|2@0+ (1,0) [0|0] ""  PT
 SG_ DEM052_SAFETYSPI_FAIL_BMS01 : 33|2@0+ (1,0) [0|0] ""  PT
 SG_ DEM053_WATCHDOG_ERRORPIN_BMS01 : 35|2@0+ (1,0) [0|0] ""  PT
 SG_ DEM054_SAFESTATE_TRIGGERED_BMS01 : 37|2@0+ (1,0) [0|0] ""  PT
 SG_ DEM055_DEBUG_CMND_ACTIVE_BMS01 : 39|2@0+ (1,0) [0|0] ""  PT
 SG_ DEM056_CRASH_CAN_BMS01 : 57|2@0+ (1,0) [0|0] ""  PT
 SG_ DEM057_ISO_EXT_STRAT_4_BMS01 : 59|2@0+ (1,0) [0|0] ""  PT
 SG_ DEM058_ISO_EXT_RES_ERR_BMS01 : 61|2@0+ (1,0) [0|0] ""  PT
 SG_ DEM059_ISO_EXT_RES_WARN_BMS01 : 63|2@0+ (1,0) [0|0] ""  PT
 SG_ DEM060_ISO_INT_RES_ERR_BMS01 : 49|2@0+ (1,0) [0|0] ""  PT
 SG_ DEM061_ISO_INT_RES_WARN_BMS01 : 51|2@0+ (1,0) [0|0] ""  PT
 SG_ DEM062_EMERGENCY_OPERATION_BMS01 : 53|2@0+ (1,0) [0|0] ""  PT
 SG_ DEM063_ENDOFDRIVE_BMS01 : 55|2@0+ (1,0) [0|0] ""  PT

BO_ 1152 BMS01_DebugEventMap3: 8 BMS01
 SG_ DEM064_STRINGV_IMBALANCE_BMS01 : 9|2@0+ (1,0) [0|0] ""  PT
 SG_ DEM065_STRING_FAULT_BMS01 : 11|2@0+ (1,0) [0|0] ""  PT
 SG_ DEM066_ESS_FAULT_BMS01 : 13|2@0+ (1,0) [0|0] ""  PT
 SG_ DEM067_ISO_EXT_STRAT_3_BMS01 : 15|2@0+ (1,0) [0|0] ""  PT
 SG_ DEM068_MODULE_COUNT_INVALI_BMS01 : 1|2@0+ (1,0) [0|0] ""  PT
 SG_ DEM069_PT_MIA_BMS01 : 3|2@0+ (1,0) [0|0] ""  PT
 SG_ DEM070_BMSMIA_STRNGMSTR_01_BMS01 : 5|2@0+ (1,0) [0|0] ""  PT
 SG_ DEM071_BMSMIA_STRNGMSTR_05_BMS01 : 7|2@0+ (1,0) [0|0] ""  PT
 SG_ DEM072_BMSMIA_STRNGMSTR_09_BMS01 : 25|2@0+ (1,0) [0|0] ""  PT
 SG_ DEM073_BMSMIA_STRNGMSTR_13_BMS01 : 27|2@0+ (1,0) [0|0] ""  PT
 SG_ DEM074_BMSMIA_STRNGMSTR_17_BMS01 : 29|2@0+ (1,0) [0|0] ""  PT
 SG_ DEM075_BMSMIA_STRNGMSTR_21_BMS01 : 31|2@0+ (1,0) [0|0] ""  PT
 SG_ DEM076_BMSMIA_STRNGMSTR_25_BMS01 : 17|2@0+ (1,0) [0|0] ""  PT
 SG_ DEM077_BMSMIA_STRNGMSTR_29_BMS01 : 19|2@0+ (1,0) [0|0] ""  PT
 SG_ DEM078_BMSMIA_STRNGMSTR_33_BMS01 : 21|2@0+ (1,0) [0|0] ""  PT
 SG_ DEM079_BMSMIA_STRNGMSTR_37_BMS01 : 23|2@0+ (1,0) [0|0] ""  PT
 SG_ DEM080_BMSMIA_STRNGMSTR_41_BMS01 : 41|2@0+ (1,0) [0|0] ""  PT
 SG_ DEM081_BMSMIA_STRNGMSTR_45_BMS01 : 43|2@0+ (1,0) [0|0] ""  PT
 SG_ DEM082_BMSMIA_STRNGMSTR_49_BMS01 : 45|2@0+ (1,0) [0|0] ""  PT
 SG_ DEM083_BMSMIA_STRNGMSTR_53_BMS01 : 47|2@0+ (1,0) [0|0] ""  PT
 SG_ DEM084_BMSMIA_STRNGMSTR_57_BMS01 : 33|2@0+ (1,0) [0|0] ""  PT
 SG_ DEM085_BMSMIA_STRNGMSTR_61_BMS01 : 35|2@0+ (1,0) [0|0] ""  PT
 SG_ DEM086_ESSCURRENT_SHORT_BMS01 : 37|2@0+ (1,0) [0|0] ""  PT
 SG_ DEM087_PT_MIA_SHUTDOWN_BMS01 : 39|2@0+ (1,0) [0|0] ""  PT
 SG_ DEM088_OUTLET_NTC_HI_BMS01 : 57|2@0+ (1,0) [0|0] ""  PT
 SG_ DEM089_OUTLET_NTC_LO_BMS01 : 59|2@0+ (1,0) [0|0] ""  PT
 SG_ DEM090_BMSMIA_ESSMASTER_BMS01 : 61|2@0+ (1,0) [0|0] ""  PT
 SG_ DEM091_PCHG_RES_OVERHEAT_BMS01 : 63|2@0+ (1,0) [0|0] ""  PT
 SG_ DEM092_BMSMIA_STRNGSLAVE_0_BMS01 : 49|2@0+ (1,0) [0|0] ""  PT
 SG_ DEM093_BMSMIA_STRNGSLAVE_1_BMS01 : 51|2@0+ (1,0) [0|0] ""  PT
 SG_ DEM094_BMSMIA_STRNGSLAVE_2_BMS01 : 53|2@0+ (1,0) [0|0] ""  PT
 SG_ DEM095_BMSMIA_STRNGSLAVE_3_BMS01 : 55|2@0+ (1,0) [0|0] ""  PT

BO_ 1216 BMS01_DebugEventMap4: 8 BMS01
 SG_ DEM096_SC_STATE_SELFTEST_BMS01 : 9|2@0+ (1,0) [0|0] ""  PT
 SG_ DEM097_SC_STATE_TEMP_BMS01 : 11|2@0+ (1,0) [0|0] ""  PT
 SG_ DEM098_SC_STATE_VOLTAGE_BMS01 : 13|2@0+ (1,0) [0|0] ""  PT
 SG_ DEM099_SC_STATE_HVIL_BMS01 : 15|2@0+ (1,0) [0|0] ""  PT
 SG_ DEM100_SC_STATE_CONTACTORS_BMS01 : 1|2@0+ (1,0) [0|0] ""  PT
 SG_ DEM101_SC_STATE_CURRENT_BMS01 : 3|2@0+ (1,0) [0|0] ""  PT
 SG_ DEM102_SC_STATE_CANRX_BMS01 : 5|2@0+ (1,0) [0|0] ""  PT
 SG_ DEM103_SC_STATE_CRASH_BMS01 : 7|2@0+ (1,0) [0|0] ""  PT
 SG_ DEM104_SC_STATE_CCTRL_BMS01 : 25|2@0+ (1,0) [0|0] ""  PT
 SG_ DEM105_SC_STATE_CANTX_BMS01 : 27|2@0+ (1,0) [0|0] ""  PT
 SG_ DEM106_SC_STATE_THERMALEVT_BMS01 : 29|2@0+ (1,0) [0|0] ""  PT
 SG_ DEM107_SC_STATE_COOLANT_BMS01 : 31|2@0+ (1,0) [0|0] ""  PT
 SG_ DEM108_SC_SELFTEST_SFTY_UC_BMS01 : 17|2@0+ (1,0) [0|0] ""  PT
 SG_ DEM109_SC_TEMP_HIGH_BMS01 : 19|2@0+ (1,0) [0|0] ""  PT
 SG_ DEM110_SC_TEMP_NTC_OPEN_BMS01 : 21|2@0+ (1,0) [0|0] ""  PT
 SG_ DEM111_SC_TEMP_NTC_SHORT_BMS01 : 23|2@0+ (1,0) [0|0] ""  PT
 SG_ DEM112_CMB_DISCONNECTED_BMS01 : 41|2@0+ (1,0) [0|0] ""  PT
 SG_ DEM113_CMB_DEFECT_BMS01 : 43|2@0+ (1,0) [0|0] ""  PT
 SG_ DEM114_CMB_COMMERROR_BMS01 : 45|2@0+ (1,0) [0|0] ""  PT
 SG_ DEM115_SC_CURR_HALL_PWR_LO_BMS01 : 47|2@0+ (1,0) [0|0] ""  PT
 SG_ DEM116_SC_CURR_HALL_VHIGH_BMS01 : 33|2@0+ (1,0) [0|0] ""  PT
 SG_ DEM117_SC_CURR_HALL_ADC_BMS01 : 35|2@0+ (1,0) [0|0] ""  PT
 SG_ DEM118_SC_CURR_HALL_VLOW_BMS01 : 37|2@0+ (1,0) [0|0] ""  PT
 SG_ DEM119_SC_CURR_ISENSE_PWR_BMS01 : 39|2@0+ (1,0) [0|0] ""  PT
 SG_ DEM120_SC_CURR_ISENSE1_MIA_BMS01 : 57|2@0+ (1,0) [0|0] ""  PT
 SG_ DEM121_SC_CURR_ISENSE2_MIA_BMS01 : 59|2@0+ (1,0) [0|0] ""  PT
 SG_ DEM122_SC_CURR_ISENSE3_MIA_BMS01 : 61|2@0+ (1,0) [0|0] ""  PT
 SG_ DEM123_SC_CURR_ISENSE4_MIA_BMS01 : 63|2@0+ (1,0) [0|0] ""  PT
 SG_ DEM124_SC_CURR_ISENSE5_MIA_BMS01 : 49|2@0+ (1,0) [0|0] ""  PT
 SG_ DEM125_SC_CURR_ISENSE1_FLT_BMS01 : 51|2@0+ (1,0) [0|0] ""  PT
 SG_ DEM126_SC_CURR_ISENSE2_FLT_BMS01 : 53|2@0+ (1,0) [0|0] ""  PT
 SG_ DEM127_SC_CURR_ISENSE3_FLT_BMS01 : 55|2@0+ (1,0) [0|0] ""  PT

BO_ 1280 BMS01_DebugEventMap5: 8 BMS01
 SG_ DEM128_SC_CURR_ISENSE4_FLT_BMS01 : 9|2@0+ (1,0) [0|0] ""  PT
 SG_ DEM129_SC_CURR_ISENSE5_FLT_BMS01 : 11|2@0+ (1,0) [0|0] ""  PT
 SG_ DEM130_SC_CURR_OFFSET_BMS01 : 13|2@0+ (1,0) [0|0] ""  PT
 SG_ DEM131_SC_CURR_PLAUSI_BMS01 : 15|2@0+ (1,0) [0|0] ""  PT
 SG_ DEM132_SC_CURR_CHARGE_HIGH_BMS01 : 1|2@0+ (1,0) [0|0] ""  PT
 SG_ DEM133_SC_CURR_DSCHAR_HIGH_BMS01 : 3|2@0+ (1,0) [0|0] ""  PT
 SG_ DEM134_SC_V_CMB_SUMOFCELL_BMS01 : 5|2@0+ (1,0) [0|0] ""  PT
 SG_ DEM135_SC_V_SENSE_OPENWIRE_BMS01 : 7|2@0+ (1,0) [0|0] ""  PT
 SG_ DEM136_SC_V_CMB_DRV_FROZEN_BMS01 : 25|2@0+ (1,0) [0|0] ""  PT
 SG_ DEM137_SC_V_PACK_PLAUSI_BMS01 : 27|2@0+ (1,0) [0|0] ""  PT
 SG_ DEM138_SC_HVIL_HW_FLT_BMS01 : 29|2@0+ (1,0) [0|0] ""  PT
 SG_ DEM139_SC_HVIL_OPEN_BMS01 : 31|2@0+ (1,0) [0|0] ""  PT
 SG_ DEM140_SC_HVIL_TO_SUP_BMS01 : 17|2@0+ (1,0) [0|0] ""  PT
 SG_ DEM141_SC_HVIL_TO_CHAS_BMS01 : 19|2@0+ (1,0) [0|0] ""  PT
 SG_ DEM142_SC_HVIL_R_HIGH_BMS01 : 21|2@0+ (1,0) [0|0] ""  PT
 SG_ DEM143_SC_HVIL_SHORT_BMS01 : 23|2@0+ (1,0) [0|0] ""  PT
 SG_ DEM144_SC_CN_ISO_FAIL_BMS01 : 41|2@0+ (1,0) [0|0] ""  PT
 SG_ DEM145_HVIL_SYS_BMS01 : 43|2@0+ (1,0) [0|0] ""  PT
 SG_ DEM146_SC_CN_POS1_WELDED_BMS01 : 45|2@0+ (1,0) [0|0] ""  PT
 SG_ DEM147_SC_CN_NEG1_WELDED_BMS01 : 47|2@0+ (1,0) [0|0] ""  PT
 SG_ DEM148_SC_CN_POS2_WELDED_BMS01 : 33|2@0+ (1,0) [0|0] ""  PT
 SG_ DEM149_SC_CN_NEG2_WELDED_BMS01 : 35|2@0+ (1,0) [0|0] ""  PT
 SG_ DEM150_SC_CN_POS3_WELDED_BMS01 : 37|2@0+ (1,0) [0|0] ""  PT
 SG_ DEM151_SC_CN_NEG3_WELDED_BMS01 : 39|2@0+ (1,0) [0|0] ""  PT
 SG_ DEM152_SC_CN_HIGH_CY_BMS01 : 57|2@0+ (1,0) [0|0] ""  PT
 SG_ DEM153_SC_CN_ISOANDPOTWELD_BMS01 : 59|2@0+ (1,0) [0|0] ""  PT
 SG_ DEM154_SC_TEMP_PLAUSI_BMS01 : 61|2@0+ (1,0) [0|0] ""  PT
 SG_ DEM155_SC_CURR_HALL_PWR_HI_BMS01 : 63|2@0+ (1,0) [0|0] ""  PT
 SG_ DEM156_SC_PYRO_TRIGGERED_BMS01 : 49|2@0+ (1,0) [0|0] ""  PT
 SG_ DEM157_SC_PYRO_OPEN_BMS01 : 51|2@0+ (1,0) [0|0] ""  PT
 SG_ DEM158_AUX_CTRS_END_OF_LIF_BMS01 : 53|2@0+ (1,0) [0|0] ""  PT
 SG_ DEM159_SC_CANRX_PT_MIA_BMS01 : 55|2@0+ (1,0) [0|0] ""  PT

BO_ 1344 BMS01_DebugEventMap6: 8 BMS01
 SG_ DEM160_SC_CANRX_PT_CRCALIV_BMS01 : 9|2@0+ (1,0) [0|0] ""  PT
 SG_ DEM161_SC_CANRX_LIN_SHUTDN_BMS01 : 11|2@0+ (1,0) [0|0] ""  PT
 SG_ DEM162_SC_CANRX_LIN_MIA_BMS01 : 13|2@0+ (1,0) [0|0] ""  PT
 SG_ DEM163_SC_CRASH1_BMS01 : 15|2@0+ (1,0) [0|0] ""  PT
 SG_ DEM164_SC_CRASH2_BMS01 : 1|2@0+ (1,0) [0|0] ""  PT
 SG_ DEM165_SC_CRASHCAN_BMS01 : 3|2@0+ (1,0) [0|0] ""  PT
 SG_ DEM166_SC_CCTRL_SELFTEST_BMS01 : 5|2@0+ (1,0) [0|0] ""  PT
 SG_ DEM167_SC_CCTRL_DRIVER_FAU_BMS01 : 7|2@0+ (1,0) [0|0] ""  PT
 SG_ DEM168_SC_CCTRL_HISIDESTCL_BMS01 : 25|2@0+ (1,0) [0|0] ""  PT
 SG_ DEM169_SC_CCTRL_HISIDESTOP_BMS01 : 27|2@0+ (1,0) [0|0] ""  PT
 SG_ DEM170_SC_CCTRL_LOSIDESTCL_BMS01 : 29|2@0+ (1,0) [0|0] ""  PT
 SG_ DEM171_SC_CCTRL_HVCNDITION_BMS01 : 31|2@0+ (1,0) [0|0] ""  PT
 SG_ DEM172_SC_CCTRL_POS1_OPN_BMS01 : 17|2@0+ (1,0) [0|0] ""  PT
 SG_ DEM173_SC_CCTRL_POS2_OPN_BMS01 : 19|2@0+ (1,0) [0|0] ""  PT
 SG_ DEM174_SC_CCTRL_POS3_OPN_BMS01 : 21|2@0+ (1,0) [0|0] ""  PT
 SG_ DEM175_SC_CCTRL_NEG1_OPN_BMS01 : 23|2@0+ (1,0) [0|0] ""  PT
 SG_ DEM176_SC_CCTRL_NEG2_OPN_BMS01 : 41|2@0+ (1,0) [0|0] ""  PT
 SG_ DEM177_SC_CCTRL_PRE2_OPN_BMS01 : 43|2@0+ (1,0) [0|0] ""  PT
 SG_ DEM178_SC_CCTRL_PRE1_OPN_BMS01 : 45|2@0+ (1,0) [0|0] ""  PT
 SG_ DEM179_SC_CCTRL_LOSIDESTOP_BMS01 : 47|2@0+ (1,0) [0|0] ""  PT
 SG_ DEM180_SC_CCTRL_UNEXPECTED_BMS01 : 33|2@0+ (1,0) [0|0] ""  PT
 SG_ DEM181_SC_V_OUT_OF_RANGE_BMS01 : 35|2@0+ (1,0) [0|0] ""  PT
 SG_ DEM182_SC_V_LATCHED_UVOV_BMS01 : 37|2@0+ (1,0) [0|0] ""  PT
 SG_ DEM183_ISO_EXT_STRAT_2_BMS01 : 39|2@0+ (1,0) [0|0] ""  PT
 SG_ DEM184_SC_CANTX_CTRS_BMS01 : 57|2@0+ (1,0) [0|0] ""  PT
 SG_ DEM185_SC_CANTX_HVIL_BMS01 : 59|2@0+ (1,0) [0|0] ""  PT
 SG_ DEM186_SC_CANTX_ISOL_BMS01 : 61|2@0+ (1,0) [0|0] ""  PT
 SG_ DEM187_SC_SBC_WATCHDOG_BMS01 : 63|2@0+ (1,0) [0|0] ""  PT
 SG_ DEM188_SC_SBC_FAULT_BMS01 : 49|2@0+ (1,0) [0|0] ""  PT
 SG_ DEM189_SC_WATCHDOG_BMS01 : 51|2@0+ (1,0) [0|0] ""  PT
 SG_ DEM190_SC_SELFTEST_RAM_BMS01 : 53|2@0+ (1,0) [0|0] ""  PT
 SG_ DEM191_SC_SELFTEST_FLASH_BMS01 : 55|2@0+ (1,0) [0|0] ""  PT

BO_ 1408 BMS01_DebugEventMap7: 8 BMS01
 SG_ DEM192_CMB_ONBOARDRH_OH_BMS01 : 9|2@0+ (1,0) [0|0] ""  PT
 SG_ DEM193_CMB_ONBOARDRH_SNA_BMS01 : 11|2@0+ (1,0) [0|0] ""  PT
 SG_ DEM194_CMB_ONBOARDT_OT_BMS01 : 13|2@0+ (1,0) [0|0] ""  PT
 SG_ DEM195_CMB_ONBOARDT_CHANGE_BMS01 : 15|2@0+ (1,0) [0|0] ""  PT
 SG_ DEM196_PRESSURE_CHANGE_BMS01 : 1|2@0+ (1,0) [0|0] ""  PT
 SG_ DEM197_PRESSURE_OVER_BMS01 : 3|2@0+ (1,0) [0|0] ""  PT
 SG_ DEM198_PRESSURE_UNDER_BMS01 : 5|2@0+ (1,0) [0|0] ""  PT
 SG_ DEM199_PRESSURE_INVALID_BMS01 : 7|2@0+ (1,0) [0|0] ""  PT
 SG_ DEM200_THERMAL_EVENT_BMS01 : 25|2@0+ (1,0) [0|0] ""  PT
 SG_ DEM201_CMB_ONBOARDT_SNA_BMS01 : 27|2@0+ (1,0) [0|0] ""  PT
 SG_ DEM202_REPLACE_DESICCANT_BMS01 : 29|2@0+ (1,0) [0|0] ""  PT
 SG_ DEM203_COOLANT_FLOOD_FAULT_BMS01 : 31|2@0+ (1,0) [0|0] ""  PT
 SG_ DEM204_LOW_BRICKCAPACITY_BMS01 : 17|2@0+ (1,0) [0|0] ""  PT
 SG_ DEM205_BMS_ONBOARDT_OT_BMS01 : 19|2@0+ (1,0) [0|0] ""  PT
 SG_ DEM206_HUMIDITY_CHANGE_BMS01 : 21|2@0+ (1,0) [0|0] ""  PT
 SG_ DEM207_ISENSE_SUPPLY_CURR_BMS01 : 23|2@0+ (1,0) [0|0] ""  PT
 SG_ DEM208_SOC_LOW_BMS01 : 41|2@0+ (1,0) [0|0] ""  PT
 SG_ DEM209_SOC_TOOLOW_BMS01 : 43|2@0+ (1,0) [0|0] ""  PT
 SG_ DEM210_SOC_TOOHIGH_BMS01 : 45|2@0+ (1,0) [0|0] ""  PT
 SG_ DEM211_BALANCING_REQUIRED_BMS01 : 47|2@0+ (1,0) [0|0] ""  PT
 SG_ DEM212_DEEP_DISCHARGE_BMS01 : 33|2@0+ (1,0) [0|0] ""  PT
 SG_ DEM213_CAN1_BUS_OFF_BMS01 : 35|2@0+ (1,0) [0|0] ""  PT
 SG_ DEM214_CAN2_BUS_OFF_BMS01 : 37|2@0+ (1,0) [0|0] ""  PT
 SG_ DEM215_CAN3_BUS_OFF_BMS01 : 39|2@0+ (1,0) [0|0] ""  PT
 SG_ DEM216_OUTLET_NTC_RATNAL_BMS01 : 57|2@0+ (1,0) [0|0] ""  PT
 SG_ DEM217_FUSE_PACK_BMS01 : 59|2@0+ (1,0) [0|0] ""  PT
 SG_ DEM218_FUSE_B_OPEN_BMS01 : 61|2@0+ (1,0) [0|0] ""  PT
 SG_ DEM219_FUSE_C_OPEN_BMS01 : 63|2@0+ (1,0) [0|0] ""  PT
 SG_ DEM220_FUSE_D_OPEN_BMS01 : 49|2@0+ (1,0) [0|0] ""  PT
 SG_ DEM221_FUSE_E_OPEN_BMS01 : 51|2@0+ (1,0) [0|0] ""  PT
 SG_ DEM222_PUMP_DRY_RUN_BMS01 : 53|2@0+ (1,0) [0|0] ""  PT
 SG_ DEM223_PUMP_PERFORMANCE_BMS01 : 55|2@0+ (1,0) [0|0] ""  PT

BO_ 1472 BMS01_DebugEventMap8: 8 BMS01
 SG_ DEM224_PUMP_LIN_FAILURE_BMS01 : 9|2@0+ (1,0) [0|0] ""  PT
 SG_ DEM225_PUMP_SUPPLY_VOLTAGE_BMS01 : 11|2@0+ (1,0) [0|0] ""  PT
 SG_ DEM226_PUMP_RECOVERY_FAIL_BMS01 : 13|2@0+ (1,0) [0|0] ""  PT
 SG_ DEM227_CTR_POS_OPENED_BMS01 : 15|2@0+ (1,0) [0|0] ""  PT
 SG_ DEM228_CTR_NEG_OPENED_BMS01 : 1|2@0+ (1,0) [0|0] ""  PT
 SG_ DEM229_STRSET_SLAVE1_FAULT_BMS01 : 3|2@0+ (1,0) [0|0] ""  PT
 SG_ DEM230_STRSET_SLAVE2_FAULT_BMS01 : 5|2@0+ (1,0) [0|0] ""  PT
 SG_ DEM231_CTRSAUX_CLFAIL_HVON_BMS01 : 7|2@0+ (1,0) [0|0] ""  PT
 SG_ DEM232_CTRSAUX_CLFAIL_VDIF_BMS01 : 25|2@0+ (1,0) [0|0] ""  PT
 SG_ DEM233_CTRSAUX_POS1_OPENED_BMS01 : 27|2@0+ (1,0) [0|0] ""  PT
 SG_ DEM234_CTRSAUX_NEG1_OPENED_BMS01 : 29|2@0+ (1,0) [0|0] ""  PT
 SG_ DEM235_CTRSAUX_POS1_WELDED_BMS01 : 31|2@0+ (1,0) [0|0] ""  PT
 SG_ DEM236_CTRSAUX_NEG1_WELDED_BMS01 : 17|2@0+ (1,0) [0|0] ""  PT
 SG_ DEM237_CTRSAUX_POS1_PULLIN_BMS01 : 19|2@0+ (1,0) [0|0] ""  PT
 SG_ DEM238_CTRSAUX_NEG1_PULLIN_BMS01 : 21|2@0+ (1,0) [0|0] ""  PT
 SG_ DEM239_INLET_NTC_RATNAL_BMS01 : 23|2@0+ (1,0) [0|0] ""  PT
 SG_ DEM240_INLET_NTC_HI_BMS01 : 41|2@0+ (1,0) [0|0] ""  PT
 SG_ DEM241_INLET_NTC_LO_BMS01 : 43|2@0+ (1,0) [0|0] ""  PT
 SG_ DEM242_VOLTAGE_LINK2_RATNA_BMS01 : 45|2@0+ (1,0) [0|0] ""  PT
 SG_ DEM243_VOLTAGE_LINK2_HI_BMS01 : 47|2@0+ (1,0) [0|0] ""  PT
 SG_ DEM244_VOLTAGE_LINK2_LO_BMS01 : 33|2@0+ (1,0) [0|0] ""  PT
 SG_ DEM245_CMB_ONBOARD_IMPOSSI_BMS01 : 35|2@0+ (1,0) [0|0] ""  PT
 SG_ DEM246_VOLTAGE_LINK1_HI_BMS01 : 37|2@0+ (1,0) [0|0] ""  PT
 SG_ DEM247_VOLTAGE_LINK1_LO_BMS01 : 39|2@0+ (1,0) [0|0] ""  PT
 SG_ DEM248_NTC_SUPPLY_LO_BMS01 : 57|2@0+ (1,0) [0|0] ""  PT
 SG_ DEM249_NTC_SUPPLY_HI_BMS01 : 59|2@0+ (1,0) [0|0] ""  PT
 SG_ DEM250_VOLTAGE_LINK3_RATNA_BMS01 : 61|2@0+ (1,0) [0|0] ""  PT
 SG_ DEM251_VOLTAGE_LINK3_HI_BMS01 : 63|2@0+ (1,0) [0|0] ""  PT
 SG_ DEM252_VOLTAGE_LINK3_LO_BMS01 : 49|2@0+ (1,0) [0|0] ""  PT
 SG_ DEM253_BALANCING_STUCK_BMS01 : 51|2@0+ (1,0) [0|0] ""  PT
 SG_ DEM254_ARM_EXCEPTION_BMS01 : 53|2@0+ (1,0) [0|0] ""  PT
 SG_ DEM255_ERROR_HOOKS_BMS01 : 55|2@0+ (1,0) [0|0] ""  PT

BO_ 832 BMS01_DebugEventMap9: 8 BMS01
 SG_ DEM256_XCP_CAL_CHANGE_BMS01 : 9|2@0+ (1,0) [0|0] ""  PT
 SG_ DEM257_XCP_CAL_PERM_CHANGE_BMS01 : 11|2@0+ (1,0) [0|0] ""  PT
 SG_ DEM258_TASK_TIME_OVERFLOW_BMS01 : 13|2@0+ (1,0) [0|0] ""  PT
 SG_ DEM259_ISO_CIRCUIT_BMS01 : 15|2@0+ (1,0) [0|0] ""  PT
 SG_ DEM260_COOLANT_MOIST_FAULT_BMS01 : 1|2@0+ (1,0) [0|0] ""  PT
 SG_ DEM261_COOLANT_FLOOD_WARN_BMS01 : 3|2@0+ (1,0) [0|0] ""  PT
 SG_ DEM262_COOLANT_MOIST_WARN_BMS01 : 5|2@0+ (1,0) [0|0] ""  PT
 SG_ DEM263_MODULET_IMPLAUSIBLE_BMS01 : 7|2@0+ (1,0) [0|0] ""  PT
 SG_ DEM264_REQUEST_ON_WITH_HV__BMS01 : 25|2@0+ (1,0) [0|0] ""  PT
 SG_ DEM265_CSERS_PCODE_BMS01 : 27|2@0+ (1,0) [0|0] ""  PT
 SG_ DEM266_PRELIM_CNTR_CL_FAIL_BMS01 : 29|2@0+ (1,0) [0|0] ""  PT
 SG_ DEM267_FLUIDLVL_LOW_BMS01 : 31|2@0+ (1,0) [0|0] ""  PT
 SG_ DEM268_FLUIDLVL_FAILURE_BMS01 : 17|2@0+ (1,0) [0|0] ""  PT
 SG_ DEM269_SC_COOLANT_CONTAM_BMS01 : 19|2@0+ (1,0) [0|0] ""  PT
 SG_ DEM270_SC_COOLANT_MIA_BMS01 : 21|2@0+ (1,0) [0|0] ""  PT
 SG_ DEM271_PRESSURE_VHI_BMS01 : 23|2@0+ (1,0) [0|0] ""  PT
 SG_ DEM272_PRESSURE_VLO_BMS01 : 41|2@0+ (1,0) [0|0] ""  PT
 SG_ DEM273_SC_COOLANT_FAIL_BMS01 : 43|2@0+ (1,0) [0|0] ""  PT
 SG_ DEM274_CTRSAUX_POS2_OPENED_BMS01 : 45|2@0+ (1,0) [0|0] ""  PT
 SG_ DEM275_CTRSAUX_POS3_OPENED_BMS01 : 47|2@0+ (1,0) [0|0] ""  PT
 SG_ DEM276_CTRSAUX_POS2_WELDED_BMS01 : 33|2@0+ (1,0) [0|0] ""  PT
 SG_ DEM277_CTRSAUX_POS3_WELDED_BMS01 : 35|2@0+ (1,0) [0|0] ""  PT
 SG_ DEM278_CTRSAUX_POS2_PULLIN_BMS01 : 37|2@0+ (1,0) [0|0] ""  PT
 SG_ DEM279_CTRSAUX_POS3_PULLIN_BMS01 : 39|2@0+ (1,0) [0|0] ""  PT
 SG_ DEM280_CMB_HUMIDITY_TEMP_C_BMS01 : 57|2@0+ (1,0) [0|0] ""  PT
 SG_ DEM281_THERMAL_EVENT_CMB_R_BMS01 : 59|2@0+ (1,0) [0|0] ""  PT
 SG_ DEM282_CUS_BRICKOV_BMS01 : 61|2@0+ (1,0) [0|0] ""  PT
 SG_ DEM283_CUS_BRICKUV_BMS01 : 63|2@0+ (1,0) [0|0] ""  PT
 SG_ DEM284_CUS_OVERCHRG_BMS01 : 49|2@0+ (1,0) [0|0] ""  PT
 SG_ DEM285_CUS_OVERDCHRG_BMS01 : 51|2@0+ (1,0) [0|0] ""  PT
 SG_ DEM286_CUS_CURRENT_CHG_BMS01 : 53|2@0+ (1,0) [0|0] ""  PT
 SG_ DEM287_CUS_CURRENT_DCHG_BMS01 : 55|2@0+ (1,0) [0|0] ""  PT

BO_ 1600 SC01_DebugSlowMpex: 8 SC01
 SG_ FeeInitStatus_SC01 m43 : 23|16@0+ (1,0) [0|65535] ""  PT
 SG_ pressureFiltered_SC01 m22 : 47|8@0+ (0.4,0) [0|102] "psi"  PT
 SG_ shunt2IntegralAs_SC01 m46 : 23|32@0- (1,0) [-2147483648|2147483647] "As"  PT
 SG_ shunt1IntegralAs_SC01 m45 : 31|32@0- (1,0) [-2147483648|2147483647] "As"  PT
 SG_ selfTestStartupFault_SC01 m22 : 39|8@0+ (1,0) [0|255] ""  PT
 SG_ sbcARTimerStatus_SC01 m45 : 11|4@0+ (1,0) [0|15] ""  PT
 SG_ sbcARTimerValue_SC01 m45 : 23|8@0+ (1,0) [0|255] "s"  PT
 SG_ ESM_EFUSE_SAFETY_CHECK_FAIL_SC01 m21 : 41|1@0+ (1,0) [0|0] ""  PT
 SG_ ESM_EFUSE_SINGLEBIT_ERROR_SC01 m21 : 42|1@0+ (1,0) [0|0] ""  PT
 SG_ cmbVAIndex_SC01 m44 : 31|8@0+ (1,0) [0|0] ""  PT
 SG_ minVACMB_SC01 m44 : 39|16@0+ (0.0001,0) [0|6.5] "V"  PT
 SG_ maxVACMB_SC01 m44 : 55|16@0+ (0.0001,0) [0|6.5] "V"  PT
 SG_ pumpInternalFaultError_SC01 m23 : 16|1@0+ (1,0) [0|0] ""  PT
 SG_ pumpShortCircuitError_SC01 m23 : 17|1@0+ (1,0) [0|0] ""  PT
 SG_ pumpElectricError_SC01 m23 : 19|2@0+ (1,0) [0|0] ""  PT
 SG_ pumpPostRunMode_SC01 m23 : 22|3@0+ (1,0) [0|0] ""  PT
 SG_ pumpRsError_SC01 m23 : 23|1@0+ (1,0) [0|0] ""  PT
 SG_ pumpWakeUpStatus_SC01 m23 : 25|2@0+ (1,0) [0|0] ""  PT
 SG_ pumpRpmMonStat_SC01 m23 : 27|2@0+ (1,0) [0|0] ""  PT
 SG_ pumpPwmInStat_SC01 m23 : 29|2@0+ (1,0) [0|0] ""  PT
 SG_ pumpDiagTriggered_SC01 m23 : 30|1@0+ (1,0) [0|0] ""  PT
 SG_ pumpHwFault_SC01 m23 : 31|1@0+ (1,0) [0|0] ""  PT
 SG_ pumpPumpState_SC01 m23 : 34|3@0+ (1,0) [0|0] ""  PT
 SG_ pumpBlockError_SC01 m23 : 36|2@0+ (1,0) [0|0] ""  PT
 SG_ pumpLinError_SC01 m23 : 37|1@0+ (1,0) [0|0] ""  PT
 SG_ pumpDryRun_SC01 m23 : 39|2@0+ (1,0) [0|0] ""  PT
 SG_ pumpOverCurrent_SC01 m23 : 41|2@0+ (1,0) [0|0] ""  PT
 SG_ pumpVoltageDeratingError_SC01 m23 : 42|1@0+ (1,0) [0|0] ""  PT
 SG_ pumpSupVoltageError_SC01 m23 : 44|2@0+ (1,0) [0|0] ""  PT
 SG_ pumpUnderVoltage_SC01 m23 : 45|1@0+ (1,0) [0|0] ""  PT
 SG_ pumpOverVoltage_SC01 m23 : 46|1@0+ (1,0) [0|0] ""  PT
 SG_ pumpTempProtect_SC01 m23 : 47|1@0+ (1,0) [0|0] ""  PT
 SG_ pumpOverTempDeratingErr_SC01 m23 : 48|1@0+ (1,0) [0|0] ""  PT
 SG_ pumpOverTemperature_SC01 m23 : 50|2@0+ (1,0) [0|0] ""  PT
 SG_ cmbSM30MinSettleTime_SC01 m44 : 15|16@0+ (1,0) [0|65535] "ms"  PT
 SG_ cmbSM30SettleTimeFault_SC01 m32 : 42|1@0+ (1,0) [0|1] ""  PT
 SG_ pressure2_SC01 m22 : 15|8@0+ (0.4,0) [0|102] "psi"  PT
 SG_ cmbSM29ScoutTempIndex_SC01 m42 : 15|8@0+ (1,0) [0|255] ""  PT
 SG_ cmbSM19ScoutPDO_SC01 m42 : 55|16@0+ (0.0001,0) [0|6.5] "V"  PT
 SG_ cmbMaxSM15ratio_SC01 m41 : 39|16@0+ (0.00390625,0) [0|255.99609375] ""  PT
 SG_ cmbMinSM15ratio_SC01 m41 : 55|16@0+ (0.00390625,0) [0|255.99609375] ""  PT
 SG_ cmbMinSM17Ratio m42 : 39|16@0+ (0.00390625,0) [0|255.99609375] ""  PT
 SG_ cmbMaxSM17Ratio m42 : 23|16@0+ (0.00390625,0) [0|255.99609375] ""  PT
 SG_ cmbMaxSM16DiffC2S_SC01 m41 : 23|16@0+ (0.2,0) [0|13107] "mV"  PT
 SG_ isolationResInternRelaxed_SC01 m32 : 23|16@0+ (2,0) [0|130000] "kOhm"  PT
 SG_ pressureSensH2Concentr_SC01 m40 : 55|16@0+ (0.0025,0) [0|163.8375] "% H2"  PT
 SG_ pressureSensIntakePres_SC01 m40 : 39|16@0+ (0.0078125,-250) [-250|251.99] "kPa"  PT
 SG_ pressureSensIntakeTemp_SC01 m40 : 23|16@0+ (0.03125,-273) [-273|1734.96875] "C"  PT
 SG_ pressureSensRelHumidity_SC01 m40 : 15|8@0+ (0.4,0) [0|100] "%"  PT
 SG_ isolationSelftestMaxDiff_SC01 m32 : 39|8@0+ (0.1,0) [0|25.5] "V"  PT
 SG_ FEESector2Flags_SC01 m22 : 23|16@0+ (1,0) [0|0] ""  PT
 SG_ appTask500HzMaxAvg_SC01 m41 : 15|8@0+ (0.02,0) [0|5.1] "ms"  PT
 SG_ safetyHangLastLinkReg_SC01 m39 : 23|32@0+ (1,0) [0|4294967295] ""  PT
 SG_ safetyHangPresentLinkReg_SC01 m38 : 23|32@0+ (1,0) [0|4294967295] ""  PT
 SG_ safetyHangDataFaultStatus_SC01 m37 : 23|32@0+ (1,0) [0|4294967295] ""  PT
 SG_ safetyHangDataFaultAddr_SC01 m36 : 23|32@0+ (1,0) [0|4294967295] ""  PT
 SG_ safetyHangLastARMMode_SC01 m35 : 63|8@0+ (1,0) [0|255] ""  PT
 SG_ safetyHangPresARMMode_SC01 m35 : 55|8@0+ (1,0) [0|255] ""  PT
 SG_ safetyHangESMGrp3Reg_SC01 m35 : 23|32@0+ (1,0) [0|4294967295] ""  PT
 SG_ safetyHangInstrFaultStatus_SC01 m34 : 23|32@0+ (1,0) [0|4294967295] ""  PT
 SG_ safetyHangInstrFaultAddr_SC01 m33 : 23|32@0+ (1,0) [0|4294967295] ""  PT
 SG_ pressure_SC01 m4 : 63|8@0+ (0.4,0) [0|102] "psi"  PT
 SG_ cmbMaxSM33Diff_SC01 m31 : 15|8@0+ (0.001,0) [0|0.255] "V"  PT
 SG_ cmbMinSM29Diff_SC01 m17 : 15|8@0+ (0.001,0) [0|0.255] "V"  PT
 SG_ cmbSM4MinIndex_SC01 m24 : 15|8@0+ (1,0) [0|0] ""  PT
 SG_ cmbSM4DiffC2_SC01 m31 : 23|16@0+ (0.0001,0) [0|6.5] "V"  PT
 SG_ cmbMinSM4Diff_SC01 m31 : 39|16@0+ (0.0001,0) [0|6.5] "V"  PT
 SG_ cmbMaxSM4Diff_SC01 m21 : 55|16@0+ (0.0001,0) [0|6.5] "V"  PT
 SG_ cmbSM27MinIndex_SC01 m15 : 63|8@0+ (1,0) [0|0] ""  PT
 SG_ cmbSM27DiffC2_SC01 m24 : 55|16@0+ (0.0001,0) [0|6.5] "V"  PT
 SG_ cmbMinSM27Diff_SC01 m31 : 55|16@0+ (0.0001,0) [0|6.5] "V"  PT
 SG_ cmbMaxSM27Diff_SC01 m25 : 55|16@0+ (0.0001,0) [0|6.5] "V"  PT
 SG_ adcDriverFail_SC01 m4 : 51|4@0+ (1,0) [0|0] ""  PT
 SG_ mainUcHvilState_SC01 m32 : 41|2@0+ (1,0) [0|0] ""  PT
 SG_ mainUcIntIsoErr_SC01 m32 : 13|2@0+ (1,0) [0|0] ""  PT
 SG_ mainUcExtIsoErr_SC01 m32 : 15|2@0+ (1,0) [0|0] ""  PT
 SG_ safetyUcThermalStatus_SC01 m32 : 9|2@0+ (1,0) [0|0] ""  PT
 SG_ mainUcThermalStatus_SC01 m32 : 11|2@0+ (1,0) [0|0] ""  PT
 SG_ selfTestErrorAddress_SC01 m30 : 23|32@0+ (1,0) [0|4294967295] ""  PT
 SG_ selfTestDataFaultStatus_SC01 m29 : 23|32@0+ (1,0) [0|4294967295] ""  PT
 SG_ selfTestInstrFaultAddr_SC01 m28 : 23|32@0+ (1,0) [0|4294967295] ""  PT
 SG_ selfTestDataFaultAddr_SC01 m27 : 23|32@0+ (1,0) [0|4294967295] ""  PT
 SG_ selfTestInstrFaultStatus_SC01 m26 : 23|32@0+ (1,0) [0|4294967295] ""  PT
 SG_ internalIsolationError_SC01 m25 : 11|2@0+ (1,0) [0|0] ""  PT
 SG_ externalIsolationError_SC01 m25 : 13|2@0+ (1,0) [0|0] ""  PT
 SG_ isolationTestState_SC01 m25 : 9|2@0+ (1,0) [0|0] ""  PT
 SG_ isolationResistanceIntern_SC01 m25 : 23|16@0+ (2,0) [0|130000] "kOhm"  PT
 SG_ isolationResistanceExtern_SC01 m25 : 39|16@0+ (2,0) [0|130000] "kOhm"  PT
 SG_ maxAdolV13Diff_SC01 m24 : 23|16@0+ (0.0001,0) [0|6.5] "V"  PT
 SG_ maxAdolV7Diff_SC01 m24 : 39|16@0+ (0.0001,0) [0|6.5] "V"  PT
 SG_ pumpType_SC01 m23 : 15|8@0+ (1,0) [0|0] ""  PT
 SG_ pumpPhaseCurrent_SC01 m18 : 47|8@0+ (0.1,0) [0|0] "A"  PT
 SG_ hvWithstandTestQual_SC01 m21 : 15|8@0+ (1,0) [0|255] ""  PT
 SG_ ESM_RAM_ODD_ADDR_UNCORR_SC01 m21 : 18|1@0+ (1,0) [0|0] ""  PT
 SG_ ESM_RAM_EVEN_ADDR_UNCORR_SC01 m21 : 17|1@0+ (1,0) [0|0] ""  PT
 SG_ ESM_FMC_UNCORR_ERR_SC01 m21 : 40|1@0+ (1,0) [0|0] ""  PT
 SG_ ESM_RAM_ODDECC_UNCORR_SC01 m21 : 23|1@0+ (1,0) [0|0] ""  PT
 SG_ ESM_RAM_EVENECC_UNCORR_SC01 m21 : 22|1@0+ (1,0) [0|0] ""  PT
 SG_ ESM_EFUSE_FARM_ERR_SC01 m21 : 21|1@0+ (1,0) [0|0] ""  PT
 SG_ ESM_RTI_WWD_NMI_SC01 m21 : 20|1@0+ (1,0) [0|0] ""  PT
 SG_ ESM_TCM_ECC_LIVE_LOCK_SC01 m21 : 19|1@0+ (1,0) [0|0] ""  PT
 SG_ ESM_RAM_ODD_UNCORR_ERR_SC01 m21 : 16|1@0+ (1,0) [0|0] ""  PT
 SG_ ESM_RAM_EVEN_UNCORR_ERR_SC01 m21 : 31|1@0+ (1,0) [0|0] ""  PT
 SG_ ESM_FMC_ADDR_UNCORR_ERR_SC01 m21 : 30|1@0+ (1,0) [0|0] ""  PT
 SG_ ESM_CCM4_COMPARE_FAULT_SC01 m21 : 29|1@0+ (1,0) [0|0] ""  PT
 SG_ ESM_RAM_ODD_CORR_ERR_SC01 m21 : 28|1@0+ (1,0) [0|0] ""  PT
 SG_ ESM_RAM_EVEN_CORR_ERR_SC01 m21 : 27|1@0+ (1,0) [0|0] ""  PT
 SG_ ESM_CLK_MONITOR_SC01 m21 : 26|1@0+ (1,0) [0|0] ""  PT
 SG_ ESM_PLL_SLIP_SC01 m21 : 25|1@0+ (1,0) [0|0] ""  PT
 SG_ ESM_FMC_CORR_ERR_SC01 m21 : 24|1@0+ (1,0) [0|0] ""  PT
 SG_ analogMMCUSleepTrigger_SC01 m20 : 55|8@0+ (0.015,0) [0|0] "V"  PT
 SG_ analogPyroLSDStatus_SC01 m20 : 63|8@0+ (0.015,0) [0|0] "V"  PT
 SG_ analogGPIO2Volt_SC01 m19 : 47|8@0+ (0.1,0) [0|25] "V"  PT
 SG_ analogGPIO2Current_SC01 m19 : 55|8@0+ (0.015,0) [0|3.825] "A"  PT
 SG_ analogGPIO1Volt_SC01 m19 : 63|8@0+ (0.1,0) [0|25] "V"  PT
 SG_ analogGPIO1Current_SC01 m20 : 15|8@0+ (0.015,0) [0|3.825] "A"  PT
 SG_ currentModuleMax_SC01 m1 : 55|16@0+ (0.1,-3200) [-3200|3200] "A"  PT
 SG_ currentModuleMin_SC01 m1 : 39|16@0+ (0.1,-3200) [-3200|3200] "A"  PT
 SG_ cmbSumOfCellSTATRef_SC01 m20 : 39|16@0+ (0.0015,0) [0|131.07] "V"  PT
 SG_ cmbSumOfCells_SC01 m20 : 23|16@0+ (0.0015,0) [0|131.07] "V"  PT
 SG_ maxCMBDieTemp_SC01 m1 : 31|8@0+ (1,-40) [-40|200] "C"  PT
 SG_ minCMBDieTemp_SC01 m1 : 23|8@0+ (1,-40) [-40|200] "C"  PT
 SG_ appTaskSpiRxTx_SC01 m16 : 15|8@0+ (0.02,0) [0|5.1] "ms"  PT
 SG_ variantCodingCounts_SC01 m4 : 39|8@0+ (1,0) [0|0] ""  PT
 SG_ cmbMaxUpdateTime_SC01 m17 : 23|8@0+ (2,0) [0|500] "ms"  PT
 SG_ pumpSetSpeed_SC01 m18 : 55|8@0+ (1,0) [0|255] "PCT"  PT
 SG_ hvilResistance_SC01 m17 : 31|8@0+ (2,0) [0|0] "Ohm"  PT
 SG_ cmbAvgUpdateTime_SC01 m18 : 63|8@0+ (2,0) [0|500] "ms"  PT
 SG_ pumpTemperature_SC01 m18 : 39|8@0+ (1,-50) [0|0] "C"  PT
 SG_ pumpSpeed_SC01 m18 : 15|8@0+ (1,0) [0|255] "PCT"  PT
 SG_ pumpVoltage_SC01 m18 : 23|8@0+ (0.1,0) [0|0] "V"  PT
 SG_ pumpCurrent_SC01 m18 : 31|8@0+ (0.1,0) [0|0] "A"  PT
 SG_ posLink3_SC01 m17 : 39|16@0+ (0.04,-1250) [-1250|1371.4] "V"  PT
 SG_ negLink3_SC01 m17 : 55|16@0+ (0.04,-1250) [-1250|1371.4] "V"  PT
 SG_ posLink2_SC01 m16 : 39|16@0+ (0.04,-1250) [-1250|1371.4] "V"  PT
 SG_ negLink2_SC01 m16 : 55|16@0+ (0.04,-1250) [-1250|1371.4] "V"  PT
 SG_ cmbNrOfSamples_SC01 m16 : 23|8@0+ (1,0) [0|0] ""  PT
 SG_ cmbTaskTime_SC01 m16 : 31|8@0+ (1,0) [0|0] "ms"  PT
 SG_ appTask500HzMax_SC01 m15 : 15|8@0+ (0.02,0) [0|5.1] "ms"  PT
 SG_ moduleCount_SC01 m6 : 15|8@0+ (1,0) [0|0] ""  PT
 SG_ analogHallSense_SC01 m15 : 23|16@0+ (0.0001,0) [0|6.5535] "V"  PT
 SG_ cmbMaxDiagStepPeriodicity_SC01 m15 : 55|8@0+ (4,0) [0|1019] "ms"  PT
 SG_ minBrickVoltageLimit_SC01 m15 : 39|16@0+ (0.0001,0) [0|6.5535] "V"  PT
 SG_ appTask100Hz_SC01 m14 : 63|8@0+ (0.02,0) [0|5.1] "ms"  PT
 SG_ appTask10Hz_SC01 m14 : 55|8@0+ (0.02,0) [0|5.1] "ms"  PT
 SG_ appTaskAnalog_SC01 m14 : 47|8@0+ (0.02,0) [0|5.1] "ms"  PT
 SG_ appTaskADC_SC01 m14 : 39|8@0+ (0.02,0) [0|5.1] "ms"  PT
 SG_ appTask500HzAvg_SC01 m14 : 31|8@0+ (0.02,0) [0|5.1] "ms"  PT
 SG_ appTaskSBC_SC01 m14 : 23|8@0+ (0.02,0) [0|5.1] "ms"  PT
 SG_ appTaskCMBDriver_SC01 m14 : 15|8@0+ (0.02,0) [0|5.1] "ms"  PT
 SG_ safetyInitTime_SC01 m12 : 15|8@0+ (2,0) [0|500] "ms"  PT
 SG_ debugSlowMpex_SC01 M : 7|8@0+ (1,0) [0|0] ""  PT
 SG_ sbcWUAuto_SC01 m11 : 9|1@0+ (1,0) [0|0] ""  PT
 SG_ sbcWUUnknown_SC01 m11 : 8|1@0+ (1,0) [0|0] ""  PT
 SG_ sbcWUDebug_SC01 m11 : 10|1@0+ (1,0) [0|0] ""  PT
 SG_ sbcWUPOR_SC01 m11 : 11|1@0+ (1,0) [0|0] ""  PT
 SG_ sbcWUPressure_SC01 m11 : 12|1@0+ (1,0) [0|0] ""  PT
 SG_ sbcWUClock_SC01 m11 : 13|1@0+ (1,0) [0|0] ""  PT
 SG_ sbcWUCAN_SC01 m11 : 14|1@0+ (1,0) [0|0] ""  PT
 SG_ sbcWUKey_SC01 m11 : 15|1@0+ (1,0) [0|0] ""  PT
 SG_ mux960N3VRef_SC01 m13 : 39|16@0+ (-0.000805664,0) [0|0] "V"  PT
 SG_ mux960P2P5VRef_SC01 m13 : 55|16@0+ (0.000805664,0) [0|0] "V"  PT
 SG_ mux440Gnd_SC01 m10 : 15|8@0+ (0.000805664,0) [0|0] "V"  PT
 SG_ analogHallGain_SC01 m13 : 23|16@0+ (1E-005,0.8) [0.8|1.455] "k"  PT
 SG_ analogHallOffset_SC01 m13 : 15|8@0+ (0.0001,-0.005) [-0.005|0.0205] "V"  PT
 SG_ negPackPrime_SC01 m12 : 55|16@0+ (0.04,-1250) [-1250|1250] "V"  PT
 SG_ posPackPrime_SC01 m12 : 39|16@0+ (0.04,-1250) [-1250|1250] "V"  PT
 SG_ packVoltage_SC01 m12 : 23|16@0+ (0.04,-1250) [-1250|1250] "V"  PT
 SG_ sleepTime_SC01 m11 : 23|16@0+ (1,0) [0|0] "s"  PT
 SG_ analogNegHVOffset_SC01 m10 : 63|8@0+ (1,-120) [-120|120] "Bits"  PT
 SG_ analogPosHVOffset_SC01 m10 : 55|8@0+ (1,-120) [-120|120] "Bits"  PT
 SG_ analogNegHVGain_SC01 m10 : 39|16@0+ (1E-005,0.8) [0|0] "k"  PT
 SG_ analogPosHVGain_SC01 m10 : 23|16@0+ (1E-005,0.8) [0.8|1.45535] "k"  PT
 SG_ mux910Gnd_SC01 m8 : 15|8@0+ (0.000805664,0) [0|0] "V"  PT
 SG_ mux960Gnd_SC01 m9 : 15|8@0+ (0.000805664,0) [0|0] "V"  PT
 SG_ analogAddr5_SC01 m9 : 55|16@0+ (0.000805861,0) [0|0] "V"  PT
 SG_ analogAddr4_SC01 m9 : 39|16@0+ (0.000805861,0) [0|0] "V"  PT
 SG_ analogAddr3_SC01 m9 : 23|16@0+ (0.000805861,0) [0|0] "V"  PT
 SG_ analogAddr2_SC01 m8 : 55|16@0+ (0.000805861,0) [0|0] "V"  PT
 SG_ analogAddr1_SC01 m8 : 39|16@0+ (0.000805861,0) [0|0] "V"  PT
 SG_ analogAddr0_SC01 m8 : 23|16@0+ (0.000805861,0) [0|0] "V"  PT
 SG_ sbcVREF2P5_SC01 m7 : 15|8@0+ (0.003222656,2.25) [2.25|3.0715] "V"  PT
 SG_ mux910N3VRef_SC01 m7 : 39|16@0+ (-0.000805664,0) [0|0] "V"  PT
 SG_ mux910P2P5VRef_SC01 m7 : 55|16@0+ (0.000805664,0) [0|0] "V"  PT
 SG_ analogHvilCurrentPWM_SC01 m3 : 31|8@0+ (1,0) [0|255] "mA"  PT
 SG_ analogSBCSupply_SC01 m4 : 47|8@0+ (0.1,0) [0|25] "V"  PT
 SG_ analogHvilCurrent_SC01 m3 : 23|8@0+ (1,0) [0|255] "mA"  PT
 SG_ analogPressureSense_SC01 m4 : 23|8@0+ (0.025,0) [0|6.375] "V"  PT
 SG_ analog5VSensorSupply_SC01 m4 : 15|8@0+ (0.025,0) [0|6.375] "V"  PT
 SG_ analogPrechgRel2CoilMinus_SC01 m2 : 23|8@0+ (0.2,0) [0|51] "V"  PT
 SG_ analogPrechgRel1CoilMinus_SC01 m3 : 55|8@0+ (0.2,0) [0|51] "V"  PT
 SG_ analogNegCntr3CoilMinus_SC01 m2 : 31|8@0+ (0.2,0) [0|51] "V"  PT
 SG_ analogNegCntr2CoilMinus_SC01 m2 : 39|8@0+ (0.2,0) [0|51] "V"  PT
 SG_ analogNegCntr1CoilMinus_SC01 m2 : 47|8@0+ (0.2,0) [0|51] "V"  PT
 SG_ analogPosCntr3CoilMinus_SC01 m2 : 55|8@0+ (0.2,0) [0|51] "V"  PT
 SG_ analogPosCntr2CoilMinus_SC01 m2 : 63|8@0+ (0.2,0) [0|51] "V"  PT
 SG_ analogPosCntr1CoilMinus_SC01 m3 : 15|8@0+ (0.2,0) [0|51] "V"  PT
 SG_ minModuleTemperature_SC01 m1 : 15|8@0+ (1,-40) [-40|200] "C"  PT
 SG_ maxModuleTemperature_SC01 m2 : 15|8@0+ (1,-40) [-40|200] "C"  PT
 SG_ analogHvilReturn_SC01 m3 : 39|8@0+ (0.1,0) [0|25] "V"  PT
 SG_ analog5VDSupply_SC01 m3 : 47|8@0+ (0.025,0) [0|6.375] "V"  PT
 SG_ analogHvilOut_SC01 m3 : 63|8@0+ (0.1,0) [0|25] "V"  PT
 SG_ analogCurrentSensor12V_SC01 m4 : 31|8@0+ (0.075,0) [0|19] "V"  PT
 SG_ cmbErrorCounter_SC01 m6 : 47|8@0+ (1,0) [0|255] ""  PT
 SG_ PECErrorCounter_SC01 m6 : 39|8@0+ (1,0) [0|255] ""  PT
 SG_ maxVREF2_SC01 m7 : 23|16@0+ (0.0001,0) [0|6.5] "V"  PT
 SG_ minVREF2_SC01 m6 : 55|16@0+ (0.0001,0) [0|6.5] "V"  PT
 SG_ currentPlausiCounter_SC01 m5 : 15|8@0+ (1,0) [0|0] ""  PT
 SG_ hallCurrentOffset_SC01 m5 : 39|16@0+ (0.001,-30) [-30|30] "A"  PT
 SG_ sumOfCurrentsFiltered_SC01 m5 : 23|16@0+ (0.1,-3200) [-3200|3353.5] "A"  PT
 SG_ hallCurrentAveraged_SC01 m5 : 55|16@0+ (0.1,-3200) [-3200|3200] "A"  PT
 SG_ analogHallSupply_SC01 m6 : 23|16@0+ (0.0005,0) [0|32.7675] "V"  PT
 SG_ SWVersion_SC01 m11 : 39|32@0+ (1,0) [0|4294967295] ""  PT
 SG_ contactorControlPos1_SC01 m19 : 23|4@0+ (1,0) [0|7] ""  PT
 SG_ contactorControlNeg1_SC01 m19 : 19|4@0+ (1,0) [0|7] ""  PT
 SG_ contactorControlPre1_SC01 m19 : 11|4@0+ (1,0) [0|7] ""  PT
 SG_ contactorControlPos2_SC01 m19 : 31|4@0+ (1,0) [0|7] ""  PT
 SG_ contactorControlNeg2_SC01 m19 : 27|4@0+ (1,0) [0|7] ""  PT
 SG_ contactorControlPre2_SC01 m19 : 15|4@0+ (1,0) [0|7] ""  PT
 SG_ contactorControlPos3_SC01 m19 : 39|4@0+ (1,0) [0|7] ""  PT
 SG_ contactorControlNeg3_SC01 m19 : 35|4@0+ (1,0) [0|7] ""  PT

CM_ "Debug CAN.";
CM_ BU_ ME "ME Engineering Tool";
CM_ BO_ 896 "Sends the DEM Events from ID 288";
CM_ SG_ 960 regenCurrOpLkyBktThrs1_BMS01 "Leaky Bucket Discharge Threshold 1, at which derating from peak to continuous current limit starts";
CM_ SG_ 960 dischargeCurrOpLkyBktThrs1_BMS01 "Leaky Bucket Discharge Threshold 1, at which derating from peak to continuous current limit starts";
CM_ SG_ 960 currentRedundant_BMS01 "Redudant measurement of the sum of all module currents monitored by the BMS";
CM_ SG_ 1792 chargerDCOutV_BMS01 "pack voltage for fast debugging";
CM_ SG_ 1792 chargerProximity_BMS01 "Prox Measured at uC Pin";
CM_ SG_ 1792 chargerPilot_BMS01 "Measured at uC Pin";
CM_ SG_ 1792 posPackDbg_BMS01 "pack voltage for fast debugging";
CM_ SG_ 1792 negPackDbg_BMS01 "pack voltage for fast debugging";
CM_ SG_ 1792 packVoltageHVMeas_BMS01 "pack voltage for fast debugging";
CM_ BO_ 769 "Master BMS Debug Message";
CM_ SG_ 1856 hvilShutdownStrategy_BMS01 "HVIL Shutdown strategy";
CM_ SG_ 1856 SWVersionBL_BMS01 "The last 6 digits of the hexadecimal representation of the message this signal is contained in give the SW version.";
CM_ SG_ 1856 analogGPIO1Volt_BMS01 "Voltage at GPIO 1";
CM_ SG_ 1856 analogGPIO2Volt_BMS01 "Voltage at GPIO 1";
CM_ SG_ 1856 OBDMILRequested_BMS01 "Number of dtcs that are OBD relevant and confirmed";
CM_ SG_ 1856 OBDConfirmedDTCsCount_BMS01 "Number of dtcs that are OBD relevant and confirmed";
CM_ SG_ 1856 OBDFirstConfirmedDTC_BMS01 "Smallest array index of a dtc which causes the MIL to be on";
CM_ SG_ 1856 OBDFirstConfDTCWarmCyc_BMS01 "Smallest array index of a dtc which causes the MIL to be on";
CM_ SG_ 1856 OBDPermanentDTCCount_BMS01 "Number of dtcs that are OBD relevant and have permanent status true";
CM_ SG_ 1856 OBDFirstPermanentDTC_BMS01 "Smallest array index of a dtc which causes the MIL to be on";
CM_ SG_ 1856 OBDFirstPermDTCDriveCyc_BMS01 "Smallest array index of a dtc which causes the MIL to be on";
CM_ SG_ 1856 storCondSysNwOk_BMS01 "DEM Storage System Level Networking fulfilled";
CM_ SG_ 1856 storCondSysPwrOk_BMS01 "DEM Storage System Level Power Distribution fulfilled";
CM_ SG_ 1856 storCondECUOk_BMS01 "DEM Storage Condition ECU Level fulfilled";
CM_ SG_ 1856 chronoStackWrCnt_BMS01 "Chrono Stack Write Counter";
CM_ SG_ 1856 SPIRxTxDiag_BMS01 "Time for all packets in ms. Maximum of ECU cycle.";
CM_ SG_ 1856 balancingVoltageTarget_BMS01 "This signal gives the voltage threshhold, above which we balance cells above the min brick voltage. If a voltage target is set via diagnostic command, we give this instead.";
CM_ SG_ 1856 packVoltageCMB_BMS01 "Sum of all brick voltages of a pack.";
CM_ SG_ 1856 SPIRxTxTimeAllPckts_BMS01 "Time for all packets in ms. Maximum of ECU cycle.";
CM_ SG_ 1728 SPIRxTxHeaderMux3Status_BMS01 "Status of a multiplexed data in SPI Header words.";
CM_ SG_ 1728 SPIRxTxHeaderMux2Status_BMS01 "Status of a multiplexed data in SPI Header words.";
CM_ SG_ 1728 SPIRxTxHeaderMux1Status_BMS01 "Status of a multiplexed data in SPI Header words.";
CM_ SG_ 1728 SPIRxTxHeaderMux0Status_BMS01 "Status of a multiplexed data in SPI Header words.";
CM_ SG_ 1728 activeIsoTestPsbl_BMS01 "active iso test is possible";
CM_ SG_ 1728 contactorStateAux_BMS01 "As requested by PackStateManager";
CM_ SG_ 1728 packStateRequest_BMS01 "Pack State Request as sent by SCAN Interface to Pack State manager: note that pack state manager might delay this one.";
CM_ SG_ 1728 SPIRxTxTimer_BMS01 "Timer for receiving SPI packets; Counts time until all packets are received, then it resets.";
CM_ SG_ 1728 moduleTMinMaxMeanQual_BMS01 "At least one temperature sensor in the pack is working properly.";
CM_ SG_ 1728 contactorState_BMS01 "As requested by PackStateManager";
CM_ SG_ 1600 cmbVAIndex_SC01 "Signal indicates the index of the CMB in the daisy chain which has VA fault.";
CM_ SG_ 1600 cmbMaxSM15ratio_SC01 "Max difference between balanced and non balanced sampling";
CM_ SG_ 1600 cmbMinSM15ratio_SC01 "Min difference between balanced and non balanced sampling";
CM_ SG_ 1600 cmbMinSM17Ratio "The min ratio obsereved between Sn& Cn-1 and Cn & Cn-1";
CM_ SG_ 1600 cmbMaxSM17Ratio "The max ratio obsereved between Sn& Cn-1 and Cn & Cn-1";
CM_ SG_ 1600 cmbMaxSM16DiffC2S_SC01 "Max difference between (C to Cn-1) Measurement pin  and (Sn to Sn-1) balancing pin of CMB 
This will show the leakage from measurement pin to balancing pin";
CM_ SG_ 1600 safetyHangLastLinkReg_SC01 "Only sent if valid safety hang attributes are being stored in FEE sectror 3. ";
CM_ SG_ 1600 safetyHangPresentLinkReg_SC01 "Only sent if valid safety hang attributes are being stored in FEE sectror 3. ";
CM_ SG_ 1600 safetyHangDataFaultStatus_SC01 "Only sent if valid safety hang attributes are being stored in FEE sectror 3. ";
CM_ SG_ 1600 safetyHangDataFaultAddr_SC01 "Only sent if valid safety hang attributes are being stored in FEE sectror 3. ";
CM_ SG_ 1600 safetyHangLastARMMode_SC01 "Only sent if valid safety hang attributes are being stored in FEE sectror 3. ";
CM_ SG_ 1600 safetyHangPresARMMode_SC01 "Only sent if valid safety hang attributes are being stored in FEE sectror 3. ";
CM_ SG_ 1600 safetyHangESMGrp3Reg_SC01 "Only sent if valid safety hang attributes are being stored in FEE sectror 3. ";
CM_ SG_ 1600 safetyHangInstrFaultStatus_SC01 "Only sent if valid safety hang attributes are being stored in FEE sectror 3. ";
CM_ SG_ 1600 safetyHangInstrFaultAddr_SC01 "Only sent if valid safety hang attributes are being stored in FEE sectror 3. ";
CM_ SG_ 1600 cmbSM4MinIndex_SC01 "Value index of minimum delta voltage between balancing on and off / cmbMinSM27VDiff_SC01";
CM_ SG_ 1600 cmbSM27MinIndex_SC01 "Value index of minimum delta voltage between balancing on and off / cmbMinSM27VDiff_SC01";
CM_ SG_ 1600 selfTestErrorAddress_SC01 "Flash memory address which caused the fault.If the controller tries to access the memory which has the invalid ECC, the address will be captured.";
CM_ SG_ 1600 selfTestDataFaultAddr_SC01 "Only sent if selfTest state is UNSAFE";
CM_ SG_ 1600 analogGPIO2Volt_SC01 "Voltage at GPIO 1";
CM_ SG_ 1600 analogGPIO1Volt_SC01 "Voltage at GPIO 1";
CM_ SG_ 1600 cmbMaxUpdateTime_SC01 "Total time in ms it look to go through one CMB communication task";
CM_ SG_ 1600 cmbAvgUpdateTime_SC01 "Total time in ms it look to go through one CMB communication task";
CM_ SG_ 1600 moduleCount_SC01 "Number of CMBs (modules) connected to the Safety Controller.";
CM_ SG_ 1600 cmbMaxDiagStepPeriodicity_SC01 "Total time in ms it look to go through one CMB communication task";
CM_ SG_ 1600 safetyInitTime_SC01 "Time for all packets in ms. Maximum of ECU cycle.";
CM_ SG_ 1600 sbcWUAuto_SC01 "Auto wakeup is triggered when SBC is commanded to do a reset using SPI interface (e.g. bootloading process)";
CM_ SG_ 1600 sbcWUUnknown_SC01 "SPI communication to SBC failed. Wake up source unknow.";
CM_ SG_ 1600 sbcWUDebug_SC01 "This flag is set, when safety controller tries to read wake up source from SBC, after SBC has left INIT mode, which happens on JTAG debugging";
CM_ SG_ 1600 packVoltage_SC01 "Pack voltage provided by the BMS HV-measurement.";
CM_ SG_ 1600 analogPressureSense_SC01 "The voltage output of the pressure sensor. Note that the pressure sensor pinning varies from config to config. This variable outputs the voltage measured at the pin which is defined for the pressure sensor.";
CM_ SG_ 1600 sumOfCurrentsFiltered_SC01 "CurrentLocal.outputs.sumOfCurrentThroughParallelModulesFiltered_A ";
CM_ SG_ 1600 analogHallSupply_SC01 "Calibrated Hall Sensor Supply Voltage";
BA_DEF_ SG_  "GenSigSendType" ENUM  "Cyclic","OnWrite","OnWriteWithRepetition","OnChange","OnChangeWithRepetition","IfActive","IfActiveWithRepetition","NoSigSendType";
BA_DEF_  "DBName" STRING ;
BA_DEF_ BO_  "GenMsgCycleTime" INT 0 0;
BA_DEF_ BO_  "GenMsgSendType" ENUM  "Cyclic","not_used","not_used","not_used","not_used","Cyclic","not_used","IfActive","NoMsgSendType";
BA_DEF_  "BusType" STRING ;
BA_DEF_DEF_  "GenSigSendType" "Cyclic";
BA_DEF_DEF_  "DBName" "";
BA_DEF_DEF_  "GenMsgCycleTime" 0;
BA_DEF_DEF_  "GenMsgSendType" "NoMsgSendType";
BA_DEF_DEF_  "BusType" "";
BA_ "BusType" "CAN";
BA_ "DBName" "debug";
BA_ "GenMsgCycleTime" BO_ 960 1000;
BA_ "GenMsgCycleTime" BO_ 771 10000;
BA_ "GenMsgCycleTime" BO_ 1792 100;
BA_ "GenMsgCycleTime" BO_ 769 100;
BA_ "GenMsgCycleTime" BO_ 1856 1000;
BA_ "GenMsgCycleTime" BO_ 1728 100;
BA_ "GenMsgCycleTime" BO_ 1024 1000;
BA_ "GenMsgCycleTime" BO_ 1088 1000;
BA_ "GenMsgCycleTime" BO_ 1152 1000;
BA_ "GenMsgCycleTime" BO_ 1216 1000;
BA_ "GenMsgCycleTime" BO_ 1280 1000;
BA_ "GenMsgCycleTime" BO_ 1344 1000;
BA_ "GenMsgCycleTime" BO_ 1408 1000;
BA_ "GenMsgCycleTime" BO_ 1472 1000;
BA_ "GenMsgCycleTime" BO_ 1600 100;
BA_ "DBName" "InternalCAN";
VAL_ 896 DEM319_HV_DISABLE_DURING_S_BMS01 3 "DEM_INVALID" 2 "DEM_FAILED" 1 "DEM_PASSED" 0 "DEM_NOTTESTED" ;
VAL_ 896 DEM318_HV_ENABLE_IMPLAUSIB_BMS01 3 "DEM_INVALID" 2 "DEM_FAILED" 1 "DEM_PASSED" 0 "DEM_NOTTESTED" ;
VAL_ 896 DEM317_STRING_SUSPECT_OPEN_BMS01 3 "DEM_INVALID" 2 "DEM_FAILED" 1 "DEM_PASSED" 0 "DEM_NOTTESTED" ;
VAL_ 896 DEM316_UNEXPCTD_BMS_ON_CAN_BMS01 3 "DEM_INVALID" 2 "DEM_FAILED" 1 "DEM_PASSED" 0 "DEM_NOTTESTED" ;
VAL_ 896 DEM315_HV_WITHSTAND_TESTS__BMS01 3 "DEM_INVALID" 2 "DEM_FAILED" 1 "DEM_PASSED" 0 "DEM_NOTTESTED" ;
VAL_ 896 DEM314_OBC_PILOT_ERROR_BMS01 3 "DEM_INVALID" 2 "DEM_FAILED" 1 "DEM_PASSED" 0 "DEM_NOTTESTED" ;
VAL_ 896 DEM313_OBC_PILOT_HIGH_BMS01 3 "DEM_INVALID" 2 "DEM_FAILED" 1 "DEM_PASSED" 0 "DEM_NOTTESTED" ;
VAL_ 896 DEM312_OBC_PROXIMITY_ERROR_BMS01 3 "DEM_INVALID" 2 "DEM_FAILED" 1 "DEM_PASSED" 0 "DEM_NOTTESTED" ;
VAL_ 896 DEM311_CTRS_END_OF_LIFE_WA_BMS01 3 "DEM_INVALID" 2 "DEM_FAILED" 1 "DEM_PASSED" 0 "DEM_NOTTESTED" ;
VAL_ 896 DEM310_BMSMIA_STRNGMSTR_AL_BMS01 3 "DEM_INVALID" 2 "DEM_FAILED" 1 "DEM_PASSED" 0 "DEM_NOTTESTED" ;
VAL_ 896 DEM309_VOLTAGE_BRICKOV_WAR_BMS01 3 "DEM_INVALID" 2 "DEM_FAILED" 1 "DEM_PASSED" 0 "DEM_NOTTESTED" ;
VAL_ 896 DEM308_PRESSURE_FLT_BMS01 3 "DEM_INVALID" 2 "DEM_FAILED" 1 "DEM_PASSED" 0 "DEM_NOTTESTED" ;
VAL_ 896 DEM307_PRESSURE_MIA_BMS01 3 "DEM_INVALID" 2 "DEM_FAILED" 1 "DEM_PASSED" 0 "DEM_NOTTESTED" ;
VAL_ 896 DEM306_SW_VERSION_MISMATCH_BMS01 3 "DEM_INVALID" 2 "DEM_FAILED" 1 "DEM_PASSED" 0 "DEM_NOTTESTED" ;
VAL_ 896 DEM305_MODULET_OVERTEMP_WA_BMS01 3 "DEM_INVALID" 2 "DEM_FAILED" 1 "DEM_PASSED" 0 "DEM_NOTTESTED" ;
VAL_ 896 DEM304_PCHG_OPENCIRCUIT_IN_BMS01 3 "DEM_INVALID" 2 "DEM_FAILED" 1 "DEM_PASSED" 0 "DEM_NOTTESTED" ;
VAL_ 896 DEM303_MODULET_UNDERTEMP_W_BMS01 3 "DEM_INVALID" 2 "DEM_FAILED" 1 "DEM_PASSED" 0 "DEM_NOTTESTED" ;
VAL_ 896 DEM302_MODULET_UT_BMS01 3 "DEM_INVALID" 2 "DEM_FAILED" 1 "DEM_PASSED" 0 "DEM_NOTTESTED" ;
VAL_ 896 DEM301_FUSI_LOCK_BMS01 3 "DEM_INVALID" 2 "DEM_FAILED" 1 "DEM_PASSED" 0 "DEM_NOTTESTED" ;
VAL_ 896 DEM300_DEBUG_SM_DISABLED_BMS01 3 "DEM_INVALID" 2 "DEM_FAILED" 1 "DEM_PASSED" 0 "DEM_NOTTESTED" ;
VAL_ 896 DEM299_5V_SENSOR_SUPPLY_OU_BMS01 3 "DEM_INVALID" 2 "DEM_FAILED" 1 "DEM_PASSED" 0 "DEM_NOTTESTED" ;
VAL_ 896 DEM298_IMPL_DRIVE_REQUEST_BMS01 3 "DEM_INVALID" 2 "DEM_FAILED" 1 "DEM_PASSED" 0 "DEM_NOTTESTED" ;
VAL_ 896 DEM297_PCHG2_OPENCIRCUIT_BMS01 3 "DEM_INVALID" 2 "DEM_FAILED" 1 "DEM_PASSED" 0 "DEM_NOTTESTED" ;
VAL_ 896 DEM296_CTRSAUX_IMPLAUSIBLE_BMS01 3 "DEM_INVALID" 2 "DEM_FAILED" 1 "DEM_PASSED" 0 "DEM_NOTTESTED" ;
VAL_ 896 DEM295_CTRSAUX_LINKV_UNSAF_BMS01 3 "DEM_INVALID" 2 "DEM_FAILED" 1 "DEM_PASSED" 0 "DEM_NOTTESTED" ;
VAL_ 896 DEM294_CANRX_PT_EMERGENCY_BMS01 3 "DEM_INVALID" 2 "DEM_FAILED" 1 "DEM_PASSED" 0 "DEM_NOTTESTED" ;
VAL_ 896 DEM293_SBC_LDT_IMPLAUSIBLE_BMS01 3 "DEM_INVALID" 2 "DEM_FAILED" 1 "DEM_PASSED" 0 "DEM_NOTTESTED" ;
VAL_ 896 DEM292_NUM_EXPECTED_STRING_BMS01 3 "DEM_INVALID" 2 "DEM_FAILED" 1 "DEM_PASSED" 0 "DEM_NOTTESTED" ;
VAL_ 896 DEM291_NUM_EXPECTED_STRING_BMS01 3 "DEM_INVALID" 2 "DEM_FAILED" 1 "DEM_PASSED" 0 "DEM_NOTTESTED" ;
VAL_ 896 DEM290_CMB_ONBOARD_DEFECT_BMS01 3 "DEM_INVALID" 2 "DEM_FAILED" 1 "DEM_PASSED" 0 "DEM_NOTTESTED" ;
VAL_ 896 DEM289_TEMP_STATE_LATCHED_BMS01 3 "DEM_INVALID" 2 "DEM_FAILED" 1 "DEM_PASSED" 0 "DEM_NOTTESTED" ;
VAL_ 896 DEM288_CURR_STATE_LATCHED_BMS01 3 "DEM_INVALID" 2 "DEM_FAILED" 1 "DEM_PASSED" 0 "DEM_NOTTESTED" ;
VAL_ 960 balancingInDriveTimer_BMS01 65535 "SNA" ;
VAL_ 960 SOCRestPolarization_BMS01 255 "SNA" ;
VAL_ 960 CoolantSensorState_BMS01 3 "OIL_OK" 2 "SENSOR_FAILURE" 1 "WATER_DETECTED" 0 "SENSOR_CAN_MIA" ;
VAL_ 960 temperatureModelOffset_BMS01 255 "SNA" ;
VAL_ 960 SOHCMinBrickHighEst_BMS01 255 "SNA" ;
VAL_ 960 SOHCMaxBrickHighEst_BMS01 255 "SNA" ;
VAL_ 960 regenCurrOpLkyBktThrs1_BMS01 255 "SNA" ;
VAL_ 960 dischargeCurrOpLkyBktThrs1_BMS01 255 "SNA" ;
VAL_ 960 regenCurrentOpLoadValue_BMS01 255 "SNA" ;
VAL_ 960 dischargeCurrOpLoadValue_BMS01 255 "SNA" ;
VAL_ 960 minBrickVoltageLimit_BMS01 65535 "SNA" ;
VAL_ 960 currentModule3Integral_BMS01 65535 "SNA" ;
VAL_ 960 currentModule2Integral_BMS01 65535 "SNA" ;
VAL_ 960 currentModule1Integral_BMS01 65535 "SNA" ;
VAL_ 960 currentModuleMin_BMS01 65535 "SNA" ;
VAL_ 960 currentModuleMax_BMS01 65535 "SNA" ;
VAL_ 960 maxBrickVoltageSync_BMS01 65535 "SNA" ;
VAL_ 960 minBrickVoltageSync_BMS01 65535 "SNA" ;
VAL_ 960 SOHCMinBrickLowEst_BMS01 255 "SNA" ;
VAL_ 960 SOHCMaxBrickLowEst_BMS01 255 "SNA" ;
VAL_ 960 gradLimSOC_BMS01 65535 "SNA" ;
VAL_ 960 SOCRecalSlowOp_BMS01 255 "SNA" ;
VAL_ 960 SOHCMinIndex_BMS01 65535 "SNA" ;
VAL_ 960 SOHCMaxIndex_BMS01 65535 "SNA" ;
VAL_ 960 SOHRMinRegen_BMS01 255 "SNA" ;
VAL_ 960 SOHRMinDchg_BMS01 255 "SNA" ;
VAL_ 960 SOHRMeanRegen_BMS01 255 "SNA" ;
VAL_ 960 SOHRMeanDchg_BMS01 255 "SNA" ;
VAL_ 960 SOHRMaxRegen_BMS01 255 "SNA" ;
VAL_ 960 SOHRMaxDchg_BMS01 255 "SNA" ;
VAL_ 960 SOHCMin_BMS01 255 "SNA" ;
VAL_ 960 SOHCMean_BMS01 255 "SNA" ;
VAL_ 960 SOHCMax_BMS01 255 "SNA" ;
VAL_ 960 ppRegenCurrLimitPredShort_BMS01 255 "SNA" ;
VAL_ 960 ppRegenCurrLimitPredLong_BMS01 255 "SNA" ;
VAL_ 960 ppDchgCurrLimitPredShort_BMS01 255 "SNA" ;
VAL_ 960 ppDchgCurrLimitPredLong_BMS01 255 "SNA" ;
VAL_ 960 ppPolarizationV_BMS01 65535 "SNA" ;
VAL_ 960 SOCRecalMinOCVEst_BMS01 65535 "SNA" ;
VAL_ 960 SOCRecalMaxOCVEst_BMS01 65535 "SNA" ;
VAL_ 960 SOCRecalMinSOCUpp_BMS01 255 "SNA" ;
VAL_ 960 SOCRecalMinSOCLow_BMS01 255 "SNA" ;
VAL_ 960 SOCRecalMinSOC_BMS01 255 "SNA" ;
VAL_ 960 SOCRecalMaxSOCUpp_BMS01 255 "SNA" ;
VAL_ 960 SOCRecalMaxSOCLow_BMS01 255 "SNA" ;
VAL_ 960 SOCRecalMaxSOC_BMS01 255 "SNA" ;
VAL_ 960 ppNewtonStepsRegen_BMS01 7 "SNA" ;
VAL_ 960 ppNewtonStepsDchg_BMS01 7 "SNA" ;
VAL_ 960 ppNewtonRegenVRes_BMS01 255 "SNA" ;
VAL_ 960 ppNewtonDchgVRes_BMS01 255 "SNA" ;
VAL_ 960 ppMinModelAlphaTarget_BMS01 255 "SNA" ;
VAL_ 960 ppMaxModelAlphaTarget_BMS01 255 "SNA" ;
VAL_ 960 ppLearningTauRegen_BMS01 65535 "SNA" ;
VAL_ 960 ppLearningCriterionDyn_BMS01 255 "SNA" ;
VAL_ 960 ppLearningCriterionAbs_BMS01 255 "SNA" ;
VAL_ 960 ppLearningCriterionJoin_BMS01 255 "SNA" ;
VAL_ 960 currentRedundant_BMS01 65535 "SNA" ;
VAL_ 960 currentModule3_BMS01 65535 "SNA" ;
VAL_ 960 currentModule2_BMS01 65535 "SNA" ;
VAL_ 960 currentModule1_BMS01 65535 "SNA" ;
VAL_ 960 ppMeanDchgIntRes_BMS01 65535 "SNA" ;
VAL_ 960 ppMinModelLowpassV_BMS01 65535 "SNA" ;
VAL_ 960 ppMaxModelVoltageIndex_BMS01 65535 "SNA" ;
VAL_ 960 ppMaxModelLowpassV_BMS01 65535 "SNA" ;
VAL_ 960 ppLearningTauDischarge_BMS01 65535 "SNA" ;
VAL_ 960 ppMaxRegenAlpha_BMS01 255 "SNA" ;
VAL_ 960 ppMaxModelledV_BMS01 65535 "SNA" ;
VAL_ 960 ppMinDchgAlpha_BMS01 255 "SNA" ;
VAL_ 960 ppMinModelledV_BMS01 65535 "SNA" ;
VAL_ 960 debugSlowMpex2_BMS01 0 "S00" 1 "S01" 2 "S02" 3 "S03" 4 "S04" 5 "S05" 6 "S06" 7 "S07" 8 "S08" 9 "S09" 10 "S10" 11 "S11" 12 "S12" 13 "S13" 14 "S14" 15 "S15" 16 "S16" 17 "S17" 18 "S18" 19 "S19" 20 "S20" 21 "S21" 22 "S22" 23 "S23" 24 "S24" 25 "S25" ;
VAL_ 960 ppRegenCurrPredShort_BMS01 65535 "SNA" ;
VAL_ 960 ppDischgCurrPredLong_BMS01 65535 "SNA" ;
VAL_ 960 ppDischgCurrPredShort_BMS01 65535 "SNA" ;
VAL_ 960 ppRegenCurrPredLong_BMS01 65535 "SNA" ;
VAL_ 960 ppRegenVPredShort_BMS01 65535 "SNA" ;
VAL_ 960 ppDischgVPredShort_BMS01 65535 "SNA" ;
VAL_ 960 ppRegenVPredLong_BMS01 65535 "SNA" ;
VAL_ 960 ppDischgVPredLong_BMS01 65535 "SNA" ;
VAL_ 960 SOHDeltaSOCCoulomb_BMS01 65535 "SNA" ;
VAL_ 960 SOHAbsDeltaSOCCoulomb_BMS01 65535 "SNA" ;
VAL_ 960 SOHLastOCVRecalMinSOC_BMS01 255 "SNA" ;
VAL_ 960 SOHbalancingTimeMinSOH_BMS01 255 "SNA" ;
VAL_ 1792 chargerDCOutV_BMS01 65535 "SNA" ;
VAL_ 1792 chargerProximity_BMS01 255 "SNA" ;
VAL_ 1792 chargerPilot_BMS01 255 "SNA" ;
VAL_ 1792 chargerCurrAvail_BMS01 255 "SNA" ;
VAL_ 1792 chargerCtrOn_BMS01 1 "TRUE" 0 "FALSE" ;
VAL_ 1792 chargerOn_BMS01 1 "TRUE" 0 "FALSE" ;
VAL_ 1792 debugFastMpex2_BMS01 0 "F00" 1 "F01" 2 "F02" 3 "F03" 4 "F04" 5 "F05" 6 "F06" 7 "F07" 8 "F08" 9 "F09" 10 "F10" 11 "F11" 12 "F12" 13 "F13" 14 "F14" 15 "F15" ;
VAL_ 1792 posPackDbg_BMS01 65535 "SNA" ;
VAL_ 1792 negPackDbg_BMS01 65535 "SNA" ;
VAL_ 1792 packVoltageHVMeas_BMS01 65535 "SNA" ;
VAL_ 769 essMstrPrechargeState00_BMS 15 "STRING_NOT_EXISTING" 5 "STRING_WILL_OPEN_SOON" 4 "STRING_ON" 3 "STRING_PAUSED" 2 "STRING_CLOSING" 1 "STRING_INDEFINED" 0 "STRING_OFF" ;
VAL_ 769 essMstrPrechargeState01_BMS 15 "STRING_NOT_EXISTING" 5 "STRING_WILL_OPEN_SOON" 4 "STRING_ON" 3 "STRING_PAUSED" 2 "STRING_CLOSING" 1 "STRING_INDEFINED" 0 "STRING_OFF" ;
VAL_ 769 essMstrPrechargeState02_BMS 15 "STRING_NOT_EXISTING" 5 "STRING_WILL_OPEN_SOON" 4 "STRING_ON" 3 "STRING_PAUSED" 2 "STRING_CLOSING" 1 "STRING_INDEFINED" 0 "STRING_OFF" ;
VAL_ 769 essMstrPrechargeState03_BMS 15 "STRING_NOT_EXISTING" 5 "STRING_WILL_OPEN_SOON" 4 "STRING_ON" 3 "STRING_PAUSED" 2 "STRING_CLOSING" 1 "STRING_INDEFINED" 0 "STRING_OFF" ;
VAL_ 769 essMstrPrechargeState04_BMS 15 "STRING_NOT_EXISTING" 5 "STRING_WILL_OPEN_SOON" 4 "STRING_ON" 3 "STRING_PAUSED" 2 "STRING_CLOSING" 1 "STRING_INDEFINED" 0 "STRING_OFF" ;
VAL_ 769 essMstrPrechargeState05_BMS 15 "STRING_NOT_EXISTING" 5 "STRING_WILL_OPEN_SOON" 4 "STRING_ON" 3 "STRING_PAUSED" 2 "STRING_CLOSING" 1 "STRING_INDEFINED" 0 "STRING_OFF" ;
VAL_ 769 essMstrPrechargeState06_BMS 15 "STRING_NOT_EXISTING" 5 "STRING_WILL_OPEN_SOON" 4 "STRING_ON" 3 "STRING_PAUSED" 2 "STRING_CLOSING" 1 "STRING_INDEFINED" 0 "STRING_OFF" ;
VAL_ 769 essMstrPrechargeState07_BMS 15 "STRING_NOT_EXISTING" 5 "STRING_WILL_OPEN_SOON" 4 "STRING_ON" 3 "STRING_PAUSED" 2 "STRING_CLOSING" 1 "STRING_INDEFINED" 0 "STRING_OFF" ;
VAL_ 769 essMstrPrechargeState08_BMS 15 "STRING_NOT_EXISTING" 5 "STRING_WILL_OPEN_SOON" 4 "STRING_ON" 3 "STRING_PAUSED" 2 "STRING_CLOSING" 1 "STRING_INDEFINED" 0 "STRING_OFF" ;
VAL_ 769 essMstrPrechargeState09_BMS 15 "STRING_NOT_EXISTING" 5 "STRING_WILL_OPEN_SOON" 4 "STRING_ON" 3 "STRING_PAUSED" 2 "STRING_CLOSING" 1 "STRING_INDEFINED" 0 "STRING_OFF" ;
VAL_ 769 essMstrPrechargeState10_BMS 15 "STRING_NOT_EXISTING" 5 "STRING_WILL_OPEN_SOON" 4 "STRING_ON" 3 "STRING_PAUSED" 2 "STRING_CLOSING" 1 "STRING_INDEFINED" 0 "STRING_OFF" ;
VAL_ 769 essMstrPrechargeState11_BMS 15 "STRING_NOT_EXISTING" 5 "STRING_WILL_OPEN_SOON" 4 "STRING_ON" 3 "STRING_PAUSED" 2 "STRING_CLOSING" 1 "STRING_INDEFINED" 0 "STRING_OFF" ;
VAL_ 769 essMstrPrechargeState12_BMS 15 "STRING_NOT_EXISTING" 5 "STRING_WILL_OPEN_SOON" 4 "STRING_ON" 3 "STRING_PAUSED" 2 "STRING_CLOSING" 1 "STRING_INDEFINED" 0 "STRING_OFF" ;
VAL_ 769 essMstrPrechargeState13_BMS 15 "STRING_NOT_EXISTING" 5 "STRING_WILL_OPEN_SOON" 4 "STRING_ON" 3 "STRING_PAUSED" 2 "STRING_CLOSING" 1 "STRING_INDEFINED" 0 "STRING_OFF" ;
VAL_ 769 essMstrPrechargeState14_BMS 15 "STRING_NOT_EXISTING" 5 "STRING_WILL_OPEN_SOON" 4 "STRING_ON" 3 "STRING_PAUSED" 2 "STRING_CLOSING" 1 "STRING_INDEFINED" 0 "STRING_OFF" ;
VAL_ 769 essMstrPrechargeState15_BMS 15 "STRING_NOT_EXISTING" 5 "STRING_WILL_OPEN_SOON" 4 "STRING_ON" 3 "STRING_PAUSED" 2 "STRING_CLOSING" 1 "STRING_INDEFINED" 0 "STRING_OFF" ;
VAL_ 1856 SOHRecentChange_BMS01 255 "SNA" ;
VAL_ 1856 SOHConvergenceIndicator_BMS01 255 "SNA" ;
VAL_ 1856 SOHConvergenceCounter_BMS01 255 "SNA" ;
VAL_ 1856 SOHMinFiltered_BMS01 255 "SNA" ;
VAL_ 1856 medianModuleTempGrp2_BMS01 255 "SNA" ;
VAL_ 1856 medianModuleTempGrp1_BMS01 255 "SNA" ;
VAL_ 1856 coolantWarningtAlert_BMS01 3 "SNA" 2 "COOLANT_FLOOD_WARNING" 0 "COOLANT_NOWARNING" 1 "COOLANT_MOISTURE_WARNING" ;
VAL_ 1856 coolantFaultAlert_BMS01 3 "SNA" 2 "COOLANT_FLOOD_FAULT" 0 "COOLANT_NOFAULT" 1 "COOLANT_MOISTURE_FAULT" ;
VAL_ 1856 hvilShutdownStrategy_BMS01 4 "Strategy_4" 3 "Strategy_3" 2 "Strategy_2" 1 "Strategy_1" 0 "Strategy_0" ;
VAL_ 1856 J1939_nmState 3 "J1939_NM_INACTIVE" 2 "J1939_NM_ACTIVE" 1 "J1939_NM_STARTUP" 0 "J1939_NM_INIT" ;
VAL_ 1856 PrechargeXCapMin_BMS01 65535 "SNA" ;
VAL_ 1856 LimpHomeTimeOut_BMS01 65535 "SNA" ;
VAL_ 1856 hvWithstandTests_BMS01 255 "SNA" ;
VAL_ 1856 aux3prechargeState_BMS01 15 "CTR_PRCHG_NEG_OPEN" 13 "CTR_PRCHG_POS_WELD_CHECK" 12 "CTR_PRCHG_PRE_COND_CHECK" 11 "CTR_PRCHG_NEG2_WELD_CHECK" 10 "CTR_PRCHG_CLOSEMID" 9 "CTR_PRCHG_CLOSEAUX" 8 "CTR_PRCHG_FAILED" 7 "CTR_PRCHG_COMPLETE" 6 "CTR_PRCHG_CLOSE_POS" 5 "CTR_PRCHG_MONITOR_VOLTAGE" 4 "CTR_PRCHG_CLOSE_NEG" 3 "CTR_PRCHG_NEG_WELD_CHECK" 2 "CTR_PRCHG_CLOSE_RELAY" 1 "CTR_PRCHG_WELD_CHECK" 0 "CTR_PRCHG_OFF" ;
VAL_ 1856 aux2prechargeState_BMS01 15 "CTR_PRCHG_NEG_OPEN" 13 "CTR_PRCHG_POS_WELD_CHECK" 12 "CTR_PRCHG_PRE_COND_CHECK" 11 "CTR_PRCHG_NEG2_WELD_CHECK" 10 "CTR_PRCHG_CLOSEMID" 9 "CTR_PRCHG_CLOSEAUX" 8 "CTR_PRCHG_FAILED" 7 "CTR_PRCHG_COMPLETE" 6 "CTR_PRCHG_CLOSE_POS" 5 "CTR_PRCHG_MONITOR_VOLTAGE" 4 "CTR_PRCHG_CLOSE_NEG" 3 "CTR_PRCHG_NEG_WELD_CHECK" 2 "CTR_PRCHG_CLOSE_RELAY" 1 "CTR_PRCHG_WELD_CHECK" 0 "CTR_PRCHG_OFF" ;
VAL_ 1856 aux1prechargeState_BMS01 15 "CTR_PRCHG_NEG_OPEN" 13 "CTR_PRCHG_POS_WELD_CHECK" 12 "CTR_PRCHG_PRE_COND_CHECK" 11 "CTR_PRCHG_NEG2_WELD_CHECK" 10 "CTR_PRCHG_CLOSEMID" 9 "CTR_PRCHG_CLOSEAUX" 8 "CTR_PRCHG_FAILED" 7 "CTR_PRCHG_COMPLETE" 6 "CTR_PRCHG_CLOSE_POS" 5 "CTR_PRCHG_MONITOR_VOLTAGE" 4 "CTR_PRCHG_CLOSE_NEG" 3 "CTR_PRCHG_NEG_WELD_CHECK" 2 "CTR_PRCHG_CLOSE_RELAY" 1 "CTR_PRCHG_WELD_CHECK" 0 "CTR_PRCHG_OFF" ;
VAL_ 1856 auxLinkVoltage_BMS01 65535 "SNA" ;
VAL_ 1856 rangeRequestIgnoreVehicle 255 "NO_COMMAND" 1 "IGNORE" 0 "DO_NOT_IGNORE" ;
VAL_ 1856 rangeRequestEepromValue 255 "NO_COMMAND" 15 "RANGE_INVALID" 14 "RANGE_MAXIMUM" 13 "RANGE_MODESOH8" 12 "RANGE_MODESOH7" 11 "RANGE_MODESOH6" 10 "RANGE_MODESOH5" 9 "RANGE_MODESOH4" 8 "RANGE_MODESOH3" 7 "RANGE_MODESOH2" 6 "RANGE_MODESOH1" 5 "RANGE_MODE407" 4 "RANGE_MODE405" 3 "RANGE_MODE4175" 2 "RANGE_MODE415" 1 "RANGE_LIMITED" 0 "RANGE_SHIPPING" ;
VAL_ 1856 pressure2_BMS01 255 "SNA" ;
VAL_ 1856 calibration_version_BMS01 255 "SNA" ;
VAL_ 1856 currentLowTimer_BMS01 65535 "SNA" ;
VAL_ 1856 auxCntrrOpenUnderLoadCntr_BMS01 65535 "SNA" ;
VAL_ 1856 rabbitContactorState_BMS01 5 "FAILURE" 4 "CLOSE" 3 "EXT_ISO_TEST" 2 "AUX_CLOSE" 1 "INT_ISO_TEST" 0 "OPEN" ;
VAL_ 1856 analogIsenseSupplyCurr_BMS01 255 "SNA" ;
VAL_ 1856 pumpSpeedReqCoolPrfmc_BMS01 255 "SNA" ;
VAL_ 1856 microsarOs_IdleTask_OsCr0_BMS01 255 "SNA" ;
VAL_ 1856 microsarOs_BswTask_BMS01 255 "SNA" ;
VAL_ 1856 microsarOs_InitTask_BMS01 255 "SNA" ;
VAL_ 1856 microsarOs_ApplTask_1Hz_BMS01 255 "SNA" ;
VAL_ 1856 microsarOs_ApplTask_10Hz_BMS01 255 "SNA" ;
VAL_ 1856 microsarOs_ApplTask_100Hz_BMS01 255 "SNA" ;
VAL_ 1856 microsarOs_ApplLowTask_BMS01 255 "SNA" ;
VAL_ 1856 microsarOs_ApplLateInit_BMS01 255 "SNA" ;
VAL_ 1856 microsarOs_ApplHighTask_BMS01 255 "SNA" ;
VAL_ 1856 microsarOs_ApplEarlyInit_BMS01 255 "SNA" ;
VAL_ 1856 appTaskBSWMaxDuration_BMS01 255 "SNA" ;
VAL_ 1856 appTaskApplHighMaxDuration_BMS01 255 "SNA" ;
VAL_ 1856 appTask1HzMaxDuration_BMS01 255 "SNA" ;
VAL_ 1856 appTask100HzMaxDuration_BMS01 255 "SNA" ;
VAL_ 1856 appTask10HzMaxDuration_BMS01 255 "SNA" ;
VAL_ 1856 appTask100HzDuration_BMS01 255 "SNA" ;
VAL_ 1856 appTask10HzDuration_BMS01 255 "SNA" ;
VAL_ 1856 appTask1HzDuration_BMS01 255 "SNA" ;
VAL_ 1856 appTaskBSWDuration_BMS01 255 "SNA" ;
VAL_ 1856 appTaskApplHighDuration_BMS01 255 "SNA" ;
VAL_ 1856 iumprMaxRatioDTCId_BMS01 0 "SNA" ;
VAL_ 1856 iumprMaxRatio_BMS01 0 "SNA" ;
VAL_ 1856 iumprMinRatioDTCId_BMS01 0 "SNA" ;
VAL_ 1856 iumprMinRatio_BMS01 0 "SNA" ;
VAL_ 1856 fluidLvlCount_BMS01 255 "SNA" ;
VAL_ 1856 fluidLvlSensr2_BMS01 3 "FLUIDLEVEL_ERROR" 2 "FLUIDLEVEL_OIL" 1 "FLUIDLEVEL_AIR" 0 "FLUIDLEVEL_SNA" ;
VAL_ 1856 fluidLvlSensr1_BMS01 3 "FLUIDLEVEL_ERROR" 2 "FLUIDLEVEL_OIL" 1 "FLUIDLEVEL_AIR" 0 "FLUIDLEVEL_SNA" ;
VAL_ 1856 pumpSpeedReqVhcleSpeed_BMS01 255 "SNA" ;
VAL_ 1856 appTaskBSWCpuUsage_BMS01 255 "SNA" ;
VAL_ 1856 appTask200HzCpuUsage_BMS01 255 "SNA" ;
VAL_ 1856 pyroState_BMS01 7 "PYRO_FIRE" 6 "PYRO_DIAG_PASS" 5 "PYRO_DIAG_FAIL" 4 "PYRO_DIAG_LS_ON" 3 "PYRO_DIAG_OPEN" 2 "PYRO_DIAG_HS_ON" 1 "PYRO_DIAG_INIT" 0 "PYRO_INACTIVE" ;
VAL_ 1856 ecuSerialNrChar15_BMS01 90 "'Z'" 89 "'Y'" 88 "'X'" 87 "'W'" 86 "'V'" 85 "'U'" 84 "'T'" 83 "'S'" 82 "'R'" 81 "'Q'" 80 "'P'" 79 "'O'" 78 "'N'" 77 "'M'" 76 "'L'" 75 "'K'" 74 "'J'" 73 "'I'" 72 "'H'" 71 "'G'" 70 "'F'" 69 "'E'" 68 "'D'" 67 "'C'" 66 "'B'" 65 "'A'" 57 "'9'" 56 "'8'" 55 "'7'" 54 "'6'" 53 "'5'" 52 "'4'" 51 "'3'" 50 "'2'" 49 "'1'" 48 "'0'" ;
VAL_ 1856 ecuSerialNrChar14_BMS01 90 "'Z'" 89 "'Y'" 88 "'X'" 87 "'W'" 86 "'V'" 85 "'U'" 84 "'T'" 83 "'S'" 82 "'R'" 81 "'Q'" 80 "'P'" 79 "'O'" 78 "'N'" 77 "'M'" 76 "'L'" 75 "'K'" 74 "'J'" 73 "'I'" 72 "'H'" 71 "'G'" 70 "'F'" 69 "'E'" 68 "'D'" 67 "'C'" 66 "'B'" 65 "'A'" 57 "'9'" 56 "'8'" 55 "'7'" 54 "'6'" 53 "'5'" 52 "'4'" 51 "'3'" 50 "'2'" 49 "'1'" 48 "'0'" ;
VAL_ 1856 ecuSerialNrChar13_BMS01 90 "'Z'" 89 "'Y'" 88 "'X'" 87 "'W'" 86 "'V'" 85 "'U'" 84 "'T'" 83 "'S'" 82 "'R'" 81 "'Q'" 80 "'P'" 79 "'O'" 78 "'N'" 77 "'M'" 76 "'L'" 75 "'K'" 74 "'J'" 73 "'I'" 72 "'H'" 71 "'G'" 70 "'F'" 69 "'E'" 68 "'D'" 67 "'C'" 66 "'B'" 65 "'A'" 57 "'9'" 56 "'8'" 55 "'7'" 54 "'6'" 53 "'5'" 52 "'4'" 51 "'3'" 50 "'2'" 49 "'1'" 48 "'0'" ;
VAL_ 1856 ecuSerialNrChar12_BMS01 90 "'Z'" 89 "'Y'" 88 "'X'" 87 "'W'" 86 "'V'" 85 "'U'" 84 "'T'" 83 "'S'" 82 "'R'" 81 "'Q'" 80 "'P'" 79 "'O'" 78 "'N'" 77 "'M'" 76 "'L'" 75 "'K'" 74 "'J'" 73 "'I'" 72 "'H'" 71 "'G'" 70 "'F'" 69 "'E'" 68 "'D'" 67 "'C'" 66 "'B'" 65 "'A'" 57 "'9'" 56 "'8'" 55 "'7'" 54 "'6'" 53 "'5'" 52 "'4'" 51 "'3'" 50 "'2'" 49 "'1'" 48 "'0'" ;
VAL_ 1856 ecuSerialNrChar11_BMS01 90 "'Z'" 89 "'Y'" 88 "'X'" 87 "'W'" 86 "'V'" 85 "'U'" 84 "'T'" 83 "'S'" 82 "'R'" 81 "'Q'" 80 "'P'" 79 "'O'" 78 "'N'" 77 "'M'" 76 "'L'" 75 "'K'" 74 "'J'" 73 "'I'" 72 "'H'" 71 "'G'" 70 "'F'" 69 "'E'" 68 "'D'" 67 "'C'" 66 "'B'" 65 "'A'" 57 "'9'" 56 "'8'" 55 "'7'" 54 "'6'" 53 "'5'" 52 "'4'" 51 "'3'" 50 "'2'" 49 "'1'" 48 "'0'" ;
VAL_ 1856 ecuSerialNrChar10_BMS01 90 "'Z'" 89 "'Y'" 88 "'X'" 87 "'W'" 86 "'V'" 85 "'U'" 84 "'T'" 83 "'S'" 82 "'R'" 81 "'Q'" 80 "'P'" 79 "'O'" 78 "'N'" 77 "'M'" 76 "'L'" 75 "'K'" 74 "'J'" 73 "'I'" 72 "'H'" 71 "'G'" 70 "'F'" 69 "'E'" 68 "'D'" 67 "'C'" 66 "'B'" 65 "'A'" 57 "'9'" 56 "'8'" 55 "'7'" 54 "'6'" 53 "'5'" 52 "'4'" 51 "'3'" 50 "'2'" 49 "'1'" 48 "'0'" ;
VAL_ 1856 ecuSerialNrChar09_BMS01 90 "'Z'" 89 "'Y'" 88 "'X'" 87 "'W'" 86 "'V'" 85 "'U'" 84 "'T'" 83 "'S'" 82 "'R'" 81 "'Q'" 80 "'P'" 79 "'O'" 78 "'N'" 77 "'M'" 76 "'L'" 75 "'K'" 74 "'J'" 73 "'I'" 72 "'H'" 71 "'G'" 70 "'F'" 69 "'E'" 68 "'D'" 67 "'C'" 66 "'B'" 65 "'A'" 57 "'9'" 56 "'8'" 55 "'7'" 54 "'6'" 53 "'5'" 52 "'4'" 51 "'3'" 50 "'2'" 49 "'1'" 48 "'0'" ;
VAL_ 1856 ecuSerialNrChar08_BMS01 90 "'Z'" 89 "'Y'" 88 "'X'" 87 "'W'" 86 "'V'" 85 "'U'" 84 "'T'" 83 "'S'" 82 "'R'" 81 "'Q'" 80 "'P'" 79 "'O'" 78 "'N'" 77 "'M'" 76 "'L'" 75 "'K'" 74 "'J'" 73 "'I'" 72 "'H'" 71 "'G'" 70 "'F'" 69 "'E'" 68 "'D'" 67 "'C'" 66 "'B'" 65 "'A'" 57 "'9'" 56 "'8'" 55 "'7'" 54 "'6'" 53 "'5'" 52 "'4'" 51 "'3'" 50 "'2'" 49 "'1'" 48 "'0'" ;
VAL_ 1856 ecuSerialNrChar07_BMS01 90 "'Z'" 89 "'Y'" 88 "'X'" 87 "'W'" 86 "'V'" 85 "'U'" 84 "'T'" 83 "'S'" 82 "'R'" 81 "'Q'" 80 "'P'" 79 "'O'" 78 "'N'" 77 "'M'" 76 "'L'" 75 "'K'" 74 "'J'" 73 "'I'" 72 "'H'" 71 "'G'" 70 "'F'" 69 "'E'" 68 "'D'" 67 "'C'" 66 "'B'" 65 "'A'" 57 "'9'" 56 "'8'" 55 "'7'" 54 "'6'" 53 "'5'" 52 "'4'" 51 "'3'" 50 "'2'" 49 "'1'" 48 "'0'" ;
VAL_ 1856 ecuSerialNrChar06_BMS01 90 "'Z'" 89 "'Y'" 88 "'X'" 87 "'W'" 86 "'V'" 85 "'U'" 84 "'T'" 83 "'S'" 82 "'R'" 81 "'Q'" 80 "'P'" 79 "'O'" 78 "'N'" 77 "'M'" 76 "'L'" 75 "'K'" 74 "'J'" 73 "'I'" 72 "'H'" 71 "'G'" 70 "'F'" 69 "'E'" 68 "'D'" 67 "'C'" 66 "'B'" 65 "'A'" 57 "'9'" 56 "'8'" 55 "'7'" 54 "'6'" 53 "'5'" 52 "'4'" 51 "'3'" 50 "'2'" 49 "'1'" 48 "'0'" ;
VAL_ 1856 ecuSerialNrChar05_BMS01 90 "'Z'" 89 "'Y'" 88 "'X'" 87 "'W'" 86 "'V'" 85 "'U'" 84 "'T'" 83 "'S'" 82 "'R'" 81 "'Q'" 80 "'P'" 79 "'O'" 78 "'N'" 77 "'M'" 76 "'L'" 75 "'K'" 74 "'J'" 73 "'I'" 72 "'H'" 71 "'G'" 70 "'F'" 69 "'E'" 68 "'D'" 67 "'C'" 66 "'B'" 65 "'A'" 57 "'9'" 56 "'8'" 55 "'7'" 54 "'6'" 53 "'5'" 52 "'4'" 51 "'3'" 50 "'2'" 49 "'1'" 48 "'0'" ;
VAL_ 1856 analogGPIO1Current_BMS01 255 "SNA" ;
VAL_ 1856 analogGPIO1Volt_BMS01 255 "SNA" ;
VAL_ 1856 analogGPIO2Current_BMS01 255 "SNA" ;
VAL_ 1856 analogGPIO2Volt_BMS01 255 "SNA" ;
VAL_ 1856 pumpSpeedReqLoadValue_BMS01 255 "SNA" ;
VAL_ 1856 ssaRTMonth_BMS01 255 "SNA" ;
VAL_ 1856 ssaRTDay_BMS01 255 "SNA" ;
VAL_ 1856 appTask50HzStackUsage_BMS01 255 "SNA" ;
VAL_ 1856 OBDMILRequested_BMS01 3 "MIL_SNA" 1 "MIL_ON" 0 "MIL_OFF" ;
VAL_ 1856 OBDConfirmedDTCsCount_BMS01 255 "SNA" ;
VAL_ 1856 OBDFirstConfirmedDTC_BMS01 255 "SNA" ;
VAL_ 1856 OBDPermanentDTCCount_BMS01 255 "SNA" ;
VAL_ 1856 OBDFirstPermanentDTC_BMS01 255 "SNA" ;
VAL_ 1856 nmStartupReason_BMS01 15 "NM_STARTUP_INVALID" 7 "NM_STARTUP_TESTERPRESENT" 6 "NM_STARTUP_RQ" 5 "NM_STARTUP_CAN" 4 "NM_STARTUP_THERMALEVENT" 3 "NM_STARTUP_AUXCONTACTORS" 2 "NM_STARTUP_CONTACTORS" 1 "NM_STARTUP_KEY" 0 "NM_STARTUP_NOSTARTUP" ;
VAL_ 1856 contactorType_BMS01 15 "SNA" 1 "GV240_12V" 0 "CTR_TYPE_CALIBRATION (GV240_24V)" ;
VAL_ 1856 activeIsoTestDuration_BMS01 255 "SNA" ;
VAL_ 1856 balancingState_BMS01 6 "BALANCING_OFF_TEMP_SHUTDOWN" 5 "BALANCING_OFF_VOLTAGE_SHUTDOWN" 4 "BALANCING_ON_DCM_EEPROM" 3 "BALANCING_ON_DCM_BRICK" 2 "BALANCING_ON_DCM_PATTERN" 1 "BALANCING_ON_ME_APP" 0 "BALANCING_OFF" ;
VAL_ 1856 chronoStackWrCnt_BMS01 -1 "SNA" ;
VAL_ 1856 wakeReason_BMS01 6 "ECU_WAKEREASON_MCUWDG" 14 "ECU_WAKEREASON_INIT" 15 "ECU_WAKEREASON_UNKNOWN" 5 "ECU_WAKEREASON_AUTO" 4 "ECU_WAKEREASON_POR" 3 "ECU_WAKEREASON_CLOCK" 2 "ECU_WAKEREASON_PRESSURE" 1 "ECU_WAKEREASON_CAN" 0 "ECU_WAKEREASON_KEY" ;
VAL_ 1856 coolantOutletTemperature_BMS01 255 "SNA" ;
VAL_ 1856 coolantInletTemperature_BMS01 255 "SNA" ;
VAL_ 1856 variantCodingCount_BMS01 65535 "SNA" ;
VAL_ 1856 SWVersionCusApp_BMS01 -1 "SNA" ;
VAL_ 1856 contactorOpenRequest_BMS01 15 "CTR_OPEN_INVALID" 1 "CTR_OPEN_IMMEDIATE" 0 "CTR_OPEN_FAST " ;
VAL_ 1856 maxBrickVoltageChargeLimit_BMS01 65535 "SNA" ;
VAL_ 1856 desiccantTimer_BMS01 -1 "SNA" ;
VAL_ 1856 batSwitchOpenReason_BMS01 65535 "SNA" ;
VAL_ 1856 balancingTime_BMS01 65535 "SNA" ;
VAL_ 1856 ecuSerialNrChar01_BMS01 90 "'Z'" 89 "'Y'" 88 "'X'" 87 "'W'" 86 "'V'" 85 "'U'" 84 "'T'" 83 "'S'" 82 "'R'" 81 "'Q'" 80 "'P'" 79 "'O'" 78 "'N'" 77 "'M'" 76 "'L'" 75 "'K'" 74 "'J'" 73 "'I'" 72 "'H'" 71 "'G'" 70 "'F'" 69 "'E'" 68 "'D'" 67 "'C'" 66 "'B'" 65 "'A'" 57 "'9'" 56 "'8'" 55 "'7'" 54 "'6'" 53 "'5'" 52 "'4'" 51 "'3'" 50 "'2'" 49 "'1'" 48 "'0'" ;
VAL_ 1856 ecuSerialNrChar02_BMS01 90 "'Z'" 89 "'Y'" 88 "'X'" 87 "'W'" 86 "'V'" 85 "'U'" 84 "'T'" 83 "'S'" 82 "'R'" 81 "'Q'" 80 "'P'" 79 "'O'" 78 "'N'" 77 "'M'" 76 "'L'" 75 "'K'" 74 "'J'" 73 "'I'" 72 "'H'" 71 "'G'" 70 "'F'" 69 "'E'" 68 "'D'" 67 "'C'" 66 "'B'" 65 "'A'" 57 "'9'" 56 "'8'" 55 "'7'" 54 "'6'" 53 "'5'" 52 "'4'" 51 "'3'" 50 "'2'" 49 "'1'" 48 "'0'" ;
VAL_ 1856 ecuSerialNrChar03_BMS01 90 "'Z'" 89 "'Y'" 88 "'X'" 87 "'W'" 86 "'V'" 85 "'U'" 84 "'T'" 83 "'S'" 82 "'R'" 81 "'Q'" 80 "'P'" 79 "'O'" 78 "'N'" 77 "'M'" 76 "'L'" 75 "'K'" 74 "'J'" 73 "'I'" 72 "'H'" 71 "'G'" 70 "'F'" 69 "'E'" 68 "'D'" 67 "'C'" 66 "'B'" 65 "'A'" 57 "'9'" 56 "'8'" 55 "'7'" 54 "'6'" 53 "'5'" 52 "'4'" 51 "'3'" 50 "'2'" 49 "'1'" 48 "'0'" ;
VAL_ 1856 ecuSerialNrChar04_BMS01 90 "'Z'" 89 "'Y'" 88 "'X'" 87 "'W'" 86 "'V'" 85 "'U'" 84 "'T'" 83 "'S'" 82 "'R'" 81 "'Q'" 80 "'P'" 79 "'O'" 78 "'N'" 77 "'M'" 76 "'L'" 75 "'K'" 74 "'J'" 73 "'I'" 72 "'H'" 71 "'G'" 70 "'F'" 69 "'E'" 68 "'D'" 67 "'C'" 66 "'B'" 65 "'A'" 57 "'9'" 56 "'8'" 55 "'7'" 54 "'6'" 53 "'5'" 52 "'4'" 51 "'3'" 50 "'2'" 49 "'1'" 48 "'0'" ;
VAL_ 1856 ecuSerialNrChar16_BMS01 90 "'Z'" 89 "'Y'" 88 "'X'" 87 "'W'" 86 "'V'" 85 "'U'" 84 "'T'" 83 "'S'" 82 "'R'" 81 "'Q'" 80 "'P'" 79 "'O'" 78 "'N'" 77 "'M'" 76 "'L'" 75 "'K'" 74 "'J'" 73 "'I'" 72 "'H'" 71 "'G'" 70 "'F'" 69 "'E'" 68 "'D'" 67 "'C'" 66 "'B'" 65 "'A'" 57 "'9'" 56 "'8'" 55 "'7'" 54 "'6'" 53 "'5'" 52 "'4'" 51 "'3'" 50 "'2'" 49 "'1'" 48 "'0'" ;
VAL_ 1856 ecuSerialNrChar17_BMS01 90 "'Z'" 89 "'Y'" 88 "'X'" 87 "'W'" 86 "'V'" 85 "'U'" 84 "'T'" 83 "'S'" 82 "'R'" 81 "'Q'" 80 "'P'" 79 "'O'" 78 "'N'" 77 "'M'" 76 "'L'" 75 "'K'" 74 "'J'" 73 "'I'" 72 "'H'" 71 "'G'" 70 "'F'" 69 "'E'" 68 "'D'" 67 "'C'" 66 "'B'" 65 "'A'" 57 "'9'" 56 "'8'" 55 "'7'" 54 "'6'" 53 "'5'" 52 "'4'" 51 "'3'" 50 "'2'" 49 "'1'" 48 "'0'" ;
VAL_ 1856 ecuSerialNrChar18_BMS01 90 "'Z'" 89 "'Y'" 88 "'X'" 87 "'W'" 86 "'V'" 85 "'U'" 84 "'T'" 83 "'S'" 82 "'R'" 81 "'Q'" 80 "'P'" 79 "'O'" 78 "'N'" 77 "'M'" 76 "'L'" 75 "'K'" 74 "'J'" 73 "'I'" 72 "'H'" 71 "'G'" 70 "'F'" 69 "'E'" 68 "'D'" 67 "'C'" 66 "'B'" 65 "'A'" 57 "'9'" 56 "'8'" 55 "'7'" 54 "'6'" 53 "'5'" 52 "'4'" 51 "'3'" 50 "'2'" 49 "'1'" 48 "'0'" ;
VAL_ 1856 ecuSerialNrChar19_BMS01 90 "'Z'" 89 "'Y'" 88 "'X'" 87 "'W'" 86 "'V'" 85 "'U'" 84 "'T'" 83 "'S'" 82 "'R'" 81 "'Q'" 80 "'P'" 79 "'O'" 78 "'N'" 77 "'M'" 76 "'L'" 75 "'K'" 74 "'J'" 73 "'I'" 72 "'H'" 71 "'G'" 70 "'F'" 69 "'E'" 68 "'D'" 67 "'C'" 66 "'B'" 65 "'A'" 57 "'9'" 56 "'8'" 55 "'7'" 54 "'6'" 53 "'5'" 52 "'4'" 51 "'3'" 50 "'2'" 49 "'1'" 48 "'0'" ;
VAL_ 1856 maxModuleTemperature_BMS01 255 "SNA" ;
VAL_ 1856 meanModuleTemperature_BMS01 255 "SNA" ;
VAL_ 1856 minModuleTemperature_BMS01 255 "SNA" ;
VAL_ 1856 nmOperationalMode_BMS01 2 "NM_BUSSLEEP_MODE" 1 "NM_PREPAREBUSSLEEP_MODE" 0 "NM_NETWORK_MODE" ;
VAL_ 1856 nmNetworkMode_BMS01 2 "NM_MODE_READY_SLEEP" 1 "NM_MODE_NORMAL_OPERATION" 0 "NM_MODE_REPEAT_MESSAGE" ;
VAL_ 1856 nmNetworkState_BMS01 1 "NM_STATE_REQUESTED" 0 "NM_STATE_RELEASED" ;
VAL_ 1856 ecuState_BMS01 4 "ECU_SLEEPING" 3 "ECU_GOING_TO_SLEEP" 2 "ECU_AWAKE_CAN_ACTIVE" 1 "ECU_AWAKE_CAN_INACTIVE" 0 "ECU_INIT" ;
VAL_ 1856 SPIRxTxDiag_BMS01 3 "SPIRXTX_SLAVEREQUESTPACKAGE" 2 "SPIRXTX_CRC" 1 "SPIRXTX_WRONG_PACKETINDEX" 0 "SPIRXTX_ALL_OK" ;
VAL_ 1856 minSOC_BMS01 65535 "SNA" ;
VAL_ 1856 maxSOC_BMS01 65535 "SNA" ;
VAL_ 1856 appTaskMaxCpuUsage_BMS01 255 "SNA" ;
VAL_ 1856 appTaskCpuUsage_BMS01 255 "SNA" ;
VAL_ 1856 appTask50HzCpuUsage_BMS01 255 "SNA" ;
VAL_ 1856 appTask10HzStackUsage_BMS01 255 "SNA" ;
VAL_ 1856 appTask100HzCpuUsage_BMS01 255 "SNA" ;
VAL_ 1856 appTask10HzCpuUsage_BMS01 255 "SNA" ;
VAL_ 1856 appTask1HzCpuUsage_BMS01 255 "SNA" ;
VAL_ 1856 pumpSpeedReq_BMS01 255 "SNA" ;
VAL_ 1856 regenCurrPredBrickVOffset_BMS01 255 "SNA" ;
VAL_ 1856 dischgCurrPredBrickVOffset_BMS01 255 "SNA" ;
VAL_ 1856 PCANBusOffState_BMS01 3 "SNA" 2 "CAN_BUSOFF_PHASE2" 1 "CAN_BUSOFF_PHASE1" 0 "CAN_BUSOFF_NORMAL" ;
VAL_ 1856 SCANBusOffState_BMS01 3 "SNA" 2 "CAN_BUSOFF_PHASE2" 1 "CAN_BUSOFF_PHASE1" 0 "CAN_BUSOFF_NORMAL" ;
VAL_ 1856 PTCANBusOffState_BMS01 3 "SNA" 2 "CAN_BUSOFF_PHASE2" 1 "CAN_BUSOFF_PHASE1" 0 "CAN_BUSOFF_NORMAL" ;
VAL_ 1856 customerModelVsCellType_BMS01 0 "L" 1 "P" ;
VAL_ 1856 balancingVoltageTarget_BMS01 255 "VOLTAGEBASED_BALANCING_INACTIVE" ;
VAL_ 1856 analogAddr5_BMS01 255 "SNA" ;
VAL_ 1856 analogAddr0_BMS01 255 "SNA" ;
VAL_ 1856 analogAddr4_BMS01 255 "SNA" ;
VAL_ 1856 analogAddr3_BMS01 255 "SNA" ;
VAL_ 1856 analogAddr2_BMS01 255 "SNA" ;
VAL_ 1856 analogAddr1_BMS01 255 "SNA" ;
VAL_ 1856 debugSlowMpex1_BMS01 43 "S43" 42 "S42" 41 "S41" 40 "S40" 39 "S39" 38 "S38" 37 "S37" 36 "S36" 0 "S00" 1 "S01" 2 "S02" 3 "S03" 4 "S04" 5 "S05" 6 "S06" 7 "S07" 8 "S08" 9 "S09" 10 "S10" 11 "S11" 12 "S12" 13 "S13" 14 "S14" 15 "S15" 16 "S16" 17 "S17" 18 "S18" 19 "S19" 20 "S20" 21 "S21" 22 "S22" 23 "S23" 24 "S24" 25 "S25" 26 "S26" 27 "S27" 28 "S28" 29 "S29" 30 "S30" 31 "S31" 32 "S32" 33 "S33" 34 "S34" 35 "S35" ;
VAL_ 1856 analog3V3DSupply_BMS01 255 "SNA" ;
VAL_ 1856 pressure_BMS01 255 "SNA" ;
VAL_ 1856 analog3P3VA_BMS01 255 "SNA" ;
VAL_ 1856 analog5VA_BMS01 255 "SNA" ;
VAL_ 1856 analog5VD_BMS01 255 "SNA" ;
VAL_ 1856 analog5VSensorSupply_BMS01 255 "SNA" ;
VAL_ 1856 analog6V5_BMS01 255 "SNA" ;
VAL_ 1856 isolationResistanceIntern_BMS01 65535 "SNA" ;
VAL_ 1856 isolationResistanceExtern_BMS01 65535 "SNA" ;
VAL_ 1856 linkVoltage_BMS01 65535 "SNA" ;
VAL_ 1856 eepromWriteCyclesBasics_BMS01 65535 "SNA" ;
VAL_ 1856 eepromBlockIndex_BMS01 255 "SNA" ;
VAL_ 1856 regenCurrentOpLimit_BMS01 65535 "SNA" ;
VAL_ 1856 regenCurrentErrorLimit_BMS01 65535 "SNA" ;
VAL_ 1856 lifetime_BMS01 -1 "SNA" ;
VAL_ 1856 eepromReadTime_BMS01 255 "SNA" ;
VAL_ 1856 pumpSpeedReqMaxT_BMS01 65535 "SNA" ;
VAL_ 1856 pumpSpeedReqDeltaT_BMS01 65535 "SNA" ;
VAL_ 1856 packVoltageCMB_BMS01 65535 "SNA" ;
VAL_ 1856 ctrOffTime_BMS01 65535 "SNA" ;
VAL_ 1856 sleepTime_BMS01 65535 "SNA" ;
VAL_ 1856 SPIRxTxTimeAllPckts_BMS01 255 "SNA" ;
VAL_ 1856 isolationTestState_BMS01 3 "ISOLATION_DISABLED" 2 "ISOLATION_TEST_NEG" 1 "ISOLATION_TEST_POS" 0 "ISOLATION_OFF" ;
VAL_ 1728 SPIRxTxHeaderMux3Status_BMS01 1 "SPIRXTX_MUX_MISSING" 0 "SPIRXTX_MUX_GOOD" ;
VAL_ 1728 SPIRxTxHeaderMux2Status_BMS01 1 "SPIRXTX_MUX_MISSING" 0 "SPIRXTX_MUX_GOOD" ;
VAL_ 1728 SPIRxTxHeaderMux1Status_BMS01 1 "SPIRXTX_MUX_MISSING" 0 "SPIRXTX_MUX_GOOD" ;
VAL_ 1728 SPIRxTxHeaderMux0Status_BMS01 1 "SPIRXTX_MUX_MISSING" 0 "SPIRXTX_MUX_GOOD" ;
VAL_ 1728 activeIsoState_BMS01 4 "ISOACTV_COMPLETE" 3 "ISOACTV_TIMEOUT" 2 "ISOACTV_PENDING" 1 "ISOACTV_INIT" 0 "ISOACTV_OFF" ;
VAL_ 1728 activeIsoNegLink_BMS01 65535 "SNA" ;
VAL_ 1728 activeIsoPosLink_BMS01 65535 "SNA" ;
VAL_ 1728 activeIsoPosBuffer_BMS01 65535 "SNA" ;
VAL_ 1728 activeIsoNegBuffer_BMS01 65535 "SNA" ;
VAL_ 1728 activeIsoResRaw_BMS01 65535 "SNA" ;
VAL_ 1728 activeIsoResFilter_BMS01 65535 "SNA" ;
VAL_ 1728 contactorStateAux_BMS01 4 "CTR_INVALID" 3 "CTR_STRING_OPENING" 2 "CTR_STRING_ON" 1 "CTR_STRING_PRECHARGE" 0 "CTR_STRING_OFF" ;
VAL_ 1728 batSwitchOpenReqEssMstr_BMS01 3 "INVALID" 2 "IMMEDIATE_OPEN" 1 "FAST_OPEN" 0 "DO_NOT_OPEN" ;
VAL_ 1728 packShutdownTarget_BMS01 3 "BMS_INVALID" 1 "BMS_STRING_FAULT" 0 "BMS_STANDBY" ;
VAL_ 1728 weldedState_BMS01 3 "CTR_NEG1_WELDED" 2 "CTR_POS1_WELDED" 0 "CTR_NOTWELDED" 1 "CTR_BOTH_WELDED" ;
VAL_ 1728 contactorStateRq_BMS01 4 "CTR_INVALID" 3 "CTR_STRING_OPENING" 2 "CTR_STRING_ON" 1 "CTR_STRING_PRECHARGE" 0 "CTR_STRING_OFF" ;
VAL_ 1728 strMstrStrPrechgState_BMS01 7 "NOT_A_STRING_MASTER" 6 "STRING_PRCHG_NDEF2" 5 "STRING_PRCHG_NDEF1" 4 "STRING_PRCHG_FAULT" 3 "STRING_PRCHG_ON" 2 "STRING_PRCHG_ACTV" 1 "STRING_PRCHG_INIT" 0 "STRING_PRCHG_OFF" ;
VAL_ 1728 packShutdwnTmrQual_BMS01 0 "SHUTDOWN_ACTIVE" 1 "SHUTDOWN_INACTIVE" ;
VAL_ 1728 packStateRequest_BMS01 7 "STATE_INVALID" 6 "STATE_SYSTEM_FAULT" 5 "STATE_STRING_FAULT" 4 "STATE_LIMPHOME" 3 "STATE_ACCESSORY" 2 "STATE_CHARGE" 1 "STATE_DRIVE" 0 "STATE_STANDBY" ;
VAL_ 1728 packState_BMS01 15 "STATE_INVALID" 6 "STATE_ESS_FAULT" 5 "STATE_STRING_FAULT" 4 "STATE_LIMPHOME" 3 "STATE_ACCESSORY" 2 "STATE_CHARGE" 1 "STATE_DRIVE" 0 "STATE_STANDBY" ;
VAL_ 1728 SPIRxTxTimer_BMS01 255 "SNA" ;
VAL_ 1728 moduleTMinMaxMeanQual_BMS01 1 "QUAL_ERROR" 0 "QUAL_VALID" ;
VAL_ 1728 currentQual_BMS01 1 "QUAL_ERROR" 0 "QUAL_VALID" ;
VAL_ 1728 brickVMinMaxMeanQual_BMS01 1 "QUAL_ERROR" 0 "QUAL_VALID" ;
VAL_ 1728 debugFastMpex1_BMS01 0 "F00" 1 "F01" 2 "F02" 3 "F03" 4 "F04" 5 "F05" 6 "F06" 7 "F07" 8 "F08" 9 "F09" 10 "F10" 11 "F11" 12 "F12" 13 "F13" 14 "F14" 15 "F15" ;
VAL_ 1728 itemState_BMS01 3 "ITEM_INVALID" 2 "ITEM_EMERGENCY" 1 "ITEM_OFF" 0 "ITEM_ON" ;
VAL_ 1728 posLink_BMS01 255 "SNA" ;
VAL_ 1728 posPack_BMS01 255 "SNA" ;
VAL_ 1728 prechargeState_BMS01 14 "CTR_PRCHG_WAIT_CY_MATCH" 15 "CTR_PRCHG_NEG_OPEN" 13 "CTR_PRCHG_POS_WELD_CHECK" 12 "CTR_PRCHG_PRE_COND_CHECK" 11 "CTR_PRCHG_NEG2_WELD_CHECK" 10 "CTR_PRCHG_CLOSEMID" 9 "CTR_PRCHG_CLOSEAUX" 8 "CTR_PRCHG_FAILED" 7 "CTR_PRCHG_COMPLETE" 6 "CTR_PRCHG_CLOSE_POS" 5 "CTR_PRCHG_MONITOR_VOLTAGE" 4 "CTR_PRCHG_CLOSE_NEG" 3 "CTR_PRCHG_NEG_WELD_CHECK" 2 "CTR_PRCHG_CLOSE_RELAY" 1 "CTR_PRCHG_WELD_CHECK" 0 "CTR_PRCHG_OFF" ;
VAL_ 1728 contactorState_BMS01 4 "CTR_INVALID" 3 "CTR_STRING_OPENING" 2 "CTR_STRING_ON" 1 "CTR_STRING_PRECHARGE" 0 "CTR_STRING_OFF" ;
VAL_ 1536 DEMEventMultiplexor_BMS01 319 "DEM319_HV_DISABLE_DURING_S" 318 "DEM318_HV_ENABLE_IMPLAUSIB" 317 "DEM317_STRING_SUSPECT_OPEN" 316 "DEM316_UNEXPCTD_BMS_ON_CAN" 315 "DEM315_HV_WITHSTAND_TESTS_" 314 "DEM314_OBC_PILOT_ERROR" 313 "DEM313_OBC_PILOT_HIGH" 312 "DEM312_OBC_PROXIMITY_ERROR" 311 "DEM311_CTRS_END_OF_LIFE_WA" 310 "DEM310_BMSMIA_STRNGMSTR_AL" 309 "DEM309_VOLTAGE_BRICKOV_WAR" 308 "DEM308_PRESSURE_FLT" 307 "DEM307_PRESSURE_MIA" 306 "DEM306_SW_VERSION_MISMATCH" 305 "DEM305_MODULET_OVERTEMP_WA" 304 "DEM304_PCHG_OPENCIRCUIT_IN" 303 "DEM303_MODULET_UNDERTEMP_W" 302 "DEM302_MODULET_UT" 301 "DEM301_FUSI_LOCK" 300 "DEM300_DEBUG_SM_DISABLED" 299 "DEM299_5V_SENSOR_SUPPLY_OU" 298 "DEM298_IMPL_DRIVE_REQUEST" 297 "DEM297_PCHG2_OPENCIRCUIT" 296 "DEM296_CTRSAUX_IMPLAUSIBLE" 295 "DEM295_CTRSAUX_LINKV_UNSAF" 294 "DEM294_CANRX_PT_EMERGENCY" 293 "DEM293_SBC_LDT_IMPLAUSIBLE" 292 "DEM292_NUM_EXPECTED_STRING" 291 "DEM291_NUM_EXPECTED_STRING" 290 "DEM290_CMB_ONBOARD_DEFECT" 289 "DEM289_TEMP_STATE_LATCHED" 288 "DEM288_CURR_STATE_LATCHED" 1 "DEM001_POWERUP" 2 "DEM002_VOLTAGE_BRICK_OV" 3 "DEM003_VOLTAGE_BRICK_UV" 4 "DEM004_VOLTAGE_BRICK_SNA" 5 "DEM005_VOLTAGE_BRICK_IMBAL" 6 "DEM006_VOLTAGE_CAPCY_IMBAL" 7 "DEM007_MODULET_HIGH_DELTA" 8 "DEM008_VOLTAGE_PACK_UV" 9 "DEM009_VOLTAGE_PACK_OV" 10 "DEM010_VOLTAGE_PACK_PLAUSI" 11 "DEM011_VOLTAGE_PCKLINK_MIS" 12 "DEM012_VOLTAGE_BMS_SUPPLY" 13 "DEM013_ADC_ERROR" 14 "DEM014_MODULET_OT" 15 "DEM015_MODULET_SNA" 16 "DEM016_MODULET_LIMPHOME" 17 "DEM017_COOLING_SYS_LHOME" 18 "DEM018_HVIL_LIMPHOME" 19 "DEM019_HVIL_ESS_INHIBIT" 20 "DEM020_MODULET_CHANGE" 21 "DEM021_LG_MAVD_FAULT" 22 "DEM022_LG_RDV_FAULT" 23 "DEM023_BMS_ONBOARDT_SNA" 24 "DEM024_BMS_ONBOARDRH_OH" 25 "DEM025_BMS_ONBOARDRH_SNA" 26 "DEM026_CURRENT_OVERCHARGE" 27 "DEM027_CURRENT_OVERDISCHGE" 28 "DEM028_CURRENT_INVALID" 29 "DEM029_CURRENT_SHORTCIRCT" 30 "DEM030_CRASH_CAN_LATCH" 31 "DEM031_EEPROM_FAIL" 32 "DEM032_PCHG_PACKS_CONNECT" 33 "DEM033_PCHG_ILLEGAL_PRCHG" 34 "DEM034_PCHG_RELAY_FAIL" 35 "DEM035_PCHG_NEG_WELD" 36 "DEM036_PCHG_NEG_PULLIN" 37 "DEM037_PCHG_SHORTCIRCUIT" 38 "DEM038_PCHG_OPENCIRCUIT" 39 "DEM039_PCHG_TIMEOUT" 40 "DEM040_PCHG_FAILED" 41 "DEM041_HVIL_SHUTDOWN" 42 "DEM042_PCHG_POS_WELD" 43 "DEM043_HV_LOCK_TRANSPORT" 44 "DEM044_CTRS_END_OF_LIFE" 45 "DEM045_CTRS_CTRPWRV_HI" 46 "DEM046_CTRS_COILCURR_LOW" 47 "DEM047_CTRS_COILCURR_HIGH" 48 "DEM048_CTRS_CTRPWRV_LOW" 49 "DEM049_CHGE_ILLEGAL_DISCHG" 50 "DEM050_STARTUP_CONDITIONS" 51 "DEM051_VOLTAGE_BMS_SUPPLYH" 52 "DEM052_SAFETYSPI_FAIL" 53 "DEM053_WATCHDOG_ERRORPIN" 54 "DEM054_SAFESTATE_TRIGGERED" 55 "DEM055_DEBUG_CMND_ACTIVE" 56 "DEM056_CRASH_CAN" 57 "DEM057_ISO_EXT_STRAT_4" 58 "DEM058_ISO_EXT_RES_ERR" 59 "DEM059_ISO_EXT_RES_WARN" 60 "DEM060_ISO_INT_RES_ERR" 61 "DEM061_ISO_INT_RES_WARN" 62 "DEM062_EMERGENCY_OPERATION" 63 "DEM063_ENDOFDRIVE" 64 "DEM064_STRINGV_IMBALANCE" 65 "DEM065_STRING_FAULT" 66 "DEM066_ESS_FAULT" 67 "DEM067_ISO_EXT_STRAT_3" 68 "DEM068_MODULE_COUNT_INVALI" 69 "DEM069_PT_MIA" 70 "DEM070_BMSMIA_STRNGMSTR_01" 71 "DEM071_BMSMIA_STRNGMSTR_05" 72 "DEM072_BMSMIA_STRNGMSTR_09" 73 "DEM073_BMSMIA_STRNGMSTR_13" 74 "DEM074_BMSMIA_STRNGMSTR_17" 75 "DEM075_BMSMIA_STRNGMSTR_21" 76 "DEM076_BMSMIA_STRNGMSTR_25" 77 "DEM077_BMSMIA_STRNGMSTR_29" 78 "DEM078_BMSMIA_STRNGMSTR_33" 79 "DEM079_BMSMIA_STRNGMSTR_37" 80 "DEM080_BMSMIA_STRNGMSTR_41" 81 "DEM081_BMSMIA_STRNGMSTR_45" 82 "DEM082_BMSMIA_STRNGMSTR_49" 83 "DEM083_BMSMIA_STRNGMSTR_53" 84 "DEM084_BMSMIA_STRNGMSTR_57" 85 "DEM085_BMSMIA_STRNGMSTR_61" 86 "DEM086_ESSCURRENT_SHORT" 87 "DEM087_PT_MIA_SHUTDOWN" 88 "DEM088_OUTLET_NTC_HI" 89 "DEM089_OUTLET_NTC_LO" 90 "DEM090_BMSMIA_ESSMASTER" 91 "DEM091_PCHG_RES_OVERHEAT" 92 "DEM092_BMSMIA_STRNGSLAVE_0" 93 "DEM093_BMSMIA_STRNGSLAVE_1" 94 "DEM094_BMSMIA_STRNGSLAVE_2" 95 "DEM095_BMSMIA_STRNGSLAVE_3" 96 "DEM096_SC_STATE_SELFTEST" 97 "DEM097_SC_STATE_TEMP" 98 "DEM098_SC_STATE_VOLTAGE" 99 "DEM099_SC_STATE_HVIL" 100 "DEM100_SC_STATE_CONTACTORS" 101 "DEM101_SC_STATE_CURRENT" 102 "DEM102_SC_STATE_CANRX" 103 "DEM103_SC_STATE_CRASH" 104 "DEM104_SC_STATE_CCTRL" 105 "DEM105_SC_STATE_CANTX" 106 "DEM106_SC_STATE_THERMALEVT" 107 "DEM107_SC_STATE_COOLANT" 108 "DEM108_SC_SELFTEST_SFTY_UC" 109 "DEM109_SC_TEMP_HIGH" 110 "DEM110_SC_TEMP_NTC_OPEN" 111 "DEM111_SC_TEMP_NTC_SHORT" 112 "DEM112_CMB_DISCONNECTED" 113 "DEM113_CMB_DEFECT" 114 "DEM114_CMB_COMMERROR" 115 "DEM115_SC_CURR_HALL_PWR_LO" 116 "DEM116_SC_CURR_HALL_VHIGH" 117 "DEM117_SC_CURR_HALL_ADC" 118 "DEM118_SC_CURR_HALL_VLOW" 119 "DEM119_SC_CURR_ISENSE_PWR" 120 "DEM120_SC_CURR_ISENSE1_MIA" 121 "DEM121_SC_CURR_ISENSE2_MIA" 122 "DEM122_SC_CURR_ISENSE3_MIA" 123 "DEM123_SC_CURR_ISENSE4_MIA" 124 "DEM124_SC_CURR_ISENSE5_MIA" 125 "DEM125_SC_CURR_ISENSE1_FLT" 126 "DEM126_SC_CURR_ISENSE2_FLT" 127 "DEM127_SC_CURR_ISENSE3_FLT" 128 "DEM128_SC_CURR_ISENSE4_FLT" 129 "DEM129_SC_CURR_ISENSE5_FLT" 130 "DEM130_SC_CURR_OFFSET" 131 "DEM131_SC_CURR_PLAUSI" 132 "DEM132_SC_CURR_CHARGE_HIGH" 133 "DEM133_SC_CURR_DSCHAR_HIGH" 134 "DEM134_SC_V_CMB_SUMOFCELL" 135 "DEM135_SC_V_SENSE_OPENWIRE" 136 "DEM136_SC_V_CMB_DRV_FROZEN" 137 "DEM137_SC_V_PACK_PLAUSI" 138 "DEM138_SC_HVIL_HW_FLT" 139 "DEM139_SC_HVIL_OPEN" 140 "DEM140_SC_HVIL_TO_SUP" 141 "DEM141_SC_HVIL_TO_CHAS" 142 "DEM142_SC_HVIL_R_HIGH" 143 "DEM143_SC_HVIL_SHORT" 144 "DEM144_SC_CN_ISO_FAIL" 145 "DEM145_HVIL_SYS" 146 "DEM146_SC_CN_POS1_WELDED" 147 "DEM147_SC_CN_NEG1_WELDED" 148 "DEM148_SC_CN_POS2_WELDED" 149 "DEM149_SC_CN_NEG2_WELDED" 150 "DEM150_SC_CN_POS3_WELDED" 151 "DEM151_SC_CN_NEG3_WELDED" 152 "DEM152_SC_CN_HIGH_CY" 153 "DEM153_SC_CN_ISOANDPOTWELD" 154 "DEM154_SC_TEMP_PLAUSI" 155 "DEM155_SC_CURR_HALL_PWR_HI" 156 "DEM156_SC_PYRO_TRIGGERED" 157 "DEM157_SC_PYRO_OPEN" 158 "DEM158_AUX_CTRS_END_OF_LIF" 159 "DEM159_SC_CANRX_PT_MIA" 160 "DEM160_SC_CANRX_PT_CRCALIV" 161 "DEM161_SC_CANRX_LIN_SHUTDN" 162 "DEM162_SC_CANRX_LIN_MIA" 163 "DEM163_SC_CRASH1" 164 "DEM164_SC_CRASH2" 165 "DEM165_SC_CRASHCAN" 166 "DEM166_SC_CCTRL_SELFTEST" 167 "DEM167_SC_CCTRL_DRIVER_FAU" 168 "DEM168_SC_CCTRL_HISIDESTCL" 169 "DEM169_SC_CCTRL_HISIDESTOP" 170 "DEM170_SC_CCTRL_LOSIDESTCL" 171 "DEM171_SC_CCTRL_HVCNDITION" 172 "DEM172_SC_CCTRL_POS1_OPN" 173 "DEM173_SC_CCTRL_POS2_OPN" 174 "DEM174_SC_CCTRL_POS3_OPN" 175 "DEM175_SC_CCTRL_NEG1_OPN" 176 "DEM176_SC_CCTRL_NEG2_OPN" 177 "DEM177_SC_CCTRL_PRE2_OPN" 178 "DEM178_SC_CCTRL_PRE1_OPN" 179 "DEM179_SC_CCTRL_LOSIDESTOP" 180 "DEM180_SC_CCTRL_UNEXPECTED" 181 "DEM181_SC_V_OUT_OF_RANGE" 182 "DEM182_SC_V_LATCHED_UVOV" 183 "DEM183_ISO_EXT_STRAT_2" 184 "DEM184_SC_CANTX_CTRS" 185 "DEM185_SC_CANTX_HVIL" 186 "DEM186_SC_CANTX_ISOL" 187 "DEM187_SC_SBC_WATCHDOG" 188 "DEM188_SC_SBC_FAULT" 189 "DEM189_SC_WATCHDOG" 190 "DEM190_SC_SELFTEST_RAM" 191 "DEM191_SC_SELFTEST_FLASH" 192 "DEM192_CMB_ONBOARDRH_OH" 193 "DEM193_CMB_ONBOARDRH_SNA" 194 "DEM194_CMB_ONBOARDT_OT" 195 "DEM195_CMB_ONBOARDT_CHANGE" 196 "DEM196_PRESSURE_CHANGE" 197 "DEM197_PRESSURE_OVER" 198 "DEM198_PRESSURE_UNDER" 199 "DEM199_PRESSURE_INVALID" 200 "DEM200_THERMAL_EVENT" 201 "DEM201_CMB_ONBOARDT_SNA" 202 "DEM202_REPLACE_DESICCANT" 203 "DEM203_COOLANT_FLOOD_FAULT" 204 "DEM204_LOW_BRICKCAPACITY" 205 "DEM205_BMS_ONBOARDT_OT" 206 "DEM206_HUMIDITY_CHANGE" 207 "DEM207_ISENSE_SUPPLY_CURR" 208 "DEM208_SOC_LOW" 209 "DEM209_SOC_TOOLOW" 210 "DEM210_SOC_TOOHIGH" 211 "DEM211_BALANCING_REQUIRED" 212 "DEM212_DEEP_DISCHARGE" 213 "DEM213_CAN1_BUS_OFF" 214 "DEM214_CAN2_BUS_OFF" 215 "DEM215_CAN3_BUS_OFF" 216 "DEM216_OUTLET_NTC_RATNAL" 217 "DEM217_FUSE_PACK" 218 "DEM218_FUSE_B_OPEN" 219 "DEM219_FUSE_C_OPEN" 220 "DEM220_FUSE_D_OPEN" 221 "DEM221_FUSE_E_OPEN" 222 "DEM222_PUMP_DRY_RUN" 223 "DEM223_PUMP_PERFORMANCE" 224 "DEM224_PUMP_LIN_FAILURE" 225 "DEM225_PUMP_SUPPLY_VOLTAGE" 226 "DEM226_PUMP_RECOVERY_FAIL" 227 "DEM227_CTR_POS_OPENED" 228 "DEM228_CTR_NEG_OPENED" 229 "DEM229_STRSET_SLAVE1_FAULT" 230 "DEM230_STRSET_SLAVE2_FAULT" 231 "DEM231_CTRSAUX_CLFAIL_HVON" 232 "DEM232_CTRSAUX_CLFAIL_VDIF" 233 "DEM233_CTRSAUX_POS1_OPENED" 234 "DEM234_CTRSAUX_NEG1_OPENED" 235 "DEM235_CTRSAUX_POS1_WELDED" 236 "DEM236_CTRSAUX_NEG1_WELDED" 237 "DEM237_CTRSAUX_POS1_PULLIN" 238 "DEM238_CTRSAUX_NEG1_PULLIN" 239 "DEM239_INLET_NTC_RATNAL" 240 "DEM240_INLET_NTC_HI" 241 "DEM241_INLET_NTC_LO" 242 "DEM242_VOLTAGE_LINK2_RATNA" 243 "DEM243_VOLTAGE_LINK2_HI" 244 "DEM244_VOLTAGE_LINK2_LO" 245 "DEM245_CMB_ONBOARD_IMPOSSI" 246 "DEM246_VOLTAGE_LINK1_HI" 247 "DEM247_VOLTAGE_LINK1_LO" 248 "DEM248_NTC_SUPPLY_LO" 249 "DEM249_NTC_SUPPLY_HI" 250 "DEM250_VOLTAGE_LINK3_RATNA" 251 "DEM251_VOLTAGE_LINK3_HI" 252 "DEM252_VOLTAGE_LINK3_LO" 253 "DEM253_BALANCING_STUCK" 254 "DEM254_ARM_EXCEPTION" 255 "DEM255_ERROR_HOOKS" 256 "DEM256_XCP_CAL_CHANGE" 257 "DEM257_XCP_CAL_PERM_CHANGE" 258 "DEM258_TASK_TIME_OVERFLOW" 259 "DEM259_ISO_CIRCUIT" 260 "DEM260_COOLANT_MOIST_FAULT" 261 "DEM261_COOLANT_FLOOD_WARN" 262 "DEM262_COOLANT_MOIST_WARN" 263 "DEM263_MODULET_IMPLAUSIBLE" 264 "DEM264_REQUEST_ON_WITH_HV_" 265 "DEM265_CSERS_PCODE" 266 "DEM266_PRELIM_CNTR_CL_FAIL" 267 "DEM267_FLUIDLVL_LOW" 268 "DEM268_FLUIDLVL_FAILURE" 269 "DEM269_SC_COOLANT_CONTAM" 270 "DEM270_SC_COOLANT_MIA" 271 "DEM271_PRESSURE_VHI" 272 "DEM272_PRESSURE_VLO" 273 "DEM273_SC_COOLANT_FAIL" 274 "DEM274_CTRSAUX_POS2_OPENED" 275 "DEM275_CTRSAUX_POS3_OPENED" 276 "DEM276_CTRSAUX_POS2_WELDED" 277 "DEM277_CTRSAUX_POS3_WELDED" 278 "DEM278_CTRSAUX_POS2_PULLIN" 279 "DEM279_CTRSAUX_POS3_PULLIN" 280 "DEM280_CMB_HUMIDITY_TEMP_C" 281 "DEM281_THERMAL_EVENT_CMB_R" 282 "DEM282_CUS_BRICKOV" 283 "DEM283_CUS_BRICKUV" 284 "DEM284_CUS_OVERCHRG" 285 "DEM285_CUS_OVERDCHRG" 286 "DEM286_CUS_CURRENT_CHG" 287 "DEM287_CUS_CURRENT_DCHG" ;
VAL_ 1024 DEM001_POWERUP_BMS01 3 "DEM_INVALID" 2 "DEM_FAILED" 1 "DEM_PASSED" 0 "DEM_NOTTESTED" ;
VAL_ 1024 DEM002_VOLTAGE_BRICK_OV_BMS01 3 "DEM_INVALID" 2 "DEM_FAILED" 1 "DEM_PASSED" 0 "DEM_NOTTESTED" ;
VAL_ 1024 DEM003_VOLTAGE_BRICK_UV_BMS01 3 "DEM_INVALID" 2 "DEM_FAILED" 1 "DEM_PASSED" 0 "DEM_NOTTESTED" ;
VAL_ 1024 DEM004_VOLTAGE_BRICK_SNA_BMS01 3 "DEM_INVALID" 2 "DEM_FAILED" 1 "DEM_PASSED" 0 "DEM_NOTTESTED" ;
VAL_ 1024 DEM005_VOLTAGE_BRICK_IMBAL_BMS01 3 "DEM_INVALID" 2 "DEM_FAILED" 1 "DEM_PASSED" 0 "DEM_NOTTESTED" ;
VAL_ 1024 DEM006_VOLTAGE_CAPCY_IMBAL_BMS01 3 "DEM_INVALID" 2 "DEM_FAILED" 1 "DEM_PASSED" 0 "DEM_NOTTESTED" ;
VAL_ 1024 DEM007_MODULET_HIGH_DELTA_BMS01 3 "DEM_INVALID" 2 "DEM_FAILED" 1 "DEM_PASSED" 0 "DEM_NOTTESTED" ;
VAL_ 1024 DEM008_VOLTAGE_PACK_UV_BMS01 3 "DEM_INVALID" 2 "DEM_FAILED" 1 "DEM_PASSED" 0 "DEM_NOTTESTED" ;
VAL_ 1024 DEM009_VOLTAGE_PACK_OV_BMS01 3 "DEM_INVALID" 2 "DEM_FAILED" 1 "DEM_PASSED" 0 "DEM_NOTTESTED" ;
VAL_ 1024 DEM010_VOLTAGE_PACK_PLAUSI_BMS01 3 "DEM_INVALID" 2 "DEM_FAILED" 1 "DEM_PASSED" 0 "DEM_NOTTESTED" ;
VAL_ 1024 DEM011_VOLTAGE_PCKLINK_MIS_BMS01 3 "DEM_INVALID" 2 "DEM_FAILED" 1 "DEM_PASSED" 0 "DEM_NOTTESTED" ;
VAL_ 1024 DEM012_VOLTAGE_BMS_SUPPLY_BMS01 3 "DEM_INVALID" 2 "DEM_FAILED" 1 "DEM_PASSED" 0 "DEM_NOTTESTED" ;
VAL_ 1024 DEM013_ADC_ERROR_BMS01 3 "DEM_INVALID" 2 "DEM_FAILED" 1 "DEM_PASSED" 0 "DEM_NOTTESTED" ;
VAL_ 1024 DEM014_MODULET_OT_BMS01 3 "DEM_INVALID" 2 "DEM_FAILED" 1 "DEM_PASSED" 0 "DEM_NOTTESTED" ;
VAL_ 1024 DEM015_MODULET_SNA_BMS01 3 "DEM_INVALID" 2 "DEM_FAILED" 1 "DEM_PASSED" 0 "DEM_NOTTESTED" ;
VAL_ 1024 DEM016_MODULET_LIMPHOME_BMS01 3 "DEM_INVALID" 2 "DEM_FAILED" 1 "DEM_PASSED" 0 "DEM_NOTTESTED" ;
VAL_ 1024 DEM017_COOLING_SYS_LHOME_BMS01 3 "DEM_INVALID" 2 "DEM_FAILED" 1 "DEM_PASSED" 0 "DEM_NOTTESTED" ;
VAL_ 1024 DEM018_HVIL_LIMPHOME_BMS01 3 "DEM_INVALID" 2 "DEM_FAILED" 1 "DEM_PASSED" 0 "DEM_NOTTESTED" ;
VAL_ 1024 DEM019_HVIL_ESS_INHIBIT_BMS01 3 "DEM_INVALID" 2 "DEM_FAILED" 1 "DEM_PASSED" 0 "DEM_NOTTESTED" ;
VAL_ 1024 DEM020_MODULET_CHANGE_BMS01 3 "DEM_INVALID" 2 "DEM_FAILED" 1 "DEM_PASSED" 0 "DEM_NOTTESTED" ;
VAL_ 1024 DEM021_LG_MAVD_FAULT_BMS01 3 "DEM_INVALID" 2 "DEM_FAILED" 1 "DEM_PASSED" 0 "DEM_NOTTESTED" ;
VAL_ 1024 DEM022_LG_RDV_FAULT_BMS01 3 "DEM_INVALID" 2 "DEM_FAILED" 1 "DEM_PASSED" 0 "DEM_NOTTESTED" ;
VAL_ 1024 DEM023_BMS_ONBOARDT_SNA_BMS01 3 "DEM_INVALID" 2 "DEM_FAILED" 1 "DEM_PASSED" 0 "DEM_NOTTESTED" ;
VAL_ 1024 DEM024_BMS_ONBOARDRH_OH_BMS01 3 "DEM_INVALID" 2 "DEM_FAILED" 1 "DEM_PASSED" 0 "DEM_NOTTESTED" ;
VAL_ 1024 DEM025_BMS_ONBOARDRH_SNA_BMS01 3 "DEM_INVALID" 2 "DEM_FAILED" 1 "DEM_PASSED" 0 "DEM_NOTTESTED" ;
VAL_ 1024 DEM026_CURRENT_OVERCHARGE_BMS01 3 "DEM_INVALID" 2 "DEM_FAILED" 1 "DEM_PASSED" 0 "DEM_NOTTESTED" ;
VAL_ 1024 DEM027_CURRENT_OVERDISCHGE_BMS01 3 "DEM_INVALID" 2 "DEM_FAILED" 1 "DEM_PASSED" 0 "DEM_NOTTESTED" ;
VAL_ 1024 DEM028_CURRENT_INVALID_BMS01 3 "DEM_INVALID" 2 "DEM_FAILED" 1 "DEM_PASSED" 0 "DEM_NOTTESTED" ;
VAL_ 1024 DEM029_CURRENT_SHORTCIRCT_BMS01 3 "DEM_INVALID" 2 "DEM_FAILED" 1 "DEM_PASSED" 0 "DEM_NOTTESTED" ;
VAL_ 1024 DEM030_CRASH_CAN_LATCH_BMS01 3 "DEM_INVALID" 2 "DEM_FAILED" 1 "DEM_PASSED" 0 "DEM_NOTTESTED" ;
VAL_ 1024 DEM031_EEPROM_FAIL_BMS01 3 "DEM_INVALID" 2 "DEM_FAILED" 1 "DEM_PASSED" 0 "DEM_NOTTESTED" ;
VAL_ 1088 DEM032_PCHG_PACKS_CONNECT_BMS01 3 "DEM_INVALID" 2 "DEM_FAILED" 1 "DEM_PASSED" 0 "DEM_NOTTESTED" ;
VAL_ 1088 DEM033_PCHG_ILLEGAL_PRCHG_BMS01 3 "DEM_INVALID" 2 "DEM_FAILED" 1 "DEM_PASSED" 0 "DEM_NOTTESTED" ;
VAL_ 1088 DEM034_PCHG_RELAY_FAIL_BMS01 3 "DEM_INVALID" 2 "DEM_FAILED" 1 "DEM_PASSED" 0 "DEM_NOTTESTED" ;
VAL_ 1088 DEM035_PCHG_NEG_WELD_BMS01 3 "DEM_INVALID" 2 "DEM_FAILED" 1 "DEM_PASSED" 0 "DEM_NOTTESTED" ;
VAL_ 1088 DEM036_PCHG_NEG_PULLIN_BMS01 3 "DEM_INVALID" 2 "DEM_FAILED" 1 "DEM_PASSED" 0 "DEM_NOTTESTED" ;
VAL_ 1088 DEM037_PCHG_SHORTCIRCUIT_BMS01 3 "DEM_INVALID" 2 "DEM_FAILED" 1 "DEM_PASSED" 0 "DEM_NOTTESTED" ;
VAL_ 1088 DEM038_PCHG_OPENCIRCUIT_BMS01 3 "DEM_INVALID" 2 "DEM_FAILED" 1 "DEM_PASSED" 0 "DEM_NOTTESTED" ;
VAL_ 1088 DEM039_PCHG_TIMEOUT_BMS01 3 "DEM_INVALID" 2 "DEM_FAILED" 1 "DEM_PASSED" 0 "DEM_NOTTESTED" ;
VAL_ 1088 DEM040_PCHG_FAILED_BMS01 3 "DEM_INVALID" 2 "DEM_FAILED" 1 "DEM_PASSED" 0 "DEM_NOTTESTED" ;
VAL_ 1088 DEM041_HVIL_SHUTDOWN_BMS01 3 "DEM_INVALID" 2 "DEM_FAILED" 1 "DEM_PASSED" 0 "DEM_NOTTESTED" ;
VAL_ 1088 DEM042_PCHG_POS_WELD_BMS01 3 "DEM_INVALID" 2 "DEM_FAILED" 1 "DEM_PASSED" 0 "DEM_NOTTESTED" ;
VAL_ 1088 DEM043_HV_LOCK_TRANSPORT_BMS01 3 "DEM_INVALID" 2 "DEM_FAILED" 1 "DEM_PASSED" 0 "DEM_NOTTESTED" ;
VAL_ 1088 DEM044_CTRS_END_OF_LIFE_BMS01 3 "DEM_INVALID" 2 "DEM_FAILED" 1 "DEM_PASSED" 0 "DEM_NOTTESTED" ;
VAL_ 1088 DEM045_CTRS_CTRPWRV_HI_BMS01 3 "DEM_INVALID" 2 "DEM_FAILED" 1 "DEM_PASSED" 0 "DEM_NOTTESTED" ;
VAL_ 1088 DEM046_CTRS_COILCURR_LOW_BMS01 3 "DEM_INVALID" 2 "DEM_FAILED" 1 "DEM_PASSED" 0 "DEM_NOTTESTED" ;
VAL_ 1088 DEM047_CTRS_COILCURR_HIGH_BMS01 3 "DEM_INVALID" 2 "DEM_FAILED" 1 "DEM_PASSED" 0 "DEM_NOTTESTED" ;
VAL_ 1088 DEM048_CTRS_CTRPWRV_LOW_BMS01 3 "DEM_INVALID" 2 "DEM_FAILED" 1 "DEM_PASSED" 0 "DEM_NOTTESTED" ;
VAL_ 1088 DEM049_CHGE_ILLEGAL_DISCHG_BMS01 3 "DEM_INVALID" 2 "DEM_FAILED" 1 "DEM_PASSED" 0 "DEM_NOTTESTED" ;
VAL_ 1088 DEM050_STARTUP_CONDITIONS_BMS01 3 "DEM_INVALID" 2 "DEM_FAILED" 1 "DEM_PASSED" 0 "DEM_NOTTESTED" ;
VAL_ 1088 DEM051_VOLTAGE_BMS_SUPPLYH_BMS01 3 "DEM_INVALID" 2 "DEM_FAILED" 1 "DEM_PASSED" 0 "DEM_NOTTESTED" ;
VAL_ 1088 DEM052_SAFETYSPI_FAIL_BMS01 3 "DEM_INVALID" 2 "DEM_FAILED" 1 "DEM_PASSED" 0 "DEM_NOTTESTED" ;
VAL_ 1088 DEM053_WATCHDOG_ERRORPIN_BMS01 3 "DEM_INVALID" 2 "DEM_FAILED" 1 "DEM_PASSED" 0 "DEM_NOTTESTED" ;
VAL_ 1088 DEM054_SAFESTATE_TRIGGERED_BMS01 3 "DEM_INVALID" 2 "DEM_FAILED" 1 "DEM_PASSED" 0 "DEM_NOTTESTED" ;
VAL_ 1088 DEM055_DEBUG_CMND_ACTIVE_BMS01 3 "DEM_INVALID" 2 "DEM_FAILED" 1 "DEM_PASSED" 0 "DEM_NOTTESTED" ;
VAL_ 1088 DEM056_CRASH_CAN_BMS01 3 "DEM_INVALID" 2 "DEM_FAILED" 1 "DEM_PASSED" 0 "DEM_NOTTESTED" ;
VAL_ 1088 DEM057_ISO_EXT_STRAT_4_BMS01 3 "DEM_INVALID" 2 "DEM_FAILED" 1 "DEM_PASSED" 0 "DEM_NOTTESTED" ;
VAL_ 1088 DEM058_ISO_EXT_RES_ERR_BMS01 3 "DEM_INVALID" 2 "DEM_FAILED" 1 "DEM_PASSED" 0 "DEM_NOTTESTED" ;
VAL_ 1088 DEM059_ISO_EXT_RES_WARN_BMS01 3 "DEM_INVALID" 2 "DEM_FAILED" 1 "DEM_PASSED" 0 "DEM_NOTTESTED" ;
VAL_ 1088 DEM060_ISO_INT_RES_ERR_BMS01 3 "DEM_INVALID" 2 "DEM_FAILED" 1 "DEM_PASSED" 0 "DEM_NOTTESTED" ;
VAL_ 1088 DEM061_ISO_INT_RES_WARN_BMS01 3 "DEM_INVALID" 2 "DEM_FAILED" 1 "DEM_PASSED" 0 "DEM_NOTTESTED" ;
VAL_ 1088 DEM062_EMERGENCY_OPERATION_BMS01 3 "DEM_INVALID" 2 "DEM_FAILED" 1 "DEM_PASSED" 0 "DEM_NOTTESTED" ;
VAL_ 1088 DEM063_ENDOFDRIVE_BMS01 3 "DEM_INVALID" 2 "DEM_FAILED" 1 "DEM_PASSED" 0 "DEM_NOTTESTED" ;
VAL_ 1152 DEM064_STRINGV_IMBALANCE_BMS01 3 "DEM_INVALID" 2 "DEM_FAILED" 1 "DEM_PASSED" 0 "DEM_NOTTESTED" ;
VAL_ 1152 DEM065_STRING_FAULT_BMS01 3 "DEM_INVALID" 2 "DEM_FAILED" 1 "DEM_PASSED" 0 "DEM_NOTTESTED" ;
VAL_ 1152 DEM066_ESS_FAULT_BMS01 3 "DEM_INVALID" 2 "DEM_FAILED" 1 "DEM_PASSED" 0 "DEM_NOTTESTED" ;
VAL_ 1152 DEM067_ISO_EXT_STRAT_3_BMS01 3 "DEM_INVALID" 2 "DEM_FAILED" 1 "DEM_PASSED" 0 "DEM_NOTTESTED" ;
VAL_ 1152 DEM068_MODULE_COUNT_INVALI_BMS01 3 "DEM_INVALID" 2 "DEM_FAILED" 1 "DEM_PASSED" 0 "DEM_NOTTESTED" ;
VAL_ 1152 DEM069_PT_MIA_BMS01 3 "DEM_INVALID" 2 "DEM_FAILED" 1 "DEM_PASSED" 0 "DEM_NOTTESTED" ;
VAL_ 1152 DEM070_BMSMIA_STRNGMSTR_01_BMS01 3 "DEM_INVALID" 2 "DEM_FAILED" 1 "DEM_PASSED" 0 "DEM_NOTTESTED" ;
VAL_ 1152 DEM071_BMSMIA_STRNGMSTR_05_BMS01 3 "DEM_INVALID" 2 "DEM_FAILED" 1 "DEM_PASSED" 0 "DEM_NOTTESTED" ;
VAL_ 1152 DEM072_BMSMIA_STRNGMSTR_09_BMS01 3 "DEM_INVALID" 2 "DEM_FAILED" 1 "DEM_PASSED" 0 "DEM_NOTTESTED" ;
VAL_ 1152 DEM073_BMSMIA_STRNGMSTR_13_BMS01 3 "DEM_INVALID" 2 "DEM_FAILED" 1 "DEM_PASSED" 0 "DEM_NOTTESTED" ;
VAL_ 1152 DEM074_BMSMIA_STRNGMSTR_17_BMS01 3 "DEM_INVALID" 2 "DEM_FAILED" 1 "DEM_PASSED" 0 "DEM_NOTTESTED" ;
VAL_ 1152 DEM075_BMSMIA_STRNGMSTR_21_BMS01 3 "DEM_INVALID" 2 "DEM_FAILED" 1 "DEM_PASSED" 0 "DEM_NOTTESTED" ;
VAL_ 1152 DEM076_BMSMIA_STRNGMSTR_25_BMS01 3 "DEM_INVALID" 2 "DEM_FAILED" 1 "DEM_PASSED" 0 "DEM_NOTTESTED" ;
VAL_ 1152 DEM077_BMSMIA_STRNGMSTR_29_BMS01 3 "DEM_INVALID" 2 "DEM_FAILED" 1 "DEM_PASSED" 0 "DEM_NOTTESTED" ;
VAL_ 1152 DEM078_BMSMIA_STRNGMSTR_33_BMS01 3 "DEM_INVALID" 2 "DEM_FAILED" 1 "DEM_PASSED" 0 "DEM_NOTTESTED" ;
VAL_ 1152 DEM079_BMSMIA_STRNGMSTR_37_BMS01 3 "DEM_INVALID" 2 "DEM_FAILED" 1 "DEM_PASSED" 0 "DEM_NOTTESTED" ;
VAL_ 1152 DEM080_BMSMIA_STRNGMSTR_41_BMS01 3 "DEM_INVALID" 2 "DEM_FAILED" 1 "DEM_PASSED" 0 "DEM_NOTTESTED" ;
VAL_ 1152 DEM081_BMSMIA_STRNGMSTR_45_BMS01 3 "DEM_INVALID" 2 "DEM_FAILED" 1 "DEM_PASSED" 0 "DEM_NOTTESTED" ;
VAL_ 1152 DEM082_BMSMIA_STRNGMSTR_49_BMS01 3 "DEM_INVALID" 2 "DEM_FAILED" 1 "DEM_PASSED" 0 "DEM_NOTTESTED" ;
VAL_ 1152 DEM083_BMSMIA_STRNGMSTR_53_BMS01 3 "DEM_INVALID" 2 "DEM_FAILED" 1 "DEM_PASSED" 0 "DEM_NOTTESTED" ;
VAL_ 1152 DEM084_BMSMIA_STRNGMSTR_57_BMS01 3 "DEM_INVALID" 2 "DEM_FAILED" 1 "DEM_PASSED" 0 "DEM_NOTTESTED" ;
VAL_ 1152 DEM085_BMSMIA_STRNGMSTR_61_BMS01 3 "DEM_INVALID" 2 "DEM_FAILED" 1 "DEM_PASSED" 0 "DEM_NOTTESTED" ;
VAL_ 1152 DEM086_ESSCURRENT_SHORT_BMS01 3 "DEM_INVALID" 2 "DEM_FAILED" 1 "DEM_PASSED" 0 "DEM_NOTTESTED" ;
VAL_ 1152 DEM087_PT_MIA_SHUTDOWN_BMS01 3 "DEM_INVALID" 2 "DEM_FAILED" 1 "DEM_PASSED" 0 "DEM_NOTTESTED" ;
VAL_ 1152 DEM088_OUTLET_NTC_HI_BMS01 3 "DEM_INVALID" 2 "DEM_FAILED" 1 "DEM_PASSED" 0 "DEM_NOTTESTED" ;
VAL_ 1152 DEM089_OUTLET_NTC_LO_BMS01 3 "DEM_INVALID" 2 "DEM_FAILED" 1 "DEM_PASSED" 0 "DEM_NOTTESTED" ;
VAL_ 1152 DEM090_BMSMIA_ESSMASTER_BMS01 3 "DEM_INVALID" 2 "DEM_FAILED" 1 "DEM_PASSED" 0 "DEM_NOTTESTED" ;
VAL_ 1152 DEM091_PCHG_RES_OVERHEAT_BMS01 3 "DEM_INVALID" 2 "DEM_FAILED" 1 "DEM_PASSED" 0 "DEM_NOTTESTED" ;
VAL_ 1152 DEM092_BMSMIA_STRNGSLAVE_0_BMS01 3 "DEM_INVALID" 2 "DEM_FAILED" 1 "DEM_PASSED" 0 "DEM_NOTTESTED" ;
VAL_ 1152 DEM093_BMSMIA_STRNGSLAVE_1_BMS01 3 "DEM_INVALID" 2 "DEM_FAILED" 1 "DEM_PASSED" 0 "DEM_NOTTESTED" ;
VAL_ 1152 DEM094_BMSMIA_STRNGSLAVE_2_BMS01 3 "DEM_INVALID" 2 "DEM_FAILED" 1 "DEM_PASSED" 0 "DEM_NOTTESTED" ;
VAL_ 1152 DEM095_BMSMIA_STRNGSLAVE_3_BMS01 3 "DEM_INVALID" 2 "DEM_FAILED" 1 "DEM_PASSED" 0 "DEM_NOTTESTED" ;
VAL_ 1216 DEM096_SC_STATE_SELFTEST_BMS01 3 "DEM_INVALID" 2 "DEM_FAILED" 1 "DEM_PASSED" 0 "DEM_NOTTESTED" ;
VAL_ 1216 DEM097_SC_STATE_TEMP_BMS01 3 "DEM_INVALID" 2 "DEM_FAILED" 1 "DEM_PASSED" 0 "DEM_NOTTESTED" ;
VAL_ 1216 DEM098_SC_STATE_VOLTAGE_BMS01 3 "DEM_INVALID" 2 "DEM_FAILED" 1 "DEM_PASSED" 0 "DEM_NOTTESTED" ;
VAL_ 1216 DEM099_SC_STATE_HVIL_BMS01 3 "DEM_INVALID" 2 "DEM_FAILED" 1 "DEM_PASSED" 0 "DEM_NOTTESTED" ;
VAL_ 1216 DEM100_SC_STATE_CONTACTORS_BMS01 3 "DEM_INVALID" 2 "DEM_FAILED" 1 "DEM_PASSED" 0 "DEM_NOTTESTED" ;
VAL_ 1216 DEM101_SC_STATE_CURRENT_BMS01 3 "DEM_INVALID" 2 "DEM_FAILED" 1 "DEM_PASSED" 0 "DEM_NOTTESTED" ;
VAL_ 1216 DEM102_SC_STATE_CANRX_BMS01 3 "DEM_INVALID" 2 "DEM_FAILED" 1 "DEM_PASSED" 0 "DEM_NOTTESTED" ;
VAL_ 1216 DEM103_SC_STATE_CRASH_BMS01 3 "DEM_INVALID" 2 "DEM_FAILED" 1 "DEM_PASSED" 0 "DEM_NOTTESTED" ;
VAL_ 1216 DEM104_SC_STATE_CCTRL_BMS01 3 "DEM_INVALID" 2 "DEM_FAILED" 1 "DEM_PASSED" 0 "DEM_NOTTESTED" ;
VAL_ 1216 DEM105_SC_STATE_CANTX_BMS01 3 "DEM_INVALID" 2 "DEM_FAILED" 1 "DEM_PASSED" 0 "DEM_NOTTESTED" ;
VAL_ 1216 DEM106_SC_STATE_THERMALEVT_BMS01 3 "DEM_INVALID" 2 "DEM_FAILED" 1 "DEM_PASSED" 0 "DEM_NOTTESTED" ;
VAL_ 1216 DEM107_SC_STATE_COOLANT_BMS01 3 "DEM_INVALID" 2 "DEM_FAILED" 1 "DEM_PASSED" 0 "DEM_NOTTESTED" ;
VAL_ 1216 DEM108_SC_SELFTEST_SFTY_UC_BMS01 3 "DEM_INVALID" 2 "DEM_FAILED" 1 "DEM_PASSED" 0 "DEM_NOTTESTED" ;
VAL_ 1216 DEM109_SC_TEMP_HIGH_BMS01 3 "DEM_INVALID" 2 "DEM_FAILED" 1 "DEM_PASSED" 0 "DEM_NOTTESTED" ;
VAL_ 1216 DEM110_SC_TEMP_NTC_OPEN_BMS01 3 "DEM_INVALID" 2 "DEM_FAILED" 1 "DEM_PASSED" 0 "DEM_NOTTESTED" ;
VAL_ 1216 DEM111_SC_TEMP_NTC_SHORT_BMS01 3 "DEM_INVALID" 2 "DEM_FAILED" 1 "DEM_PASSED" 0 "DEM_NOTTESTED" ;
VAL_ 1216 DEM112_CMB_DISCONNECTED_BMS01 3 "DEM_INVALID" 2 "DEM_FAILED" 1 "DEM_PASSED" 0 "DEM_NOTTESTED" ;
VAL_ 1216 DEM113_CMB_DEFECT_BMS01 3 "DEM_INVALID" 2 "DEM_FAILED" 1 "DEM_PASSED" 0 "DEM_NOTTESTED" ;
VAL_ 1216 DEM114_CMB_COMMERROR_BMS01 3 "DEM_INVALID" 2 "DEM_FAILED" 1 "DEM_PASSED" 0 "DEM_NOTTESTED" ;
VAL_ 1216 DEM115_SC_CURR_HALL_PWR_LO_BMS01 3 "DEM_INVALID" 2 "DEM_FAILED" 1 "DEM_PASSED" 0 "DEM_NOTTESTED" ;
VAL_ 1216 DEM116_SC_CURR_HALL_VHIGH_BMS01 3 "DEM_INVALID" 2 "DEM_FAILED" 1 "DEM_PASSED" 0 "DEM_NOTTESTED" ;
VAL_ 1216 DEM117_SC_CURR_HALL_ADC_BMS01 3 "DEM_INVALID" 2 "DEM_FAILED" 1 "DEM_PASSED" 0 "DEM_NOTTESTED" ;
VAL_ 1216 DEM118_SC_CURR_HALL_VLOW_BMS01 3 "DEM_INVALID" 2 "DEM_FAILED" 1 "DEM_PASSED" 0 "DEM_NOTTESTED" ;
VAL_ 1216 DEM119_SC_CURR_ISENSE_PWR_BMS01 3 "DEM_INVALID" 2 "DEM_FAILED" 1 "DEM_PASSED" 0 "DEM_NOTTESTED" ;
VAL_ 1216 DEM120_SC_CURR_ISENSE1_MIA_BMS01 3 "DEM_INVALID" 2 "DEM_FAILED" 1 "DEM_PASSED" 0 "DEM_NOTTESTED" ;
VAL_ 1216 DEM121_SC_CURR_ISENSE2_MIA_BMS01 3 "DEM_INVALID" 2 "DEM_FAILED" 1 "DEM_PASSED" 0 "DEM_NOTTESTED" ;
VAL_ 1216 DEM122_SC_CURR_ISENSE3_MIA_BMS01 3 "DEM_INVALID" 2 "DEM_FAILED" 1 "DEM_PASSED" 0 "DEM_NOTTESTED" ;
VAL_ 1216 DEM123_SC_CURR_ISENSE4_MIA_BMS01 3 "DEM_INVALID" 2 "DEM_FAILED" 1 "DEM_PASSED" 0 "DEM_NOTTESTED" ;
VAL_ 1216 DEM124_SC_CURR_ISENSE5_MIA_BMS01 3 "DEM_INVALID" 2 "DEM_FAILED" 1 "DEM_PASSED" 0 "DEM_NOTTESTED" ;
VAL_ 1216 DEM125_SC_CURR_ISENSE1_FLT_BMS01 3 "DEM_INVALID" 2 "DEM_FAILED" 1 "DEM_PASSED" 0 "DEM_NOTTESTED" ;
VAL_ 1216 DEM126_SC_CURR_ISENSE2_FLT_BMS01 3 "DEM_INVALID" 2 "DEM_FAILED" 1 "DEM_PASSED" 0 "DEM_NOTTESTED" ;
VAL_ 1216 DEM127_SC_CURR_ISENSE3_FLT_BMS01 3 "DEM_INVALID" 2 "DEM_FAILED" 1 "DEM_PASSED" 0 "DEM_NOTTESTED" ;
VAL_ 1280 DEM128_SC_CURR_ISENSE4_FLT_BMS01 3 "DEM_INVALID" 2 "DEM_FAILED" 1 "DEM_PASSED" 0 "DEM_NOTTESTED" ;
VAL_ 1280 DEM129_SC_CURR_ISENSE5_FLT_BMS01 3 "DEM_INVALID" 2 "DEM_FAILED" 1 "DEM_PASSED" 0 "DEM_NOTTESTED" ;
VAL_ 1280 DEM130_SC_CURR_OFFSET_BMS01 3 "DEM_INVALID" 2 "DEM_FAILED" 1 "DEM_PASSED" 0 "DEM_NOTTESTED" ;
VAL_ 1280 DEM131_SC_CURR_PLAUSI_BMS01 3 "DEM_INVALID" 2 "DEM_FAILED" 1 "DEM_PASSED" 0 "DEM_NOTTESTED" ;
VAL_ 1280 DEM132_SC_CURR_CHARGE_HIGH_BMS01 3 "DEM_INVALID" 2 "DEM_FAILED" 1 "DEM_PASSED" 0 "DEM_NOTTESTED" ;
VAL_ 1280 DEM133_SC_CURR_DSCHAR_HIGH_BMS01 3 "DEM_INVALID" 2 "DEM_FAILED" 1 "DEM_PASSED" 0 "DEM_NOTTESTED" ;
VAL_ 1280 DEM134_SC_V_CMB_SUMOFCELL_BMS01 3 "DEM_INVALID" 2 "DEM_FAILED" 1 "DEM_PASSED" 0 "DEM_NOTTESTED" ;
VAL_ 1280 DEM135_SC_V_SENSE_OPENWIRE_BMS01 3 "DEM_INVALID" 2 "DEM_FAILED" 1 "DEM_PASSED" 0 "DEM_NOTTESTED" ;
VAL_ 1280 DEM136_SC_V_CMB_DRV_FROZEN_BMS01 3 "DEM_INVALID" 2 "DEM_FAILED" 1 "DEM_PASSED" 0 "DEM_NOTTESTED" ;
VAL_ 1280 DEM137_SC_V_PACK_PLAUSI_BMS01 3 "DEM_INVALID" 2 "DEM_FAILED" 1 "DEM_PASSED" 0 "DEM_NOTTESTED" ;
VAL_ 1280 DEM138_SC_HVIL_HW_FLT_BMS01 3 "DEM_INVALID" 2 "DEM_FAILED" 1 "DEM_PASSED" 0 "DEM_NOTTESTED" ;
VAL_ 1280 DEM139_SC_HVIL_OPEN_BMS01 3 "DEM_INVALID" 2 "DEM_FAILED" 1 "DEM_PASSED" 0 "DEM_NOTTESTED" ;
VAL_ 1280 DEM140_SC_HVIL_TO_SUP_BMS01 3 "DEM_INVALID" 2 "DEM_FAILED" 1 "DEM_PASSED" 0 "DEM_NOTTESTED" ;
VAL_ 1280 DEM141_SC_HVIL_TO_CHAS_BMS01 3 "DEM_INVALID" 2 "DEM_FAILED" 1 "DEM_PASSED" 0 "DEM_NOTTESTED" ;
VAL_ 1280 DEM142_SC_HVIL_R_HIGH_BMS01 3 "DEM_INVALID" 2 "DEM_FAILED" 1 "DEM_PASSED" 0 "DEM_NOTTESTED" ;
VAL_ 1280 DEM143_SC_HVIL_SHORT_BMS01 3 "DEM_INVALID" 2 "DEM_FAILED" 1 "DEM_PASSED" 0 "DEM_NOTTESTED" ;
VAL_ 1280 DEM144_SC_CN_ISO_FAIL_BMS01 3 "DEM_INVALID" 2 "DEM_FAILED" 1 "DEM_PASSED" 0 "DEM_NOTTESTED" ;
VAL_ 1280 DEM145_HVIL_SYS_BMS01 3 "DEM_INVALID" 2 "DEM_FAILED" 1 "DEM_PASSED" 0 "DEM_NOTTESTED" ;
VAL_ 1280 DEM146_SC_CN_POS1_WELDED_BMS01 3 "DEM_INVALID" 2 "DEM_FAILED" 1 "DEM_PASSED" 0 "DEM_NOTTESTED" ;
VAL_ 1280 DEM147_SC_CN_NEG1_WELDED_BMS01 3 "DEM_INVALID" 2 "DEM_FAILED" 1 "DEM_PASSED" 0 "DEM_NOTTESTED" ;
VAL_ 1280 DEM148_SC_CN_POS2_WELDED_BMS01 3 "DEM_INVALID" 2 "DEM_FAILED" 1 "DEM_PASSED" 0 "DEM_NOTTESTED" ;
VAL_ 1280 DEM149_SC_CN_NEG2_WELDED_BMS01 3 "DEM_INVALID" 2 "DEM_FAILED" 1 "DEM_PASSED" 0 "DEM_NOTTESTED" ;
VAL_ 1280 DEM150_SC_CN_POS3_WELDED_BMS01 3 "DEM_INVALID" 2 "DEM_FAILED" 1 "DEM_PASSED" 0 "DEM_NOTTESTED" ;
VAL_ 1280 DEM151_SC_CN_NEG3_WELDED_BMS01 3 "DEM_INVALID" 2 "DEM_FAILED" 1 "DEM_PASSED" 0 "DEM_NOTTESTED" ;
VAL_ 1280 DEM152_SC_CN_HIGH_CY_BMS01 3 "DEM_INVALID" 2 "DEM_FAILED" 1 "DEM_PASSED" 0 "DEM_NOTTESTED" ;
VAL_ 1280 DEM153_SC_CN_ISOANDPOTWELD_BMS01 3 "DEM_INVALID" 2 "DEM_FAILED" 1 "DEM_PASSED" 0 "DEM_NOTTESTED" ;
VAL_ 1280 DEM154_SC_TEMP_PLAUSI_BMS01 3 "DEM_INVALID" 2 "DEM_FAILED" 1 "DEM_PASSED" 0 "DEM_NOTTESTED" ;
VAL_ 1280 DEM155_SC_CURR_HALL_PWR_HI_BMS01 3 "DEM_INVALID" 2 "DEM_FAILED" 1 "DEM_PASSED" 0 "DEM_NOTTESTED" ;
VAL_ 1280 DEM156_SC_PYRO_TRIGGERED_BMS01 3 "DEM_INVALID" 2 "DEM_FAILED" 1 "DEM_PASSED" 0 "DEM_NOTTESTED" ;
VAL_ 1280 DEM157_SC_PYRO_OPEN_BMS01 3 "DEM_INVALID" 2 "DEM_FAILED" 1 "DEM_PASSED" 0 "DEM_NOTTESTED" ;
VAL_ 1280 DEM158_AUX_CTRS_END_OF_LIF_BMS01 3 "DEM_INVALID" 2 "DEM_FAILED" 1 "DEM_PASSED" 0 "DEM_NOTTESTED" ;
VAL_ 1280 DEM159_SC_CANRX_PT_MIA_BMS01 3 "DEM_INVALID" 2 "DEM_FAILED" 1 "DEM_PASSED" 0 "DEM_NOTTESTED" ;
VAL_ 1344 DEM160_SC_CANRX_PT_CRCALIV_BMS01 3 "DEM_INVALID" 2 "DEM_FAILED" 1 "DEM_PASSED" 0 "DEM_NOTTESTED" ;
VAL_ 1344 DEM161_SC_CANRX_LIN_SHUTDN_BMS01 3 "DEM_INVALID" 2 "DEM_FAILED" 1 "DEM_PASSED" 0 "DEM_NOTTESTED" ;
VAL_ 1344 DEM162_SC_CANRX_LIN_MIA_BMS01 3 "DEM_INVALID" 2 "DEM_FAILED" 1 "DEM_PASSED" 0 "DEM_NOTTESTED" ;
VAL_ 1344 DEM163_SC_CRASH1_BMS01 3 "DEM_INVALID" 2 "DEM_FAILED" 1 "DEM_PASSED" 0 "DEM_NOTTESTED" ;
VAL_ 1344 DEM164_SC_CRASH2_BMS01 3 "DEM_INVALID" 2 "DEM_FAILED" 1 "DEM_PASSED" 0 "DEM_NOTTESTED" ;
VAL_ 1344 DEM165_SC_CRASHCAN_BMS01 3 "DEM_INVALID" 2 "DEM_FAILED" 1 "DEM_PASSED" 0 "DEM_NOTTESTED" ;
VAL_ 1344 DEM166_SC_CCTRL_SELFTEST_BMS01 3 "DEM_INVALID" 2 "DEM_FAILED" 1 "DEM_PASSED" 0 "DEM_NOTTESTED" ;
VAL_ 1344 DEM167_SC_CCTRL_DRIVER_FAU_BMS01 3 "DEM_INVALID" 2 "DEM_FAILED" 1 "DEM_PASSED" 0 "DEM_NOTTESTED" ;
VAL_ 1344 DEM168_SC_CCTRL_HISIDESTCL_BMS01 3 "DEM_INVALID" 2 "DEM_FAILED" 1 "DEM_PASSED" 0 "DEM_NOTTESTED" ;
VAL_ 1344 DEM169_SC_CCTRL_HISIDESTOP_BMS01 3 "DEM_INVALID" 2 "DEM_FAILED" 1 "DEM_PASSED" 0 "DEM_NOTTESTED" ;
VAL_ 1344 DEM170_SC_CCTRL_LOSIDESTCL_BMS01 3 "DEM_INVALID" 2 "DEM_FAILED" 1 "DEM_PASSED" 0 "DEM_NOTTESTED" ;
VAL_ 1344 DEM171_SC_CCTRL_HVCNDITION_BMS01 3 "DEM_INVALID" 2 "DEM_FAILED" 1 "DEM_PASSED" 0 "DEM_NOTTESTED" ;
VAL_ 1344 DEM172_SC_CCTRL_POS1_OPN_BMS01 3 "DEM_INVALID" 2 "DEM_FAILED" 1 "DEM_PASSED" 0 "DEM_NOTTESTED" ;
VAL_ 1344 DEM173_SC_CCTRL_POS2_OPN_BMS01 3 "DEM_INVALID" 2 "DEM_FAILED" 1 "DEM_PASSED" 0 "DEM_NOTTESTED" ;
VAL_ 1344 DEM174_SC_CCTRL_POS3_OPN_BMS01 3 "DEM_INVALID" 2 "DEM_FAILED" 1 "DEM_PASSED" 0 "DEM_NOTTESTED" ;
VAL_ 1344 DEM175_SC_CCTRL_NEG1_OPN_BMS01 3 "DEM_INVALID" 2 "DEM_FAILED" 1 "DEM_PASSED" 0 "DEM_NOTTESTED" ;
VAL_ 1344 DEM176_SC_CCTRL_NEG2_OPN_BMS01 3 "DEM_INVALID" 2 "DEM_FAILED" 1 "DEM_PASSED" 0 "DEM_NOTTESTED" ;
VAL_ 1344 DEM177_SC_CCTRL_PRE2_OPN_BMS01 3 "DEM_INVALID" 2 "DEM_FAILED" 1 "DEM_PASSED" 0 "DEM_NOTTESTED" ;
VAL_ 1344 DEM178_SC_CCTRL_PRE1_OPN_BMS01 3 "DEM_INVALID" 2 "DEM_FAILED" 1 "DEM_PASSED" 0 "DEM_NOTTESTED" ;
VAL_ 1344 DEM179_SC_CCTRL_LOSIDESTOP_BMS01 3 "DEM_INVALID" 2 "DEM_FAILED" 1 "DEM_PASSED" 0 "DEM_NOTTESTED" ;
VAL_ 1344 DEM180_SC_CCTRL_UNEXPECTED_BMS01 3 "DEM_INVALID" 2 "DEM_FAILED" 1 "DEM_PASSED" 0 "DEM_NOTTESTED" ;
VAL_ 1344 DEM181_SC_V_OUT_OF_RANGE_BMS01 3 "DEM_INVALID" 2 "DEM_FAILED" 1 "DEM_PASSED" 0 "DEM_NOTTESTED" ;
VAL_ 1344 DEM182_SC_V_LATCHED_UVOV_BMS01 3 "DEM_INVALID" 2 "DEM_FAILED" 1 "DEM_PASSED" 0 "DEM_NOTTESTED" ;
VAL_ 1344 DEM183_ISO_EXT_STRAT_2_BMS01 3 "DEM_INVALID" 2 "DEM_FAILED" 1 "DEM_PASSED" 0 "DEM_NOTTESTED" ;
VAL_ 1344 DEM184_SC_CANTX_CTRS_BMS01 3 "DEM_INVALID" 2 "DEM_FAILED" 1 "DEM_PASSED" 0 "DEM_NOTTESTED" ;
VAL_ 1344 DEM185_SC_CANTX_HVIL_BMS01 3 "DEM_INVALID" 2 "DEM_FAILED" 1 "DEM_PASSED" 0 "DEM_NOTTESTED" ;
VAL_ 1344 DEM186_SC_CANTX_ISOL_BMS01 3 "DEM_INVALID" 2 "DEM_FAILED" 1 "DEM_PASSED" 0 "DEM_NOTTESTED" ;
VAL_ 1344 DEM187_SC_SBC_WATCHDOG_BMS01 3 "DEM_INVALID" 2 "DEM_FAILED" 1 "DEM_PASSED" 0 "DEM_NOTTESTED" ;
VAL_ 1344 DEM188_SC_SBC_FAULT_BMS01 3 "DEM_INVALID" 2 "DEM_FAILED" 1 "DEM_PASSED" 0 "DEM_NOTTESTED" ;
VAL_ 1344 DEM189_SC_WATCHDOG_BMS01 3 "DEM_INVALID" 2 "DEM_FAILED" 1 "DEM_PASSED" 0 "DEM_NOTTESTED" ;
VAL_ 1344 DEM190_SC_SELFTEST_RAM_BMS01 3 "DEM_INVALID" 2 "DEM_FAILED" 1 "DEM_PASSED" 0 "DEM_NOTTESTED" ;
VAL_ 1344 DEM191_SC_SELFTEST_FLASH_BMS01 3 "DEM_INVALID" 2 "DEM_FAILED" 1 "DEM_PASSED" 0 "DEM_NOTTESTED" ;
VAL_ 1408 DEM192_CMB_ONBOARDRH_OH_BMS01 3 "DEM_INVALID" 2 "DEM_FAILED" 1 "DEM_PASSED" 0 "DEM_NOTTESTED" ;
VAL_ 1408 DEM193_CMB_ONBOARDRH_SNA_BMS01 3 "DEM_INVALID" 2 "DEM_FAILED" 1 "DEM_PASSED" 0 "DEM_NOTTESTED" ;
VAL_ 1408 DEM194_CMB_ONBOARDT_OT_BMS01 3 "DEM_INVALID" 2 "DEM_FAILED" 1 "DEM_PASSED" 0 "DEM_NOTTESTED" ;
VAL_ 1408 DEM195_CMB_ONBOARDT_CHANGE_BMS01 3 "DEM_INVALID" 2 "DEM_FAILED" 1 "DEM_PASSED" 0 "DEM_NOTTESTED" ;
VAL_ 1408 DEM196_PRESSURE_CHANGE_BMS01 3 "DEM_INVALID" 2 "DEM_FAILED" 1 "DEM_PASSED" 0 "DEM_NOTTESTED" ;
VAL_ 1408 DEM197_PRESSURE_OVER_BMS01 3 "DEM_INVALID" 2 "DEM_FAILED" 1 "DEM_PASSED" 0 "DEM_NOTTESTED" ;
VAL_ 1408 DEM198_PRESSURE_UNDER_BMS01 3 "DEM_INVALID" 2 "DEM_FAILED" 1 "DEM_PASSED" 0 "DEM_NOTTESTED" ;
VAL_ 1408 DEM199_PRESSURE_INVALID_BMS01 3 "DEM_INVALID" 2 "DEM_FAILED" 1 "DEM_PASSED" 0 "DEM_NOTTESTED" ;
VAL_ 1408 DEM200_THERMAL_EVENT_BMS01 3 "DEM_INVALID" 2 "DEM_FAILED" 1 "DEM_PASSED" 0 "DEM_NOTTESTED" ;
VAL_ 1408 DEM201_CMB_ONBOARDT_SNA_BMS01 3 "DEM_INVALID" 2 "DEM_FAILED" 1 "DEM_PASSED" 0 "DEM_NOTTESTED" ;
VAL_ 1408 DEM202_REPLACE_DESICCANT_BMS01 3 "DEM_INVALID" 2 "DEM_FAILED" 1 "DEM_PASSED" 0 "DEM_NOTTESTED" ;
VAL_ 1408 DEM203_COOLANT_FLOOD_FAULT_BMS01 3 "DEM_INVALID" 2 "DEM_FAILED" 1 "DEM_PASSED" 0 "DEM_NOTTESTED" ;
VAL_ 1408 DEM204_LOW_BRICKCAPACITY_BMS01 3 "DEM_INVALID" 2 "DEM_FAILED" 1 "DEM_PASSED" 0 "DEM_NOTTESTED" ;
VAL_ 1408 DEM205_BMS_ONBOARDT_OT_BMS01 3 "DEM_INVALID" 2 "DEM_FAILED" 1 "DEM_PASSED" 0 "DEM_NOTTESTED" ;
VAL_ 1408 DEM206_HUMIDITY_CHANGE_BMS01 3 "DEM_INVALID" 2 "DEM_FAILED" 1 "DEM_PASSED" 0 "DEM_NOTTESTED" ;
VAL_ 1408 DEM207_ISENSE_SUPPLY_CURR_BMS01 3 "DEM_INVALID" 2 "DEM_FAILED" 1 "DEM_PASSED" 0 "DEM_NOTTESTED" ;
VAL_ 1408 DEM208_SOC_LOW_BMS01 3 "DEM_INVALID" 2 "DEM_FAILED" 1 "DEM_PASSED" 0 "DEM_NOTTESTED" ;
VAL_ 1408 DEM209_SOC_TOOLOW_BMS01 3 "DEM_INVALID" 2 "DEM_FAILED" 1 "DEM_PASSED" 0 "DEM_NOTTESTED" ;
VAL_ 1408 DEM210_SOC_TOOHIGH_BMS01 3 "DEM_INVALID" 2 "DEM_FAILED" 1 "DEM_PASSED" 0 "DEM_NOTTESTED" ;
VAL_ 1408 DEM211_BALANCING_REQUIRED_BMS01 3 "DEM_INVALID" 2 "DEM_FAILED" 1 "DEM_PASSED" 0 "DEM_NOTTESTED" ;
VAL_ 1408 DEM212_DEEP_DISCHARGE_BMS01 3 "DEM_INVALID" 2 "DEM_FAILED" 1 "DEM_PASSED" 0 "DEM_NOTTESTED" ;
VAL_ 1408 DEM213_CAN1_BUS_OFF_BMS01 3 "DEM_INVALID" 2 "DEM_FAILED" 1 "DEM_PASSED" 0 "DEM_NOTTESTED" ;
VAL_ 1408 DEM214_CAN2_BUS_OFF_BMS01 3 "DEM_INVALID" 2 "DEM_FAILED" 1 "DEM_PASSED" 0 "DEM_NOTTESTED" ;
VAL_ 1408 DEM215_CAN3_BUS_OFF_BMS01 3 "DEM_INVALID" 2 "DEM_FAILED" 1 "DEM_PASSED" 0 "DEM_NOTTESTED" ;
VAL_ 1408 DEM216_OUTLET_NTC_RATNAL_BMS01 3 "DEM_INVALID" 2 "DEM_FAILED" 1 "DEM_PASSED" 0 "DEM_NOTTESTED" ;
VAL_ 1408 DEM217_FUSE_PACK_BMS01 3 "DEM_INVALID" 2 "DEM_FAILED" 1 "DEM_PASSED" 0 "DEM_NOTTESTED" ;
VAL_ 1408 DEM218_FUSE_B_OPEN_BMS01 3 "DEM_INVALID" 2 "DEM_FAILED" 1 "DEM_PASSED" 0 "DEM_NOTTESTED" ;
VAL_ 1408 DEM219_FUSE_C_OPEN_BMS01 3 "DEM_INVALID" 2 "DEM_FAILED" 1 "DEM_PASSED" 0 "DEM_NOTTESTED" ;
VAL_ 1408 DEM220_FUSE_D_OPEN_BMS01 3 "DEM_INVALID" 2 "DEM_FAILED" 1 "DEM_PASSED" 0 "DEM_NOTTESTED" ;
VAL_ 1408 DEM221_FUSE_E_OPEN_BMS01 3 "DEM_INVALID" 2 "DEM_FAILED" 1 "DEM_PASSED" 0 "DEM_NOTTESTED" ;
VAL_ 1408 DEM222_PUMP_DRY_RUN_BMS01 3 "DEM_INVALID" 2 "DEM_FAILED" 1 "DEM_PASSED" 0 "DEM_NOTTESTED" ;
VAL_ 1408 DEM223_PUMP_PERFORMANCE_BMS01 3 "DEM_INVALID" 2 "DEM_FAILED" 1 "DEM_PASSED" 0 "DEM_NOTTESTED" ;
VAL_ 1472 DEM224_PUMP_LIN_FAILURE_BMS01 3 "DEM_INVALID" 2 "DEM_FAILED" 1 "DEM_PASSED" 0 "DEM_NOTTESTED" ;
VAL_ 1472 DEM225_PUMP_SUPPLY_VOLTAGE_BMS01 3 "DEM_INVALID" 2 "DEM_FAILED" 1 "DEM_PASSED" 0 "DEM_NOTTESTED" ;
VAL_ 1472 DEM226_PUMP_RECOVERY_FAIL_BMS01 3 "DEM_INVALID" 2 "DEM_FAILED" 1 "DEM_PASSED" 0 "DEM_NOTTESTED" ;
VAL_ 1472 DEM227_CTR_POS_OPENED_BMS01 3 "DEM_INVALID" 2 "DEM_FAILED" 1 "DEM_PASSED" 0 "DEM_NOTTESTED" ;
VAL_ 1472 DEM228_CTR_NEG_OPENED_BMS01 3 "DEM_INVALID" 2 "DEM_FAILED" 1 "DEM_PASSED" 0 "DEM_NOTTESTED" ;
VAL_ 1472 DEM229_STRSET_SLAVE1_FAULT_BMS01 3 "DEM_INVALID" 2 "DEM_FAILED" 1 "DEM_PASSED" 0 "DEM_NOTTESTED" ;
VAL_ 1472 DEM230_STRSET_SLAVE2_FAULT_BMS01 3 "DEM_INVALID" 2 "DEM_FAILED" 1 "DEM_PASSED" 0 "DEM_NOTTESTED" ;
VAL_ 1472 DEM231_CTRSAUX_CLFAIL_HVON_BMS01 3 "DEM_INVALID" 2 "DEM_FAILED" 1 "DEM_PASSED" 0 "DEM_NOTTESTED" ;
VAL_ 1472 DEM232_CTRSAUX_CLFAIL_VDIF_BMS01 3 "DEM_INVALID" 2 "DEM_FAILED" 1 "DEM_PASSED" 0 "DEM_NOTTESTED" ;
VAL_ 1472 DEM233_CTRSAUX_POS1_OPENED_BMS01 3 "DEM_INVALID" 2 "DEM_FAILED" 1 "DEM_PASSED" 0 "DEM_NOTTESTED" ;
VAL_ 1472 DEM234_CTRSAUX_NEG1_OPENED_BMS01 3 "DEM_INVALID" 2 "DEM_FAILED" 1 "DEM_PASSED" 0 "DEM_NOTTESTED" ;
VAL_ 1472 DEM235_CTRSAUX_POS1_WELDED_BMS01 3 "DEM_INVALID" 2 "DEM_FAILED" 1 "DEM_PASSED" 0 "DEM_NOTTESTED" ;
VAL_ 1472 DEM236_CTRSAUX_NEG1_WELDED_BMS01 3 "DEM_INVALID" 2 "DEM_FAILED" 1 "DEM_PASSED" 0 "DEM_NOTTESTED" ;
VAL_ 1472 DEM237_CTRSAUX_POS1_PULLIN_BMS01 3 "DEM_INVALID" 2 "DEM_FAILED" 1 "DEM_PASSED" 0 "DEM_NOTTESTED" ;
VAL_ 1472 DEM238_CTRSAUX_NEG1_PULLIN_BMS01 3 "DEM_INVALID" 2 "DEM_FAILED" 1 "DEM_PASSED" 0 "DEM_NOTTESTED" ;
VAL_ 1472 DEM239_INLET_NTC_RATNAL_BMS01 3 "DEM_INVALID" 2 "DEM_FAILED" 1 "DEM_PASSED" 0 "DEM_NOTTESTED" ;
VAL_ 1472 DEM240_INLET_NTC_HI_BMS01 3 "DEM_INVALID" 2 "DEM_FAILED" 1 "DEM_PASSED" 0 "DEM_NOTTESTED" ;
VAL_ 1472 DEM241_INLET_NTC_LO_BMS01 3 "DEM_INVALID" 2 "DEM_FAILED" 1 "DEM_PASSED" 0 "DEM_NOTTESTED" ;
VAL_ 1472 DEM242_VOLTAGE_LINK2_RATNA_BMS01 3 "DEM_INVALID" 2 "DEM_FAILED" 1 "DEM_PASSED" 0 "DEM_NOTTESTED" ;
VAL_ 1472 DEM243_VOLTAGE_LINK2_HI_BMS01 3 "DEM_INVALID" 2 "DEM_FAILED" 1 "DEM_PASSED" 0 "DEM_NOTTESTED" ;
VAL_ 1472 DEM244_VOLTAGE_LINK2_LO_BMS01 3 "DEM_INVALID" 2 "DEM_FAILED" 1 "DEM_PASSED" 0 "DEM_NOTTESTED" ;
VAL_ 1472 DEM245_CMB_ONBOARD_IMPOSSI_BMS01 3 "DEM_INVALID" 2 "DEM_FAILED" 1 "DEM_PASSED" 0 "DEM_NOTTESTED" ;
VAL_ 1472 DEM246_VOLTAGE_LINK1_HI_BMS01 3 "DEM_INVALID" 2 "DEM_FAILED" 1 "DEM_PASSED" 0 "DEM_NOTTESTED" ;
VAL_ 1472 DEM247_VOLTAGE_LINK1_LO_BMS01 3 "DEM_INVALID" 2 "DEM_FAILED" 1 "DEM_PASSED" 0 "DEM_NOTTESTED" ;
VAL_ 1472 DEM248_NTC_SUPPLY_LO_BMS01 3 "DEM_INVALID" 2 "DEM_FAILED" 1 "DEM_PASSED" 0 "DEM_NOTTESTED" ;
VAL_ 1472 DEM249_NTC_SUPPLY_HI_BMS01 3 "DEM_INVALID" 2 "DEM_FAILED" 1 "DEM_PASSED" 0 "DEM_NOTTESTED" ;
VAL_ 1472 DEM250_VOLTAGE_LINK3_RATNA_BMS01 3 "DEM_INVALID" 2 "DEM_FAILED" 1 "DEM_PASSED" 0 "DEM_NOTTESTED" ;
VAL_ 1472 DEM251_VOLTAGE_LINK3_HI_BMS01 3 "DEM_INVALID" 2 "DEM_FAILED" 1 "DEM_PASSED" 0 "DEM_NOTTESTED" ;
VAL_ 1472 DEM252_VOLTAGE_LINK3_LO_BMS01 3 "DEM_INVALID" 2 "DEM_FAILED" 1 "DEM_PASSED" 0 "DEM_NOTTESTED" ;
VAL_ 1472 DEM253_BALANCING_STUCK_BMS01 3 "DEM_INVALID" 2 "DEM_FAILED" 1 "DEM_PASSED" 0 "DEM_NOTTESTED" ;
VAL_ 1472 DEM254_ARM_EXCEPTION_BMS01 3 "DEM_INVALID" 2 "DEM_FAILED" 1 "DEM_PASSED" 0 "DEM_NOTTESTED" ;
VAL_ 1472 DEM255_ERROR_HOOKS_BMS01 3 "DEM_INVALID" 2 "DEM_FAILED" 1 "DEM_PASSED" 0 "DEM_NOTTESTED" ;
VAL_ 832 DEM256_XCP_CAL_CHANGE_BMS01 3 "DEM_INVALID" 2 "DEM_FAILED" 1 "DEM_PASSED" 0 "DEM_NOTTESTED" ;
VAL_ 832 DEM257_XCP_CAL_PERM_CHANGE_BMS01 3 "DEM_INVALID" 2 "DEM_FAILED" 1 "DEM_PASSED" 0 "DEM_NOTTESTED" ;
VAL_ 832 DEM258_TASK_TIME_OVERFLOW_BMS01 3 "DEM_INVALID" 2 "DEM_FAILED" 1 "DEM_PASSED" 0 "DEM_NOTTESTED" ;
VAL_ 832 DEM259_ISO_CIRCUIT_BMS01 3 "DEM_INVALID" 2 "DEM_FAILED" 1 "DEM_PASSED" 0 "DEM_NOTTESTED" ;
VAL_ 832 DEM260_COOLANT_MOIST_FAULT_BMS01 3 "DEM_INVALID" 2 "DEM_FAILED" 1 "DEM_PASSED" 0 "DEM_NOTTESTED" ;
VAL_ 832 DEM261_COOLANT_FLOOD_WARN_BMS01 3 "DEM_INVALID" 2 "DEM_FAILED" 1 "DEM_PASSED" 0 "DEM_NOTTESTED" ;
VAL_ 832 DEM262_COOLANT_MOIST_WARN_BMS01 3 "DEM_INVALID" 2 "DEM_FAILED" 1 "DEM_PASSED" 0 "DEM_NOTTESTED" ;
VAL_ 832 DEM263_MODULET_IMPLAUSIBLE_BMS01 3 "DEM_INVALID" 2 "DEM_FAILED" 1 "DEM_PASSED" 0 "DEM_NOTTESTED" ;
VAL_ 832 DEM264_REQUEST_ON_WITH_HV__BMS01 3 "DEM_INVALID" 2 "DEM_FAILED" 1 "DEM_PASSED" 0 "DEM_NOTTESTED" ;
VAL_ 832 DEM265_CSERS_PCODE_BMS01 3 "DEM_INVALID" 2 "DEM_FAILED" 1 "DEM_PASSED" 0 "DEM_NOTTESTED" ;
VAL_ 832 DEM266_PRELIM_CNTR_CL_FAIL_BMS01 3 "DEM_INVALID" 2 "DEM_FAILED" 1 "DEM_PASSED" 0 "DEM_NOTTESTED" ;
VAL_ 832 DEM267_FLUIDLVL_LOW_BMS01 3 "DEM_INVALID" 2 "DEM_FAILED" 1 "DEM_PASSED" 0 "DEM_NOTTESTED" ;
VAL_ 832 DEM268_FLUIDLVL_FAILURE_BMS01 3 "DEM_INVALID" 2 "DEM_FAILED" 1 "DEM_PASSED" 0 "DEM_NOTTESTED" ;
VAL_ 832 DEM269_SC_COOLANT_CONTAM_BMS01 3 "DEM_INVALID" 2 "DEM_FAILED" 1 "DEM_PASSED" 0 "DEM_NOTTESTED" ;
VAL_ 832 DEM270_SC_COOLANT_MIA_BMS01 3 "DEM_INVALID" 2 "DEM_FAILED" 1 "DEM_PASSED" 0 "DEM_NOTTESTED" ;
VAL_ 832 DEM271_PRESSURE_VHI_BMS01 3 "DEM_INVALID" 2 "DEM_FAILED" 1 "DEM_PASSED" 0 "DEM_NOTTESTED" ;
VAL_ 832 DEM272_PRESSURE_VLO_BMS01 3 "DEM_INVALID" 2 "DEM_FAILED" 1 "DEM_PASSED" 0 "DEM_NOTTESTED" ;
VAL_ 832 DEM273_SC_COOLANT_FAIL_BMS01 3 "DEM_INVALID" 2 "DEM_FAILED" 1 "DEM_PASSED" 0 "DEM_NOTTESTED" ;
VAL_ 832 DEM274_CTRSAUX_POS2_OPENED_BMS01 3 "DEM_INVALID" 2 "DEM_FAILED" 1 "DEM_PASSED" 0 "DEM_NOTTESTED" ;
VAL_ 832 DEM275_CTRSAUX_POS3_OPENED_BMS01 3 "DEM_INVALID" 2 "DEM_FAILED" 1 "DEM_PASSED" 0 "DEM_NOTTESTED" ;
VAL_ 832 DEM276_CTRSAUX_POS2_WELDED_BMS01 3 "DEM_INVALID" 2 "DEM_FAILED" 1 "DEM_PASSED" 0 "DEM_NOTTESTED" ;
VAL_ 832 DEM277_CTRSAUX_POS3_WELDED_BMS01 3 "DEM_INVALID" 2 "DEM_FAILED" 1 "DEM_PASSED" 0 "DEM_NOTTESTED" ;
VAL_ 832 DEM278_CTRSAUX_POS2_PULLIN_BMS01 3 "DEM_INVALID" 2 "DEM_FAILED" 1 "DEM_PASSED" 0 "DEM_NOTTESTED" ;
VAL_ 832 DEM279_CTRSAUX_POS3_PULLIN_BMS01 3 "DEM_INVALID" 2 "DEM_FAILED" 1 "DEM_PASSED" 0 "DEM_NOTTESTED" ;
VAL_ 832 DEM280_CMB_HUMIDITY_TEMP_C_BMS01 3 "DEM_INVALID" 2 "DEM_FAILED" 1 "DEM_PASSED" 0 "DEM_NOTTESTED" ;
VAL_ 832 DEM281_THERMAL_EVENT_CMB_R_BMS01 3 "DEM_INVALID" 2 "DEM_FAILED" 1 "DEM_PASSED" 0 "DEM_NOTTESTED" ;
VAL_ 832 DEM282_CUS_BRICKOV_BMS01 3 "DEM_INVALID" 2 "DEM_FAILED" 1 "DEM_PASSED" 0 "DEM_NOTTESTED" ;
VAL_ 832 DEM283_CUS_BRICKUV_BMS01 3 "DEM_INVALID" 2 "DEM_FAILED" 1 "DEM_PASSED" 0 "DEM_NOTTESTED" ;
VAL_ 832 DEM284_CUS_OVERCHRG_BMS01 3 "DEM_INVALID" 2 "DEM_FAILED" 1 "DEM_PASSED" 0 "DEM_NOTTESTED" ;
VAL_ 832 DEM285_CUS_OVERDCHRG_BMS01 3 "DEM_INVALID" 2 "DEM_FAILED" 1 "DEM_PASSED" 0 "DEM_NOTTESTED" ;
VAL_ 832 DEM286_CUS_CURRENT_CHG_BMS01 3 "DEM_INVALID" 2 "DEM_FAILED" 1 "DEM_PASSED" 0 "DEM_NOTTESTED" ;
VAL_ 832 DEM287_CUS_CURRENT_DCHG_BMS01 3 "DEM_INVALID" 2 "DEM_FAILED" 1 "DEM_PASSED" 0 "DEM_NOTTESTED" ;
VAL_ 1600 selfTestStartupFault_SC01 6 "SELFTEST_PBIST_OTHER_RAM_FAULT" 5 "SELFTEST_PBIST_CPU_RAM_FAULT" 4 "SELFTEST_PBIST_ROM_FAULT" 3 "SELFTEST_PBIST_STC_ROM_FAULT" 2 "SELFTEST_STC_FAULT" 1 "SELFTEST_CPU_FAULT" 0 "SELFTEST_STARTUP_OK" ;
VAL_ 1600 sbcARTimerStatus_SC01 15 "SNA" 6 "SBC_AR_COMPLETE" 5 "SBC_AR_INTERRUPTED" 4 "SBC_AR_READ_SUCCESS" 3 "SBC_AR_STOPPED" 2 "SBC_AR_RUNTOSTOP" 0 "SBC_AR_INIT" 1 "SBC_AR_RUNNING" ;
VAL_ 1600 sbcARTimerValue_SC01 255 "SNA" ;
VAL_ 1600 cmbVAIndex_SC01 255 "CMB_NONE" ;
VAL_ 1600 minVACMB_SC01 65535 "SNA" ;
VAL_ 1600 maxVACMB_SC01 65535 "SNA" ;
VAL_ 1600 pumpInternalFaultError_SC01 1 "ERROR" 0 "NO_ERROR" ;
VAL_ 1600 pumpShortCircuitError_SC01 1 "ERROR" 0 "NO_ERROR" ;
VAL_ 1600 pumpElectricError_SC01 1 "ERROR" 0 "NO_ERROR" 3 "SNA" ;
VAL_ 1600 pumpPostRunMode_SC01 7 "SNA" 4 "SPEED_4" 3 "SPEED_3" 2 "SPEED_2" 1 "SPEED_1" 0 "NO_POST_RUN" ;
VAL_ 1600 pumpRsError_SC01 1 "ERROR" 0 "NO_ERROR" ;
VAL_ 1600 pumpWakeUpStatus_SC01 2 "NDEF2" 1 "ACTIVE_WUP" 0 "NO_WUP" 3 "SNA" ;
VAL_ 1600 pumpRpmMonStat_SC01 1 "NO_MON" 0 "MON_ACTIVE" 3 "SNA" ;
VAL_ 1600 pumpPwmInStat_SC01 1 "HIGH" 0 "LOW" 3 "SNA" ;
VAL_ 1600 pumpDiagTriggered_SC01 1 "TRUE" 0 "FALSE" ;
VAL_ 1600 pumpHwFault_SC01 1 "ERROR" 0 "NO_ERROR" ;
VAL_ 1600 pumpPumpState_SC01 6 "ERROR" 5 "HARDWARE_ERROR" 1 "RUN" 0 "IDLE" 7 "SNA" ;
VAL_ 1600 pumpBlockError_SC01 0 "NO_ERROR" 1 "ERROR" 3 "SNA" ;
VAL_ 1600 pumpLinError_SC01 1 "ERROR" 0 "NO_ERROR" ;
VAL_ 1600 pumpDryRun_SC01 1 "ERROR" 0 "NO_ERROR" 3 "SNA" ;
VAL_ 1600 pumpOverCurrent_SC01 1 "ERROR" 0 "NO_ERROR" 3 "SNA" ;
VAL_ 1600 pumpVoltageDeratingError_SC01 1 "ERROR" 0 "NO_ERROR" ;
VAL_ 1600 pumpSupVoltageError_SC01 1 "ERROR" 0 "NO_ERROR" 3 "SNA" ;
VAL_ 1600 pumpUnderVoltage_SC01 1 "ERROR" 0 "NO_ERROR" ;
VAL_ 1600 pumpOverVoltage_SC01 1 "ERROR" 0 "NO_ERROR" ;
VAL_ 1600 pumpTempProtect_SC01 1 "ERROR" 0 "NO_ERROR" ;
VAL_ 1600 pumpOverTempDeratingErr_SC01 1 "ERROR" 0 "NO_ERROR" ;
VAL_ 1600 pumpOverTemperature_SC01 1 "ERROR" 0 "NO_ERROR" 3 "SNA" ;
VAL_ 1600 pressure2_SC01 255 "SNA" ;
VAL_ 1600 cmbSM29ScoutTempIndex_SC01 255 "SNA" ;
VAL_ 1600 cmbSM19ScoutPDO_SC01 65535 "SNA" ;
VAL_ 1600 isolationResInternRelaxed_SC01 65535 "SNA" ;
VAL_ 1600 appTask500HzMaxAvg_SC01 255 "SNA" ;
VAL_ 1600 safetyHangLastLinkReg_SC01 -1 "SNA" ;
VAL_ 1600 safetyHangPresentLinkReg_SC01 -1 "SNA" ;
VAL_ 1600 safetyHangDataFaultStatus_SC01 -1 "SNA" ;
VAL_ 1600 safetyHangDataFaultAddr_SC01 -1 "SNA" ;
VAL_ 1600 safetyHangLastARMMode_SC01 255 "MODE_UNKNOWN" 6 "MODE_SYS" 5 "MODE_UND" 4 "MODE_ABT" 3 "MODE_SVC" 2 "MODE_IRQ" 1 "MODE_FIQ" 0 "MODE_USER" ;
VAL_ 1600 safetyHangPresARMMode_SC01 255 "MODE_UNKNOWN" 6 "MODE_SYS" 5 "MODE_UND" 4 "MODE_ABT" 3 "MODE_SVC" 2 "MODE_IRQ" 1 "MODE_FIQ" 0 "MODE_USER" ;
VAL_ 1600 safetyHangESMGrp3Reg_SC01 -1 "SNA" ;
VAL_ 1600 safetyHangInstrFaultStatus_SC01 -1 "SNA" ;
VAL_ 1600 safetyHangInstrFaultAddr_SC01 -1 "SNA" ;
VAL_ 1600 pressure_SC01 255 "SNA" ;
VAL_ 1600 cmbMaxSM33Diff_SC01 255 "SNA" ;
VAL_ 1600 cmbMinSM29Diff_SC01 255 "SNA" ;
VAL_ 1600 cmbMinSM4Diff_SC01 65535 "SNA" ;
VAL_ 1600 cmbMaxSM4Diff_SC01 65535 "SNA" ;
VAL_ 1600 cmbMinSM27Diff_SC01 65535 "SNA" ;
VAL_ 1600 cmbMaxSM27Diff_SC01 65535 "SNA" ;
VAL_ 1600 adcDriverFail_SC01 12 "ADCDRIVER_SBCSUPPLY_FF" 11 "ADCDRIVER_MUX960_FF" 10 "ADCDRIVER_MUX910_FF" 9 "ADCDRIVER_UNDEF" 8 "ADCDRIVER_ADCVAR" 7 "ADCDRIVER_SLEEP_FF" 6 "ADCDRIVER_PYRO_FF" 5 "ADCDRIVER_MUX710_FF" 4 "ADCDRIVER_MUX440_FF" 3 "ADCDRIVER_MUX302A_FF" 2 "ADCDRIVER_MUX301B_FF" 1 "ADCDRIVER_MUX301A_FF" 0 "ADCDRIVER_NO_ISSUE" ;
VAL_ 1600 mainUcHvilState_SC01 2 "CANTX_HVIL_CLOSE" 3 "CANTX_HVIL_SNA" 1 "CANTX_HVIL_OPEN" 0 "CANTX_HVIL_NOT_AVAIL" ;
VAL_ 1600 mainUcIntIsoErr_SC01 3 "ISOLATION_SNA" 2 "ISOLATION_ERR_OFF" 1 "ISOLATION_ERROR" 0 "ISOLATION_OK" ;
VAL_ 1600 mainUcExtIsoErr_SC01 3 "ISOLATION_SNA" 2 "ISOLATION_ERR_OFF" 1 "ISOLATION_ERROR" 0 "ISOLATION_OK" ;
VAL_ 1600 safetyUcThermalStatus_SC01 3 "THERMALEVENT_SNA" 2 "THERMALEVENT_WARN_2" 1 "THERMALEVENT_WARN_1" 0 "THERMALEVENT_NO_WARN" ;
VAL_ 1600 mainUcThermalStatus_SC01 3 "THERMALEVENT_SNA" 2 "THERMALEVENT_WARN_2" 1 "THERMALEVENT_WARN_1" 0 "THERMALEVENT_NO_WARN" ;
VAL_ 1600 selfTestDataFaultStatus_SC01 -1 "SNA" ;
VAL_ 1600 selfTestInstrFaultAddr_SC01 -1 "SNA" ;
VAL_ 1600 selfTestDataFaultAddr_SC01 -1 "SNA" ;
VAL_ 1600 selfTestInstrFaultStatus_SC01 -1 "SNA" ;
VAL_ 1600 internalIsolationError_SC01 3 "ISOLATION_SNA" 2 "ISOLATION_ERR_OFF" 1 "ISOLATION_ERROR" 0 "ISOLATION_OK" ;
VAL_ 1600 externalIsolationError_SC01 3 "ISOLATION_SNA" 2 "ISOLATION_ERR_OFF" 1 "ISOLATION_ERROR" 0 "ISOLATION_OK" ;
VAL_ 1600 isolationTestState_SC01 3 "ISOLATION_TEST_POSNEG" 2 "ISOLATION_TEST_NEG" 1 "ISOLATION_TEST_POS" 0 "ISOLATION_OFF" ;
VAL_ 1600 isolationResistanceIntern_SC01 65535 "SNA" ;
VAL_ 1600 isolationResistanceExtern_SC01 65535 "SNA" ;
VAL_ 1600 maxAdolV13Diff_SC01 65535 "SNA" ;
VAL_ 1600 pumpType_SC01 0 "PUMP_NONE" 1 "PUMP_MAL" 2 "PUMP_BOSCH" 3 "PUMP_JOMA" 4 "PUMP_MAHLE" 255 "SNA" ;
VAL_ 1600 pumpPhaseCurrent_SC01 255 "SNA" ;
VAL_ 1600 hvWithstandTestQual_SC01 1 "QUAL_ERROR" 0 "QUAL_VALID" ;
VAL_ 1600 currentModuleMax_SC01 65535 "SNA" ;
VAL_ 1600 currentModuleMin_SC01 65535 "SNA" ;
VAL_ 1600 maxCMBDieTemp_SC01 255 "SNA" ;
VAL_ 1600 minCMBDieTemp_SC01 255 "SNA" ;
VAL_ 1600 appTaskSpiRxTx_SC01 255 "SNA" ;
VAL_ 1600 variantCodingCounts_SC01 255 "SNA" ;
VAL_ 1600 cmbMaxUpdateTime_SC01 255 "SNA" ;
VAL_ 1600 pumpSetSpeed_SC01 255 "SNA" ;
VAL_ 1600 hvilResistance_SC01 255 "SNA" ;
VAL_ 1600 cmbAvgUpdateTime_SC01 255 "SNA" ;
VAL_ 1600 pumpTemperature_SC01 255 "SNA" ;
VAL_ 1600 pumpSpeed_SC01 255 "SNA" ;
VAL_ 1600 pumpVoltage_SC01 255 "SNA" ;
VAL_ 1600 pumpCurrent_SC01 255 "SNA" ;
VAL_ 1600 posLink3_SC01 65535 "SNA" ;
VAL_ 1600 negLink3_SC01 65535 "SNA" ;
VAL_ 1600 posLink2_SC01 65535 "SNA" ;
VAL_ 1600 negLink2_SC01 65535 "SNA" ;
VAL_ 1600 cmbNrOfSamples_SC01 65535 "SNA" ;
VAL_ 1600 cmbTaskTime_SC01 65535 "SNA" ;
VAL_ 1600 appTask500HzMax_SC01 255 "SNA" ;
VAL_ 1600 analogHallSense_SC01 65535 "SNA" ;
VAL_ 1600 cmbMaxDiagStepPeriodicity_SC01 255 "SNA" ;
VAL_ 1600 minBrickVoltageLimit_SC01 65535 "SNA" ;
VAL_ 1600 appTask100Hz_SC01 255 "SNA" ;
VAL_ 1600 appTask10Hz_SC01 255 "SNA" ;
VAL_ 1600 appTaskAnalog_SC01 255 "SNA" ;
VAL_ 1600 appTaskADC_SC01 255 "SNA" ;
VAL_ 1600 appTask500HzAvg_SC01 255 "SNA" ;
VAL_ 1600 appTaskSBC_SC01 255 "SNA" ;
VAL_ 1600 appTaskCMBDriver_SC01 255 "SNA" ;
VAL_ 1600 safetyInitTime_SC01 255 "SNA" ;
VAL_ 1600 debugSlowMpex_SC01 45 "S45" 44 "S44" 43 "S43" 42 "S42" 41 "S41" 0 "S00" 1 "S01" 2 "S02" 3 "S03" 4 "S04" 5 "S05" 6 "S06" 7 "S07" 8 "S08" 9 "S09" 10 "S10" 11 "S11" 12 "S12" 13 "S13" 14 "S14" 15 "S15" 16 "S16" 17 "S17" 18 "S18" 19 "S19" 20 "S20" 21 "S21" 22 "S22" 23 "S23" 24 "S24" 25 "S25" 26 "S26" 27 "S27" 28 "S28" 29 "S29" 30 "S30" 31 "S31" 32 "S32" 33 "S33" 34 "S34" 35 "S35" 36 "S36" 37 "S37" 38 "S38" 39 "S39" 40 "S40" ;
VAL_ 1600 mux440Gnd_SC01 255 "SNA" ;
VAL_ 1600 analogHallGain_SC01 65535 "SNA" ;
VAL_ 1600 analogHallOffset_SC01 255 "SNA" ;
VAL_ 1600 negPackPrime_SC01 65535 "SNA" ;
VAL_ 1600 posPackPrime_SC01 65535 "SNA" ;
VAL_ 1600 packVoltage_SC01 65535 "SNA" ;
VAL_ 1600 sleepTime_SC01 65535 "SNA" ;
VAL_ 1600 analogNegHVOffset_SC01 255 "SNA" ;
VAL_ 1600 analogPosHVOffset_SC01 255 "SNA" ;
VAL_ 1600 analogNegHVGain_SC01 65535 "SNA" ;
VAL_ 1600 analogPosHVGain_SC01 65535 "SNA" ;
VAL_ 1600 mux910Gnd_SC01 255 "SNA" ;
VAL_ 1600 mux960Gnd_SC01 255 "SNA" ;
VAL_ 1600 analogAddr5_SC01 65535 "SNA" ;
VAL_ 1600 analogAddr4_SC01 65535 "SNA" ;
VAL_ 1600 analogAddr3_SC01 65535 "SNA" ;
VAL_ 1600 analogAddr2_SC01 65535 "SNA" ;
VAL_ 1600 analogAddr1_SC01 65535 "SNA" ;
VAL_ 1600 analogAddr0_SC01 65535 "SNA" ;
VAL_ 1600 sbcVREF2P5_SC01 255 "SNA" ;
VAL_ 1600 mux910N3VRef_SC01 65535 "SNA" ;
VAL_ 1600 mux910P2P5VRef_SC01 65535 "SNA" ;
VAL_ 1600 analogHvilCurrentPWM_SC01 255 "SNA" ;
VAL_ 1600 analogSBCSupply_SC01 255 "SNA" ;
VAL_ 1600 analogHvilCurrent_SC01 255 "SNA" ;
VAL_ 1600 analogPressureSense_SC01 255 "SNA" ;
VAL_ 1600 analog5VSensorSupply_SC01 255 "SNA" ;
VAL_ 1600 analogPrechgRel2CoilMinus_SC01 255 "SNA" ;
VAL_ 1600 analogPrechgRel1CoilMinus_SC01 255 "SNA" ;
VAL_ 1600 analogNegCntr3CoilMinus_SC01 255 "SNA" ;
VAL_ 1600 analogNegCntr2CoilMinus_SC01 255 "SNA" ;
VAL_ 1600 analogNegCntr1CoilMinus_SC01 255 "SNA" ;
VAL_ 1600 analogPosCntr3CoilMinus_SC01 255 "SNA" ;
VAL_ 1600 analogPosCntr2CoilMinus_SC01 255 "SNA" ;
VAL_ 1600 analogPosCntr1CoilMinus_SC01 255 "SNA" ;
VAL_ 1600 minModuleTemperature_SC01 255 "SNA" ;
VAL_ 1600 maxModuleTemperature_SC01 255 "SNA" ;
VAL_ 1600 analogHvilReturn_SC01 255 "SNA" ;
VAL_ 1600 analog5VDSupply_SC01 255 "SNA" ;
VAL_ 1600 analogHvilOut_SC01 255 "SNA" ;
VAL_ 1600 analogCurrentSensor12V_SC01 255 "SNA" ;
VAL_ 1600 maxVREF2_SC01 65535 "SNA" ;
VAL_ 1600 minVREF2_SC01 65535 "SNA" ;
VAL_ 1600 hallCurrentOffset_SC01 65535 "SNA" ;
VAL_ 1600 sumOfCurrentsFiltered_SC01 65535 "SNA" ;
VAL_ 1600 hallCurrentAveraged_SC01 65535 "SNA" ;
VAL_ 1600 analogHallSupply_SC01 65535 "SNA" ;
VAL_ 1600 contactorControlPos1_SC01 4 "CTRCTRL_CTRFAIL" 3 "CTRCTRL_CTRON" 2 "CTRCTRL_CTRCHECK" 1 "CTRCTRL_ADDITIONAL_CTRCHECK" 0 "CTRCTRL_CTROFF" ;
VAL_ 1600 contactorControlNeg1_SC01 4 "CTRCTRL_CTRFAIL" 3 "CTRCTRL_CTRON" 2 "CTRCTRL_CTRCHECK" 1 "CTRCTRL_ADDITIONAL_CTRCHECK" 0 "CTRCTRL_CTROFF" ;
VAL_ 1600 contactorControlPre1_SC01 4 "CTRCTRL_CTRFAIL" 3 "CTRCTRL_CTRON" 2 "CTRCTRL_CTRCHECK" 1 "CTRCTRL_ADDITIONAL_CTRCHECK" 0 "CTRCTRL_CTROFF" ;
VAL_ 1600 contactorControlPos2_SC01 4 "CTRCTRL_CTRFAIL" 3 "CTRCTRL_CTRON" 2 "CTRCTRL_CTRCHECK" 1 "CTRCTRL_ADDITIONAL_CTRCHECK" 0 "CTRCTRL_CTROFF" ;
VAL_ 1600 contactorControlNeg2_SC01 4 "CTRCTRL_CTRFAIL" 3 "CTRCTRL_CTRON" 2 "CTRCTRL_CTRCHECK" 1 "CTRCTRL_ADDITIONAL_CTRCHECK" 0 "CTRCTRL_CTROFF" ;
VAL_ 1600 contactorControlPre2_SC01 4 "CTRCTRL_CTRFAIL" 3 "CTRCTRL_CTRON" 2 "CTRCTRL_CTRCHECK" 1 "CTRCTRL_ADDITIONAL_CTRCHECK" 0 "CTRCTRL_CTROFF" ;
VAL_ 1600 contactorControlPos3_SC01 4 "CTRCTRL_CTRFAIL" 3 "CTRCTRL_CTRON" 2 "CTRCTRL_CTRCHECK" 1 "CTRCTRL_ADDITIONAL_CTRCHECK" 0 "CTRCTRL_CTROFF" ;
VAL_ 1600 contactorControlNeg3_SC01 4 "CTRCTRL_CTRFAIL" 3 "CTRCTRL_CTRON" 2 "CTRCTRL_CTRCHECK" 1 "CTRCTRL_ADDITIONAL_CTRCHECK" 0 "CTRCTRL_CTROFF" ;
